VERSION "created by canmatrix"

NS_ :

BS_:

BU_: BDC_Body CHC DME1 EME FLA NiVi ZGW Kombi Kombi_Basis Diagnosetool_FA_CAN CDC_ZGW DME2 ELV Gliwa_T1_Host FA_CAN_Dummy

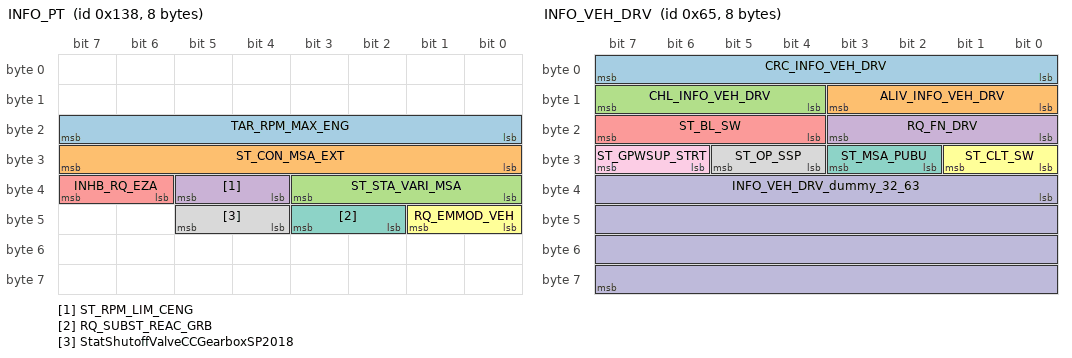
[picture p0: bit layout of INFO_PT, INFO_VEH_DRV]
BO_ 312 INFO_PT: 8 DME1
 SG_ TAR_RPM_MAX_ENG : 16|8@1+ (50,0) [0|630000] "1/min" Vector__XXX
 SG_ ST_CON_MSA_EXT : 24|8@1+ (1,0) [0|255] "" Vector__XXX
 SG_ ST_STA_VARI_MSA : 32|4@1+ (1,0) [0|15] "" Vector__XXX
 SG_ ST_RPM_LIM_CENG : 36|2@1+ (1,0) [0|3] "" Vector__XXX
 SG_ INHB_RQ_EZA : 38|2@1+ (1,0) [0|3] "" Vector__XXX
 SG_ RQ_EMMOD_VEH : 40|2@1+ (1,0) [0|3] "" BDC_Body
 SG_ RQ_SUBST_REAC_GRB : 42|2@1+ (1,0) [0|3] "" Vector__XXX
 SG_ StatShutoffValveCCGearboxSP2018 : 44|2@1+ (1,0) [0|3] "" Vector__XXX

BO_ 101 INFO_VEH_DRV: 8 BDC_Body
 SG_ CRC_INFO_VEH_DRV : 0|8@1+ (1,0) [0|255] "This unit fulfills the required AUTOSAR reference to a unit. No real unit is defined." Vector__XXX
 SG_ ALIV_INFO_VEH_DRV : 8|4@1+ (1,0) [0|14] "This unit fulfills the required AUTOSAR reference to a unit. No real unit is defined." Vector__XXX
 SG_ CHL_INFO_VEH_DRV : 12|4@1+ (1,0) [0|14] "This unit fulfills the required AUTOSAR reference to a unit. No real unit is defined." Vector__XXX
 SG_ RQ_FN_DRV : 16|4@1+ (1,0) [0|15] "" Vector__XXX
 SG_ ST_BL_SW : 20|4@1+ (1,0) [0|15] "" Vector__XXX
 SG_ ST_CLT_SW : 24|2@1+ (1,0) [0|3] "" Vector__XXX
 SG_ ST_MSA_PUBU : 26|2@1+ (1,0) [0|3] "" Vector__XXX
 SG_ ST_OP_SSP : 28|2@1+ (1,0) [0|3] "" Vector__XXX
 SG_ ST_GPWSUP_STRT : 30|2@1+ (1,0) [0|3] "" Vector__XXX
 SG_ INFO_VEH_DRV_dummy_32_63 : 32|32@1+ (1,0) [-2147483648|2147483647] "" Vector__XXX

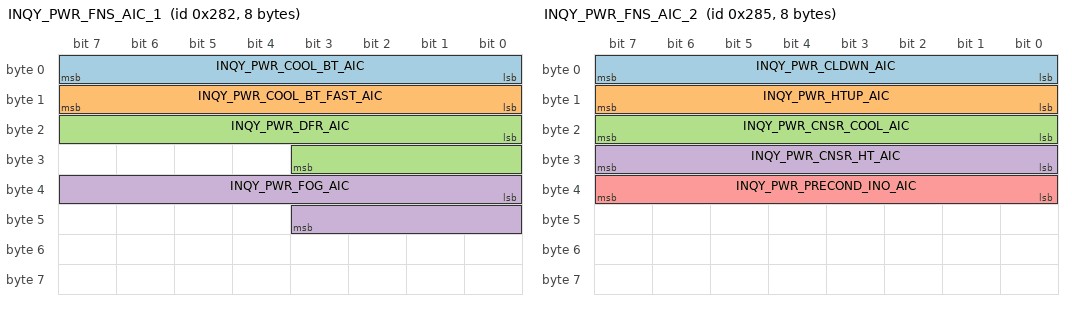
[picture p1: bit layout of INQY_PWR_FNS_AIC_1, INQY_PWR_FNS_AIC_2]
BO_ 642 INQY_PWR_FNS_AIC_1: 8 ZGW
 SG_ INQY_PWR_COOL_BT_AIC : 0|8@1+ (25,0) [0|157500] "W" EME
 SG_ INQY_PWR_COOL_BT_FAST_AIC : 8|8@1+ (25,0) [0|157500] "W" EME
 SG_ INQY_PWR_DFR_AIC : 16|12@1+ (25,0) [0|2557500] "W" EME
 SG_ INQY_PWR_FOG_AIC : 32|12@1+ (25,0) [0|2557500] "W" EME

BO_ 645 INQY_PWR_FNS_AIC_2: 8 ZGW
 SG_ INQY_PWR_CLDWN_AIC : 0|8@1+ (25,0) [0|157500] "W" EME
 SG_ INQY_PWR_HTUP_AIC : 8|8@1+ (25,0) [0|157500] "W" EME
 SG_ INQY_PWR_CNSR_COOL_AIC : 16|8@1+ (25,0) [0|157500] "W" EME
 SG_ INQY_PWR_CNSR_HT_AIC : 24|8@1+ (25,0) [0|157500] "W" EME
 SG_ INQY_PWR_PRECOND_INO_AIC : 32|8@1+ (25,0) [0|157500] "W" EME

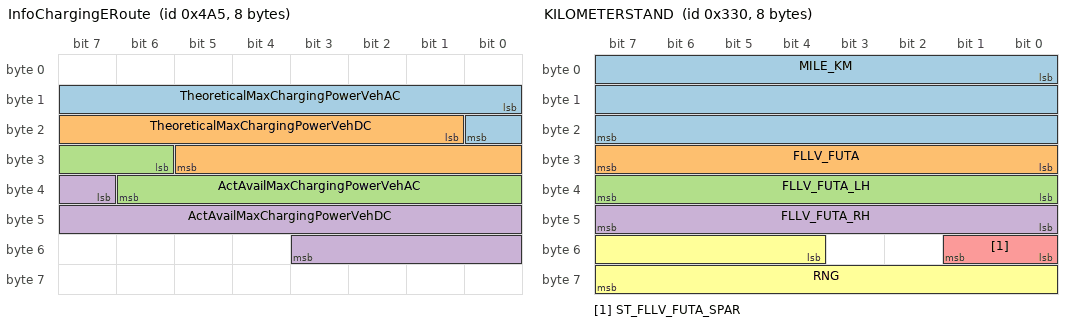
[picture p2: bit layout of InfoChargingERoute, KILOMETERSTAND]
BO_ 1189 InfoChargingERoute: 8 Vector__XXX
 SG_ TheoreticalMaxChargingPowerVehAC : 8|9@1+ (0.1,0) [0|5] "kW" Kombi
 SG_ TheoreticalMaxChargingPowerVehDC : 17|13@1+ (0.1,0) [0|50] "kW" Kombi
 SG_ ActAvailMaxChargingPowerVehAC : 30|9@1+ (0.1,0) [0|5] "kW" Kombi
 SG_ ActAvailMaxChargingPowerVehDC : 39|13@1+ (0.1,0) [0|50] "kW" Kombi

BO_ 816 KILOMETERSTAND: 8 Kombi
 SG_ MILE_KM : 0|24@1+ (1,0) [0|16777214] "km" CDC_ZGW,BDC_Body,FLA,ELV,EME,DME2,DME1,CHC,ZGW,NiVi
 SG_ FLLV_FUTA : 24|8@1+ (1,0) [0|254] "l" BDC_Body,EME,DME2,DME1,ZGW
 SG_ FLLV_FUTA_LH : 32|8@1+ (0.5,0) [0|63.5] "l" ZGW,DME2,DME1
 SG_ FLLV_FUTA_RH : 40|8@1+ (0.5,0) [0|63.5] "l" ZGW,DME2,DME1
 SG_ ST_FLLV_FUTA_SPAR : 48|2@1+ (1,0) [0|3] "" ZGW,DME2,DME1
 SG_ RNG : 52|12@1+ (1,0) [0|4094] "km" CDC_ZGW,BDC_Body,EME,DME2,DME1,ZGW

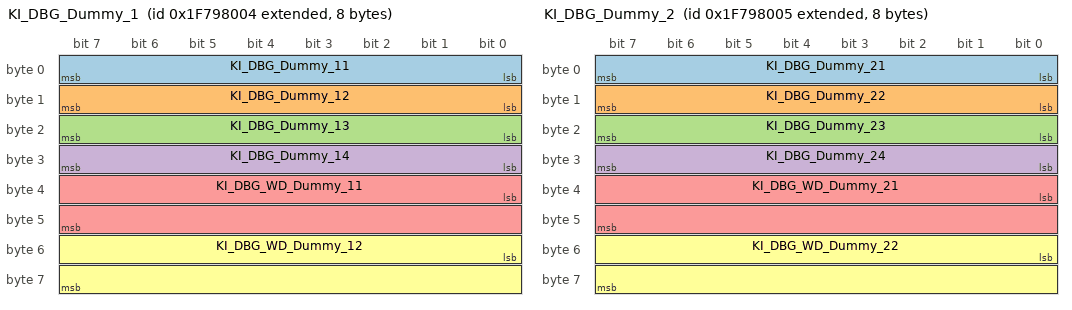
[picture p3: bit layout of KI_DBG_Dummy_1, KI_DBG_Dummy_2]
BO_ 2675539972 KI_DBG_Dummy_1: 8 Kombi
 SG_ KI_DBG_Dummy_11 : 0|8@1+ (1,0) [0|252] "This unit fulfills the required AUTOSAR reference to a unit. No real unit is defined." Vector__XXX
 SG_ KI_DBG_Dummy_12 : 8|8@1+ (1,0) [0|252] "This unit fulfills the required AUTOSAR reference to a unit. No real unit is defined." Vector__XXX
 SG_ KI_DBG_Dummy_13 : 16|8@1+ (1,0) [0|252] "This unit fulfills the required AUTOSAR reference to a unit. No real unit is defined." Vector__XXX
 SG_ KI_DBG_Dummy_14 : 24|8@1+ (1,0) [0|252] "This unit fulfills the required AUTOSAR reference to a unit. No real unit is defined." Vector__XXX
 SG_ KI_DBG_WD_Dummy_11 : 32|16@1+ (1,0) [0|65532] "This unit fulfills the required AUTOSAR reference to a unit. No real unit is defined." Vector__XXX
 SG_ KI_DBG_WD_Dummy_12 : 48|16@1+ (1,0) [0|65532] "This unit fulfills the required AUTOSAR reference to a unit. No real unit is defined." Vector__XXX

BO_ 2675539973 KI_DBG_Dummy_2: 8 Kombi
 SG_ KI_DBG_Dummy_21 : 0|8@1+ (1,0) [0|252] "This unit fulfills the required AUTOSAR reference to a unit. No real unit is defined." Vector__XXX
 SG_ KI_DBG_Dummy_22 : 8|8@1+ (1,0) [0|252] "This unit fulfills the required AUTOSAR reference to a unit. No real unit is defined." Vector__XXX
 SG_ KI_DBG_Dummy_23 : 16|8@1+ (1,0) [0|252] "This unit fulfills the required AUTOSAR reference to a unit. No real unit is defined." Vector__XXX
 SG_ KI_DBG_Dummy_24 : 24|8@1+ (1,0) [0|252] "This unit fulfills the required AUTOSAR reference to a unit. No real unit is defined." Vector__XXX
 SG_ KI_DBG_WD_Dummy_21 : 32|16@1+ (1,0) [0|65532] "This unit fulfills the required AUTOSAR reference to a unit. No real unit is defined." Vector__XXX
 SG_ KI_DBG_WD_Dummy_22 : 48|16@1+ (1,0) [0|65532] "This unit fulfills the required AUTOSAR reference to a unit. No real unit is defined." Vector__XXX

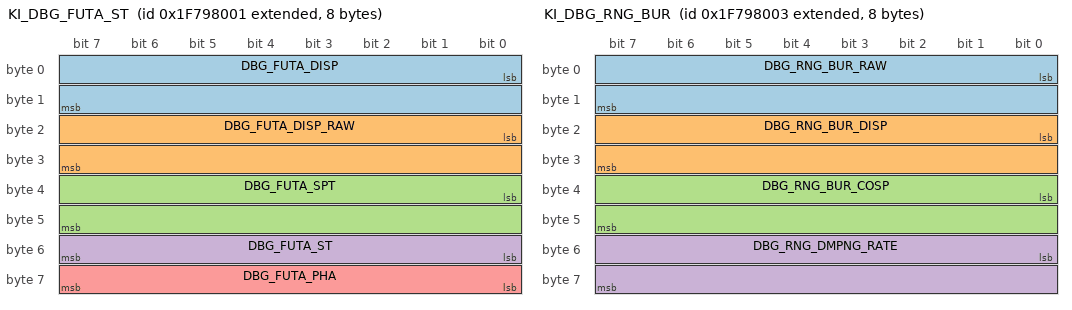
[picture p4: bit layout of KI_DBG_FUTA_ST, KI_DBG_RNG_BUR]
BO_ 2675539969 KI_DBG_FUTA_ST: 8 Kombi
 SG_ DBG_FUTA_DISP : 0|16@1+ (0.0078125,0) [0E-007|0.9921875] "l" Vector__XXX
 SG_ DBG_FUTA_DISP_RAW : 16|16@1+ (0.0078125,0) [0E-007|0.9921875] "l" Vector__XXX
 SG_ DBG_FUTA_SPT : 32|16@1+ (0.0078125,0) [0E-007|0.9921875] "l" Vector__XXX
 SG_ DBG_FUTA_ST : 48|8@1+ (1,0) [0|255] "" Vector__XXX
 SG_ DBG_FUTA_PHA : 56|8@1+ (1,0) [0|255] "" Vector__XXX

BO_ 2675539971 KI_DBG_RNG_BUR: 8 Kombi
 SG_ DBG_RNG_BUR_RAW : 0|16@1+ (1,0) [0|65532] "km" Vector__XXX
 SG_ DBG_RNG_BUR_DISP : 16|16@1+ (1,0) [0|65532] "km" Vector__XXX
 SG_ DBG_RNG_BUR_COSP : 32|16@1+ (0.001,0) [0.000|0.065532] "l/100km" Vector__XXX
 SG_ DBG_RNG_DMPNG_RATE : 48|16@1+ (1,0) [0|65532] "This unit fulfills the required AUTOSAR reference to a unit. No real unit is defined." Vector__XXX

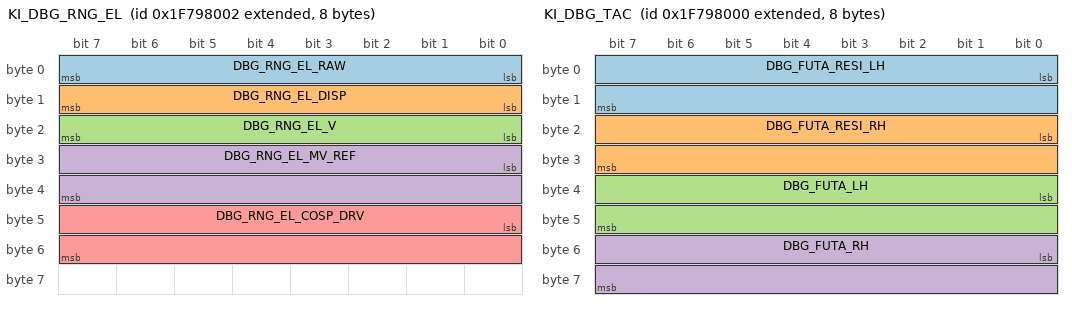
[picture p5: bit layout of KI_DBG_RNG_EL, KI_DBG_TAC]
BO_ 2675539970 KI_DBG_RNG_EL: 8 Kombi
 SG_ DBG_RNG_EL_RAW : 0|8@1+ (1,0) [0|252] "km" Vector__XXX
 SG_ DBG_RNG_EL_DISP : 8|8@1+ (1,0) [0|252] "km" Vector__XXX
 SG_ DBG_RNG_EL_V : 16|8@1+ (1,0) [0|252] "km" Vector__XXX
 SG_ DBG_RNG_EL_MV_REF : 24|16@1+ (1,0) [0|65532] "This unit fulfills the required AUTOSAR reference to a unit. No real unit is defined." Vector__XXX
 SG_ DBG_RNG_EL_COSP_DRV : 40|16@1+ (0.01,0) [0.00|6.5532] "Wh/km" Vector__XXX

BO_ 2675539968 KI_DBG_TAC: 8 Kombi
 SG_ DBG_FUTA_RESI_LH : 0|16@1+ (0.1,0) [0|655.3] "Ohm" Vector__XXX
 SG_ DBG_FUTA_RESI_RH : 16|16@1+ (0.1,0) [0|655.3] "Ohm" Vector__XXX
 SG_ DBG_FUTA_LH : 32|16@1+ (0.0078125,0) [0E-007|0.9921875] "l" Vector__XXX
 SG_ DBG_FUTA_RH : 48|16@1+ (0.0078125,0) [0E-007|0.9921875] "l" Vector__XXX

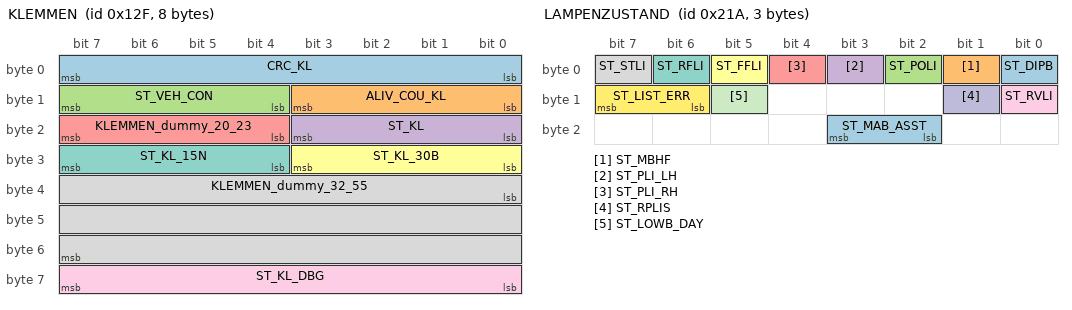
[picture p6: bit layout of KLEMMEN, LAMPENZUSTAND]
BO_ 303 KLEMMEN: 8 BDC_Body
 SG_ CRC_KL : 0|8@1+ (1,0) [0|255] "This unit fulfills the required AUTOSAR reference to a unit. No real unit is defined." Vector__XXX
 SG_ ALIV_COU_KL : 8|4@1+ (1,0) [0|15] "" Vector__XXX
 SG_ ST_VEH_CON : 12|4@1+ (1,0) [0|15] "" Vector__XXX
 SG_ ST_KL : 16|4@1+ (1,0) [0|15] "" Vector__XXX
 SG_ KLEMMEN_dummy_20_23 : 20|4@1+ (1,0) [-8|7] "" Vector__XXX
 SG_ ST_KL_30B : 24|4@1+ (1,0) [0|15] "" Vector__XXX
 SG_ ST_KL_15N : 28|4@1+ (1,0) [0|15] "" Vector__XXX
 SG_ KLEMMEN_dummy_32_55 : 32|24@1+ (1,0) [-8388608|8388607] "" Vector__XXX
 SG_ ST_KL_DBG : 56|8@1+ (1,0) [0|254] "This unit fulfills the required AUTOSAR reference to a unit. No real unit is defined." Vector__XXX

BO_ 413 Kilometerstand_2: 8 Kombi
 SG_ MILE_KM_TOT : 0|32@1+ (0.001,0) [0.000|4294.967292] "km" ZGW,DME2,DME1

BO_ 538 LAMPENZUSTAND: 3 BDC_Body
 SG_ ST_DIPB : 0|1@1+ (1,0) [0|1] "" ZGW,NiVi
 SG_ ST_MBHF : 1|1@1+ (1,0) [0|1] "" ZGW,Kombi,Kombi_Basis,NiVi
 SG_ ST_POLI : 2|1@1+ (1,0) [0|1] "" ZGW,Kombi,Kombi_Basis
 SG_ ST_PLI_LH : 3|1@1+ (1,0) [0|1] "" ZGW
 SG_ ST_PLI_RH : 4|1@1+ (1,0) [0|1] "" ZGW
 SG_ ST_FFLI : 5|1@1+ (1,0) [0|1] "" ZGW,Kombi,Kombi_Basis
 SG_ ST_RFLI : 6|1@1+ (1,0) [0|1] "" ZGW,Kombi,Kombi_Basis
 SG_ ST_STLI : 7|1@1+ (1,0) [0|1] "" ZGW
 SG_ ST_RVLI : 8|1@1+ (1,0) [0|1] "" ZGW
 SG_ ST_RPLIS : 9|1@1+ (1,0) [0|1] "" ZGW
 SG_ ST_LOWB_DAY : 13|1@1+ (1,0) [0|1] "" ZGW
 SG_ ST_LIST_ERR : 14|2@1+ (1,0) [0|3] "" ZGW
 SG_ ST_MAB_ASST : 18|2@1+ (1,0) [0|3] "" Kombi,Kombi_Basis

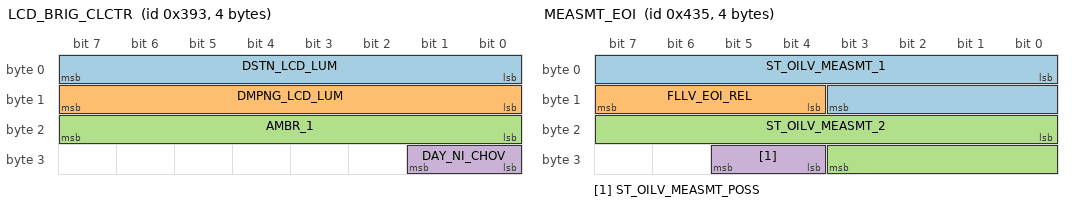
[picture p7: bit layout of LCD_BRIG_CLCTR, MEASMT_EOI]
BO_ 915 LCD_BRIG_CLCTR: 4 Kombi
 SG_ DSTN_LCD_LUM : 0|8@1+ (1,0) [0|254] "This unit fulfills the required AUTOSAR reference to a unit. No real unit is defined." ZGW,BDC_Body,CHC,DME1
 SG_ DMPNG_LCD_LUM : 8|8@1+ (2,100) [300|1260] "ms" ZGW,BDC_Body,CHC,DME1
 SG_ AMBR_1 : 16|8@1+ (1,0) [0|254] "This unit fulfills the required AUTOSAR reference to a unit. No real unit is defined." ZGW
 SG_ DAY_NI_CHOV : 24|2@1+ (1,0) [0|3] "" ZGW,BDC_Body

BO_ 577 LST_CHGSTN_IDT_CHGNG: 8 EME
 SG_ Multiplexor M : 0|8@1+ (1,0) [-128|127] "" Vector__XXX

BO_ 736 MASS_VEH: 6 ZGW
 SG_ MASS_VEH : 16|12@1+ (20,0) [0|163760] "kg" DME2,CHC,DME1
 SG_ QU_MASS_VEH : 28|4@1+ (1,0) [0|15] "" DME2,CHC,DME1

BO_ 1077 MEASMT_EOI: 4 DME1
 SG_ ST_OILV_MEASMT_1 : 0|12@1+ (1,0) [0|4095] "" ZGW
 SG_ FLLV_EOI_REL : 12|4@1+ (1,0) [0|15] "" ZGW,BDC_Body
 SG_ ST_OILV_MEASMT_2 : 16|12@1+ (1,0) [0|4095] "" ZGW
 SG_ ST_OILV_MEASMT_POSS : 28|2@1+ (1,0) [0|3] "" ZGW

BO_ 523 MEMORYVERSTELLUNG: 2 ZGW
 SG_ ST_MEMO_FN : 0|2@1+ (1,0) [0|3] "" Kombi
 SG_ PO_MEMO : 8|8@1+ (1,0) [1|254] "This unit fulfills the required AUTOSAR reference to a unit. No real unit is defined." Kombi

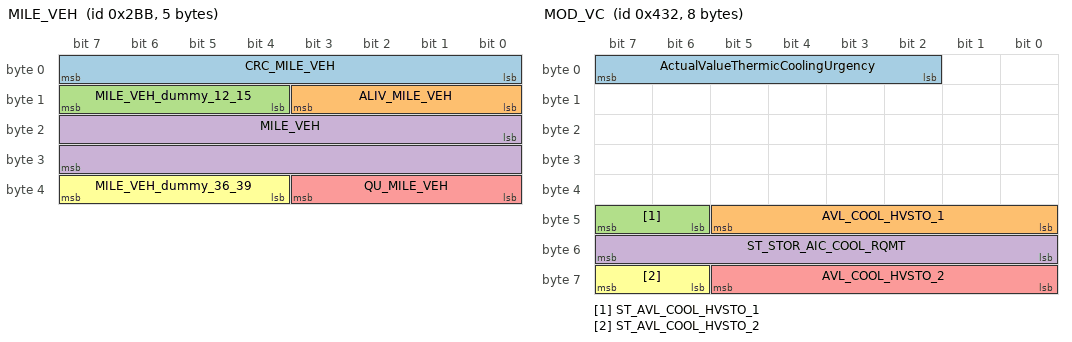
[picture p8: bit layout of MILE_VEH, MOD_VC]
BO_ 699 MILE_VEH: 5 ZGW
 SG_ CRC_MILE_VEH : 0|8@1+ (1,0) [0|255] "This unit fulfills the required AUTOSAR reference to a unit. No real unit is defined." Vector__XXX
 SG_ ALIV_MILE_VEH : 8|4@1+ (1,0) [0|14] "This unit fulfills the required AUTOSAR reference to a unit. No real unit is defined." Vector__XXX
 SG_ MILE_VEH_dummy_12_15 : 12|4@1+ (1,0) [-8|7] "" Vector__XXX
 SG_ MILE_VEH : 16|16@1+ (0.01,0) [0.00|6.5534] "m" Vector__XXX
 SG_ QU_MILE_VEH : 32|4@1+ (1,0) [0|15] "" Vector__XXX
 SG_ MILE_VEH_dummy_36_39 : 36|4@1+ (1,0) [-8|7] "" Vector__XXX

BO_ 1074 MOD_VC: 8 EME
 SG_ ActualValueThermicCoolingUrgency : 2|6@1+ (2,0) [0|200] "%" ZGW
 SG_ AVL_COOL_HVSTO_1 : 40|6@1+ (250,0) [0|3750000] "W" ZGW
 SG_ ST_AVL_COOL_HVSTO_1 : 46|2@1+ (1,0) [0|3] "" ZGW
 SG_ ST_STOR_AIC_COOL_RQMT : 48|8@1+ (20,0) [0|100800] "W" ZGW
 SG_ AVL_COOL_HVSTO_2 : 56|6@1+ (250,0) [0|3750000] "W" ZGW
 SG_ ST_AVL_COOL_HVSTO_2 : 62|2@1+ (1,0) [0|3] "" ZGW

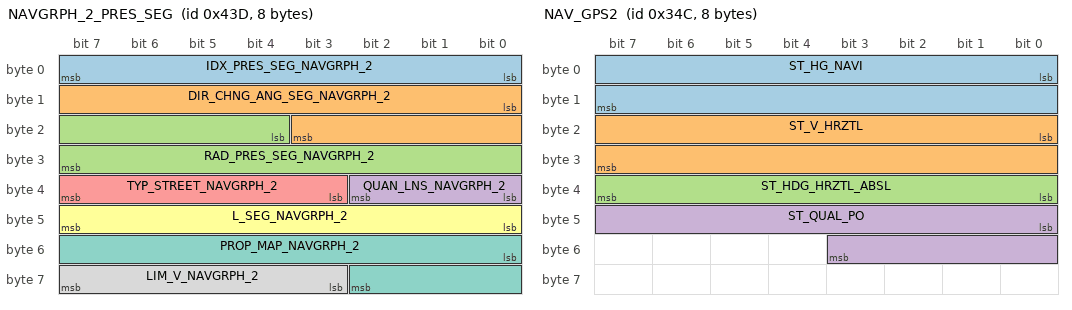
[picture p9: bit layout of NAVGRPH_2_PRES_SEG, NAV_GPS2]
BO_ 1085 NAVGRPH_2_PRES_SEG: 8 ZGW
 SG_ IDX_PRES_SEG_NAVGRPH_2 : 0|8@1+ (1,0) [0|254] "This unit fulfills the required AUTOSAR reference to a unit. No real unit is defined." BDC_Body
 SG_ DIR_CHNG_ANG_SEG_NAVGRPH_2 : 8|12@1+ (0.08793356,-180) [-195.82804080|-164.17195920] "°" BDC_Body
 SG_ RAD_PRES_SEG_NAVGRPH_2 : 20|12@1+ (5,-10230) [-61380|40970] "m" BDC_Body
 SG_ QUAN_LNS_NAVGRPH_2 : 32|3@1+ (1,0) [0|7] "" BDC_Body
 SG_ TYP_STREET_NAVGRPH_2 : 35|5@1+ (1,0) [0|31] "" BDC_Body
 SG_ L_SEG_NAVGRPH_2 : 40|8@1+ (1,0) [0|254] "m" BDC_Body
 SG_ PROP_MAP_NAVGRPH_2 : 48|11@1+ (1,0) [0|2047] "" BDC_Body
 SG_ LIM_V_NAVGRPH_2 : 59|5@1+ (1,0) [0|31] "" BDC_Body

BO_ 842 NAV_GPS1: 8 ZGW
 SG_ ST_LONG_NAVI : 0|32@1+ (8.38190318E-008,0) [-0.0000150874257240|0.00001509580762718] "°" NiVi,BDC_Body,DME2,DME1
 SG_ ST_LAT_NAVI : 32|32@1+ (8.38190318E-008,0) [-0.0000075437128620|0.00001509580762718] "°" NiVi,BDC_Body,DME2,DME1

BO_ 844 NAV_GPS2: 8 ZGW
 SG_ ST_HG_NAVI : 0|16@1+ (1,0) [-32767|32766] "m" BDC_Body
 SG_ ST_V_HRZTL : 16|16@1+ (1,0) [-32767|32766] "cm/s" BDC_Body
 SG_ ST_HDG_HRZTL_ABSL : 32|8@1+ (1.5,0) [0|540] "°" NiVi,BDC_Body
 SG_ ST_QUAL_PO : 40|12@1+ (1,0) [0|4095] "" NiVi,BDC_Body

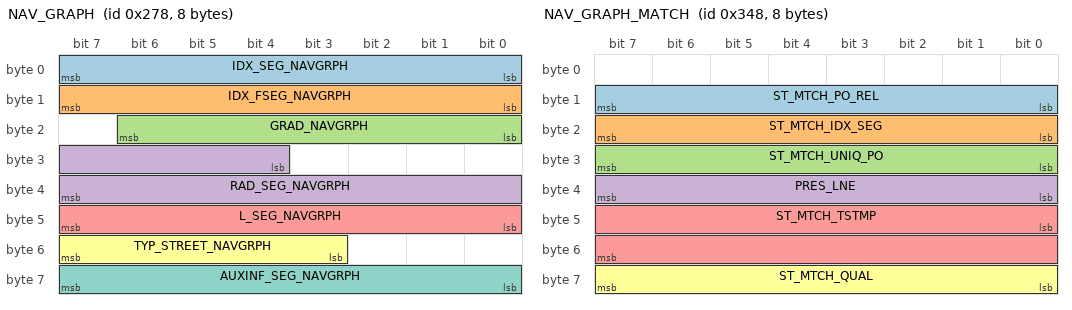
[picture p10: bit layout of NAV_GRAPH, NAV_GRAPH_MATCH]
BO_ 632 NAV_GRAPH: 8 ZGW
 SG_ IDX_SEG_NAVGRPH : 0|8@1+ (1,0) [0|254] "This unit fulfills the required AUTOSAR reference to a unit. No real unit is defined." NiVi
 SG_ IDX_FSEG_NAVGRPH : 8|8@1+ (1,0) [0|254] "This unit fulfills the required AUTOSAR reference to a unit. No real unit is defined." NiVi
 SG_ GRAD_NAVGRPH : 16|7@1+ (1,0) [0|126] "This unit fulfills the required AUTOSAR reference to a unit. No real unit is defined." NiVi
 SG_ RAD_SEG_NAVGRPH : 28|12@1+ (1,0) [-2047|2047] "This unit fulfills the required AUTOSAR reference to a unit. No real unit is defined." NiVi
 SG_ L_SEG_NAVGRPH : 40|8@1+ (1,0) [0|254] "m" NiVi
 SG_ TYP_STREET_NAVGRPH : 51|5@1+ (1,0) [0|31] "" NiVi
 SG_ AUXINF_SEG_NAVGRPH : 56|8@1+ (1,0) [0|255] "" NiVi

BO_ 840 NAV_GRAPH_MATCH: 8 ZGW
 SG_ ST_MTCH_PO_REL : 8|8@1+ (1,0) [0|254] "m" NiVi
 SG_ ST_MTCH_IDX_SEG : 16|8@1+ (1,0) [0|254] "This unit fulfills the required AUTOSAR reference to a unit. No real unit is defined." NiVi
 SG_ ST_MTCH_UNIQ_PO : 24|8@1+ (0.3937,0) [0.0000|39.36992126] "%" NiVi
 SG_ PRES_LNE : 32|8@1+ (1,0) [0|255] "" NiVi
 SG_ ST_MTCH_TSTMP : 40|16@1+ (1,0) [0|65534] "ms" NiVi
 SG_ ST_MTCH_QUAL : 56|8@1+ (0.3937,0) [0.0000|39.36992126] "%" NiVi

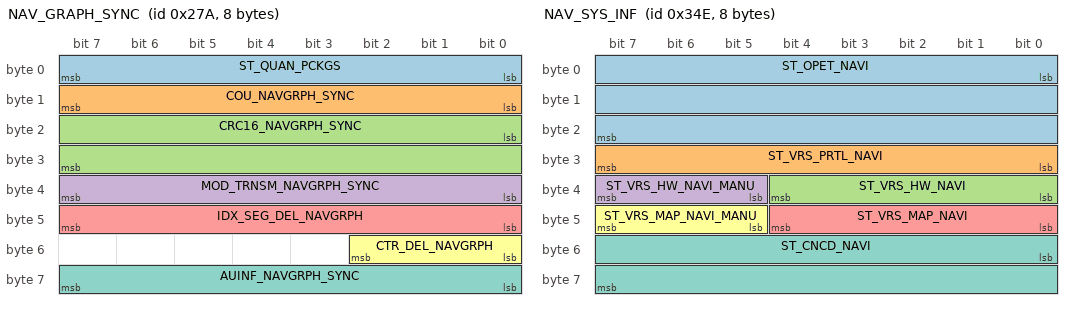
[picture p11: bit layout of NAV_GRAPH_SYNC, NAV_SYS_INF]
BO_ 634 NAV_GRAPH_SYNC: 8 ZGW
 SG_ ST_QUAN_PCKGS : 0|8@1+ (1,0) [0|254] "This unit fulfills the required AUTOSAR reference to a unit. No real unit is defined." NiVi
 SG_ COU_NAVGRPH_SYNC : 8|8@1+ (1,0) [0|254] "This unit fulfills the required AUTOSAR reference to a unit. No real unit is defined." NiVi
 SG_ CRC16_NAVGRPH_SYNC : 16|16@1+ (1,0) [0|65534] "This unit fulfills the required AUTOSAR reference to a unit. No real unit is defined." NiVi
 SG_ MOD_TRNSM_NAVGRPH_SYNC : 32|8@1+ (1,0) [0|254] "This unit fulfills the required AUTOSAR reference to a unit. No real unit is defined." NiVi
 SG_ IDX_SEG_DEL_NAVGRPH : 40|8@1+ (1,0) [0|254] "This unit fulfills the required AUTOSAR reference to a unit. No real unit is defined." NiVi
 SG_ CTR_DEL_NAVGRPH : 48|3@1+ (1,0) [0|7] "" NiVi
 SG_ AUINF_NAVGRPH_SYNC : 56|8@1+ (1,0) [0|255] "" NiVi

BO_ 846 NAV_SYS_INF: 8 ZGW
 SG_ ST_OPET_NAVI : 0|24@1+ (1,0) [0|16777214] "ms" BDC_Body,EME,DME2,DME1,NiVi
 SG_ ST_VRS_PRTL_NAVI : 24|8@1+ (1,0) [0|255] "" BDC_Body,EME,DME2,DME1,NiVi
 SG_ ST_VRS_HW_NAVI : 32|5@1+ (1,0) [0|31] "" BDC_Body,DME2,EME,DME1
 SG_ ST_VRS_HW_NAVI_MANU : 37|3@1+ (1,0) [0|7] "" BDC_Body,DME2,EME,DME1
 SG_ ST_VRS_MAP_NAVI : 40|5@1+ (1,0) [0|31] "" BDC_Body,DME2,EME,DME1
 SG_ ST_VRS_MAP_NAVI_MANU : 45|3@1+ (1,0) [0|7] "" BDC_Body,DME2,EME,DME1
 SG_ ST_CNCD_NAVI : 48|16@1+ (1,0) [0|65534] "This unit fulfills the required AUTOSAR reference to a unit. No real unit is defined." BDC_Body,EME,DME2,DME1,NiVi

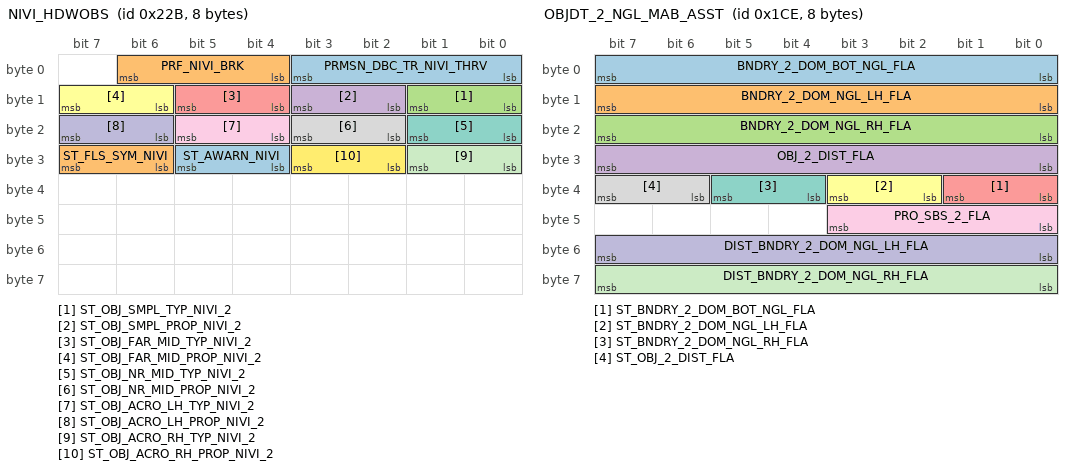
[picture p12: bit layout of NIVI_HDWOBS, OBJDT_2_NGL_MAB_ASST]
BO_ 555 NIVI_HDWOBS: 8 NiVi
 SG_ PRMSN_DBC_TR_NIVI_THRV : 0|4@1+ (1,0) [0|15] "" ZGW
 SG_ PRF_NIVI_BRK : 4|3@1+ (1,0) [0|7] "" ZGW
 SG_ ST_OBJ_SMPL_TYP_NIVI_2 : 8|2@1+ (1,0) [0|3] "" ZGW
 SG_ ST_OBJ_SMPL_PROP_NIVI_2 : 10|2@1+ (1,0) [0|3] "" ZGW
 SG_ ST_OBJ_FAR_MID_TYP_NIVI_2 : 12|2@1+ (1,0) [0|3] "" ZGW
 SG_ ST_OBJ_FAR_MID_PROP_NIVI_2 : 14|2@1+ (1,0) [0|3] "" ZGW
 SG_ ST_OBJ_NR_MID_TYP_NIVI_2 : 16|2@1+ (1,0) [0|3] "" ZGW
 SG_ ST_OBJ_NR_MID_PROP_NIVI_2 : 18|2@1+ (1,0) [0|3] "" ZGW
 SG_ ST_OBJ_ACRO_LH_TYP_NIVI_2 : 20|2@1+ (1,0) [0|3] "" ZGW
 SG_ ST_OBJ_ACRO_LH_PROP_NIVI_2 : 22|2@1+ (1,0) [0|3] "" ZGW
 SG_ ST_OBJ_ACRO_RH_TYP_NIVI_2 : 24|2@1+ (1,0) [0|3] "" ZGW
 SG_ ST_OBJ_ACRO_RH_PROP_NIVI_2 : 26|2@1+ (1,0) [0|3] "" ZGW
 SG_ ST_AWARN_NIVI : 28|2@1+ (1,0) [0|3] "" ZGW
 SG_ ST_FLS_SYM_NIVI : 30|2@1+ (1,0) [0|3] "" ZGW

BO_ 2024 OBD_ANSW_ECU_1: 8 DME1

BO_ 2025 OBD_ANSW_ECU_2: 8 DME1

BO_ 2026 OBD_ANSW_ECU_3: 8 DME1

BO_ 2027 OBD_ANSW_ECU_4: 8 DME1

BO_ 2028 OBD_ANSW_ECU_5: 8 DME1

BO_ 2029 OBD_ANSW_ECU_6: 8 DME1

BO_ 2030 OBD_ANSW_ECU_7: 8 DME1

BO_ 2031 OBD_ANSW_ECU_8: 8 DME1

BO_ 2016 OBD_RQ_ECU_1: 8 ZGW

BO_ 2017 OBD_RQ_ECU_2: 8 ZGW

BO_ 2018 OBD_RQ_ECU_3: 8 ZGW

BO_ 2019 OBD_RQ_ECU_4: 8 ZGW

BO_ 2020 OBD_RQ_ECU_5: 8 ZGW

BO_ 2021 OBD_RQ_ECU_6: 8 ZGW

BO_ 2022 OBD_RQ_ECU_7: 8 ZGW

BO_ 2023 OBD_RQ_ECU_8: 8 ZGW

BO_ 2015 OBD_RQ_FN: 8 ZGW

BO_ 462 OBJDT_2_NGL_MAB_ASST: 8 ZGW
 SG_ BNDRY_2_DOM_BOT_NGL_FLA : 0|8@1+ (0.05,-5) [-5.25|-4.75] "°" NiVi,BDC_Body
 SG_ BNDRY_2_DOM_NGL_LH_FLA : 8|8@1+ (0.1,-10.4) [-11.44|-8.9] "°" NiVi,BDC_Body
 SG_ BNDRY_2_DOM_NGL_RH_FLA : 16|8@1+ (0.1,-15) [-16.5|-13.96] "°" NiVi,BDC_Body
 SG_ OBJ_2_DIST_FLA : 24|8@1+ (1,0) [0|150] "m" NiVi,BDC_Body
 SG_ ST_BNDRY_2_DOM_BOT_NGL_FLA : 32|2@1+ (1,0) [0|3] "" NiVi,BDC_Body
 SG_ ST_BNDRY_2_DOM_NGL_LH_FLA : 34|2@1+ (1,0) [0|3] "" NiVi,BDC_Body
 SG_ ST_BNDRY_2_DOM_NGL_RH_FLA : 36|2@1+ (1,0) [0|3] "" NiVi,BDC_Body
 SG_ ST_OBJ_2_DIST_FLA : 38|2@1+ (1,0) [0|3] "" NiVi,BDC_Body
 SG_ PRO_SBS_2_FLA : 40|4@1+ (0.1,0) [0|0.1] "This unit fulfills the required AUTOSAR reference to a unit. No real unit is defined." NiVi,BDC_Body
 SG_ DIST_BNDRY_2_DOM_NGL_LH_FLA : 48|8@1+ (1,0) [0|252] "m" BDC_Body
 SG_ DIST_BNDRY_2_DOM_NGL_RH_FLA : 56|8@1+ (1,0) [0|252] "m" BDC_Body

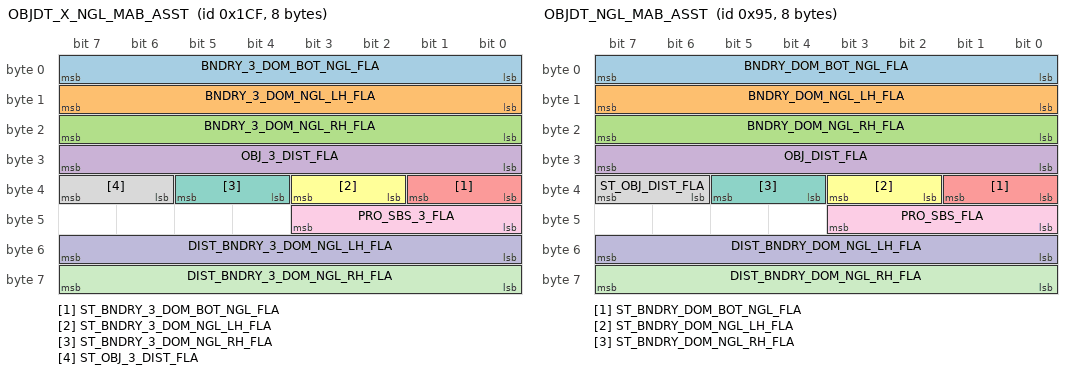
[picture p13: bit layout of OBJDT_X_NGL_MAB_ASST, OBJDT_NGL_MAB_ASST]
BO_ 463 OBJDT_X_NGL_MAB_ASST: 8 ZGW
 SG_ BNDRY_3_DOM_BOT_NGL_FLA : 0|8@1+ (0.05,-5) [-5.25|-4.75] "°" NiVi,BDC_Body
 SG_ BNDRY_3_DOM_NGL_LH_FLA : 8|8@1+ (0.1,-10.4) [-11.44|-8.9] "°" NiVi,BDC_Body
 SG_ BNDRY_3_DOM_NGL_RH_FLA : 16|8@1+ (0.1,-15) [-16.5|-13.96] "°" NiVi,BDC_Body
 SG_ OBJ_3_DIST_FLA : 24|8@1+ (1,0) [0|150] "m" NiVi,BDC_Body
 SG_ ST_BNDRY_3_DOM_BOT_NGL_FLA : 32|2@1+ (1,0) [0|3] "" NiVi,BDC_Body
 SG_ ST_BNDRY_3_DOM_NGL_LH_FLA : 34|2@1+ (1,0) [0|3] "" NiVi,BDC_Body
 SG_ ST_BNDRY_3_DOM_NGL_RH_FLA : 36|2@1+ (1,0) [0|3] "" NiVi,BDC_Body
 SG_ ST_OBJ_3_DIST_FLA : 38|2@1+ (1,0) [0|3] "" NiVi,BDC_Body
 SG_ PRO_SBS_3_FLA : 40|4@1+ (0.1,0) [0|0.1] "This unit fulfills the required AUTOSAR reference to a unit. No real unit is defined." NiVi,BDC_Body
 SG_ DIST_BNDRY_3_DOM_NGL_LH_FLA : 48|8@1+ (1,0) [0|252] "m" BDC_Body
 SG_ DIST_BNDRY_3_DOM_NGL_RH_FLA : 56|8@1+ (1,0) [0|252] "m" BDC_Body

BO_ 149 OBJDT_NGL_MAB_ASST: 8 FLA
 SG_ BNDRY_DOM_BOT_NGL_FLA : 0|8@1+ (0.05,-5) [-5.25|-4.75] "°" NiVi,BDC_Body
 SG_ BNDRY_DOM_NGL_LH_FLA : 8|8@1+ (0.1,-10.4) [-11.44|-8.9] "°" NiVi,BDC_Body
 SG_ BNDRY_DOM_NGL_RH_FLA : 16|8@1+ (0.1,-15) [-16.5|-13.96] "°" NiVi,BDC_Body
 SG_ OBJ_DIST_FLA : 24|8@1+ (1,0) [0|150] "m" NiVi,BDC_Body
 SG_ ST_BNDRY_DOM_BOT_NGL_FLA : 32|2@1+ (1,0) [0|3] "" NiVi,BDC_Body
 SG_ ST_BNDRY_DOM_NGL_LH_FLA : 34|2@1+ (1,0) [0|3] "" NiVi,BDC_Body
 SG_ ST_BNDRY_DOM_NGL_RH_FLA : 36|2@1+ (1,0) [0|3] "" NiVi,BDC_Body
 SG_ ST_OBJ_DIST_FLA : 38|2@1+ (1,0) [0|3] "" NiVi,BDC_Body
 SG_ PRO_SBS_FLA : 40|4@1+ (0.1,0) [0|0.1] "This unit fulfills the required AUTOSAR reference to a unit. No real unit is defined." NiVi,BDC_Body
 SG_ DIST_BNDRY_DOM_NGL_LH_FLA : 48|8@1+ (1,0) [0|252] "m" BDC_Body
 SG_ DIST_BNDRY_DOM_NGL_RH_FLA : 56|8@1+ (1,0) [0|252] "m" BDC_Body

BO_ 393 OP_CCTR: 6 ZGW
 SG_ OP_CCTR_OPEL_3 : 24|4@1+ (1,0) [0|15] "" DME1
 SG_ QU_SER_OP_CCTR : 40|8@1+ (1,0) [0|255] "" DME1

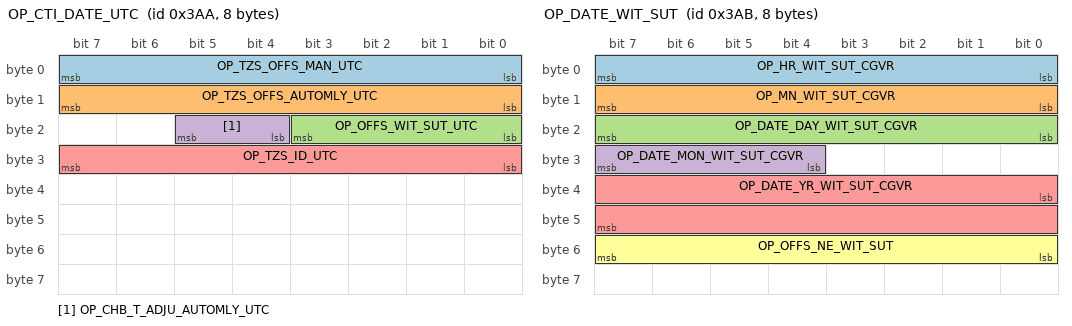
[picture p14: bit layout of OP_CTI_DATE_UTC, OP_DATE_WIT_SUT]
BO_ 938 OP_CTI_DATE_UTC: 8 ZGW
 SG_ OP_TZS_OFFS_MAN_UTC : 0|8@1+ (0.25,-20) [-25.00|-9.3125] "h" Kombi,Kombi_Basis
 SG_ OP_TZS_OFFS_AUTOMLY_UTC : 8|8@1+ (0.25,-20) [-25.00|-9.3125] "h" Kombi,Kombi_Basis
 SG_ OP_OFFS_WIT_SUT_UTC : 16|4@1+ (0.5,-3) [-4.5|-1.75] "h" Kombi,Kombi_Basis
 SG_ OP_CHB_T_ADJU_AUTOMLY_UTC : 20|2@1+ (1,0) [0|3] "" Kombi,Kombi_Basis
 SG_ OP_TZS_ID_UTC : 24|8@1+ (1,0) [0|251] "This unit fulfills the required AUTOSAR reference to a unit. No real unit is defined." Kombi,Kombi_Basis

BO_ 939 OP_DATE_WIT_SUT: 8 ZGW
 SG_ OP_HR_WIT_SUT_CGVR : 0|8@1+ (1,0) [0|251] "h" Kombi,Kombi_Basis
 SG_ OP_MN_WIT_SUT_CGVR : 8|8@1+ (1,0) [0|59] "min" Kombi,Kombi_Basis
 SG_ OP_DATE_DAY_WIT_SUT_CGVR : 16|8@1+ (1,0) [0|31] "This unit fulfills the required AUTOSAR reference to a unit. No real unit is defined." Kombi,Kombi_Basis
 SG_ OP_DATE_MON_WIT_SUT_CGVR : 28|4@1+ (1,0) [1|12] "This unit fulfills the required AUTOSAR reference to a unit. No real unit is defined." Kombi,Kombi_Basis
 SG_ OP_DATE_YR_WIT_SUT_CGVR : 32|16@1+ (1,0) [0|65531] "This unit fulfills the required AUTOSAR reference to a unit. No real unit is defined." Kombi,Kombi_Basis
 SG_ OP_OFFS_NE_WIT_SUT : 48|8@1+ (0.25,-20) [-25.00|-9.25] "h" Kombi,Kombi_Basis

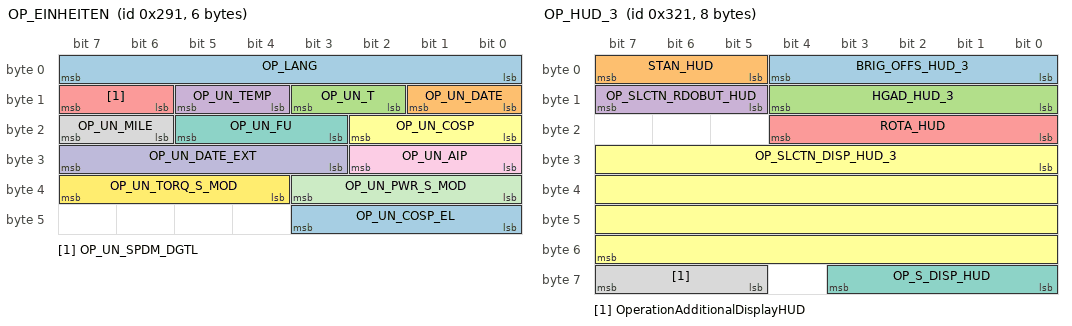
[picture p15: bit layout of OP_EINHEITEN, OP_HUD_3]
BO_ 657 OP_EINHEITEN: 6 ZGW
 SG_ OP_LANG : 0|8@1+ (1,0) [0|255] "" Kombi,Kombi_Basis
 SG_ OP_UN_DATE : 8|2@1+ (1,0) [0|3] "" Kombi,Kombi_Basis
 SG_ OP_UN_T : 10|2@1+ (1,0) [0|3] "" Kombi,Kombi_Basis
 SG_ OP_UN_TEMP : 12|2@1+ (1,0) [0|3] "" Kombi,Kombi_Basis
 SG_ OP_UN_SPDM_DGTL : 14|2@1+ (1,0) [0|3] "" Kombi,Kombi_Basis
 SG_ OP_UN_COSP : 16|3@1+ (1,0) [0|7] "" Kombi,Kombi_Basis
 SG_ OP_UN_FU : 19|3@1+ (1,0) [0|7] "" Kombi,Kombi_Basis
 SG_ OP_UN_MILE : 22|2@1+ (1,0) [0|3] "" Kombi,Kombi_Basis
 SG_ OP_UN_AIP : 24|3@1+ (1,0) [0|7] "" Kombi,Kombi_Basis
 SG_ OP_UN_DATE_EXT : 27|5@1+ (1,0) [0|31] "" Kombi,Kombi_Basis
 SG_ OP_UN_PWR_S_MOD : 32|4@1+ (1,0) [0|15] "" Kombi,Kombi_Basis
 SG_ OP_UN_TORQ_S_MOD : 36|4@1+ (1,0) [0|15] "" Kombi,Kombi_Basis
 SG_ OP_UN_COSP_EL : 40|4@1+ (1,0) [0|15] "" Kombi,Kombi_Basis

BO_ 801 OP_HUD_3: 8 ZGW
 SG_ BRIG_OFFS_HUD_3 : 0|5@1+ (1,0) [0|31] "" Kombi,Kombi_Basis
 SG_ STAN_HUD : 5|3@1+ (1,0) [0|7] "" Kombi,Kombi_Basis
 SG_ HGAD_HUD_3 : 8|5@1+ (1,0) [0|31] "" Kombi,Kombi_Basis
 SG_ OP_SLCTN_RDOBUT_HUD : 13|3@1+ (1,0) [0|7] "" Kombi,Kombi_Basis
 SG_ ROTA_HUD : 16|5@1+ (1,0) [0|31] "" Kombi,Kombi_Basis
 SG_ OP_SLCTN_DISP_HUD_3 : 24|32@1+ (1,0) [0|4294967295] "" Kombi,Kombi_Basis
 SG_ OP_S_DISP_HUD : 56|4@1+ (1,0) [0|15] "" Kombi,Kombi_Basis
 SG_ OperationAdditionalDisplayHUD : 61|3@1+ (1,0) [0|7] "" Kombi,Kombi_Basis

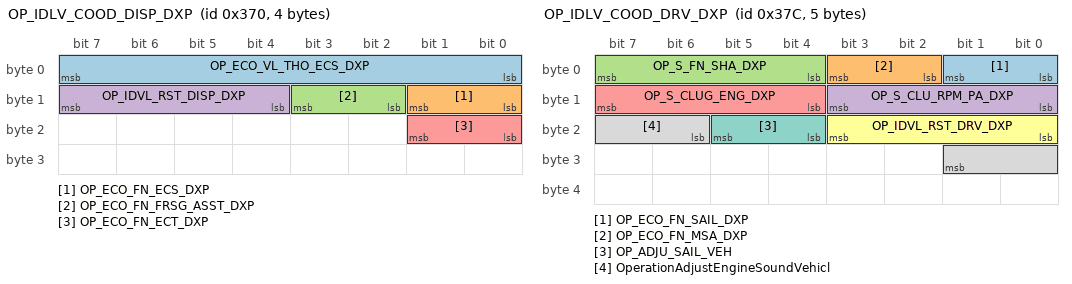
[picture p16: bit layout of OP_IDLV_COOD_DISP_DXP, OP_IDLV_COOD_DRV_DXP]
BO_ 880 OP_IDLV_COOD_DISP_DXP: 4 ZGW
 SG_ OP_ECO_VL_THO_ECS_DXP : 0|8@1+ (1,0) [0|250] "This unit fulfills the required AUTOSAR reference to a unit. No real unit is defined." Kombi,Kombi_Basis
 SG_ OP_ECO_FN_ECS_DXP : 8|2@1+ (1,0) [0|3] "" Kombi,Kombi_Basis
 SG_ OP_ECO_FN_FRSG_ASST_DXP : 10|2@1+ (1,0) [0|3] "" Kombi,Kombi_Basis
 SG_ OP_IDVL_RST_DISP_DXP : 12|4@1+ (1,0) [0|15] "" Kombi,Kombi_Basis
 SG_ OP_ECO_FN_ECT_DXP : 16|2@1+ (1,0) [0|3] "" Kombi,Kombi_Basis

BO_ 892 OP_IDLV_COOD_DRV_DXP: 5 ZGW
 SG_ OP_ECO_FN_SAIL_DXP : 0|2@1+ (1,0) [0|3] "" DME2,DME1
 SG_ OP_ECO_FN_MSA_DXP : 2|2@1+ (1,0) [0|3] "" DME2,DME1
 SG_ OP_S_FN_SHA_DXP : 4|4@1+ (1,0) [0|15] "" DME2,DME1
 SG_ OP_S_CLU_RPM_PA_DXP : 8|4@1+ (1,0) [0|15] "" DME2,DME1
 SG_ OP_S_CLUG_ENG_DXP : 12|4@1+ (1,0) [0|15] "" DME2,DME1
 SG_ OP_IDVL_RST_DRV_DXP : 16|4@1+ (1,0) [0|15] "" DME2,DME1
 SG_ OP_ADJU_SAIL_VEH : 20|2@1+ (1,0) [0|3] "" DME2,DME1
 SG_ OperationAdjustEngineSoundVehicl : 22|4@1+ (1,0) [0|15] "" DME2,DME1

BO_ 745 OP_PUBU_EVEH: 2 ZGW
 SG_ OP_PUBU_EVEH : 0|2@1+ (1,0) [0|3] "" DME2,DME1

BO_ 651 OP_PUBU_HUD: 2 BDC_Body
 SG_ OP_PUBU_HUD : 0|2@1+ (1,0) [0|3] "" Kombi,Kombi_Basis

BO_ 604 OP_PUBU_LVCH: 2 ZGW
 SG_ OP_PUBU_LVCH : 0|4@1+ (1,0) [0|15] "" CHC
 SG_ OP_PUBU_KEY : 4|2@1+ (1,0) [0|3] "" CHC

BO_ 650 OP_PUBU_NIVI: 2 BDC_Body
 SG_ OP_PUBU_NIVI : 0|2@1+ (1,0) [0|3] "" NiVi

BO_ 519 OP_SPD: 2 BDC_Body
 SG_ OP_SPD : 12|4@1+ (1,0) [0|15] "" DME1

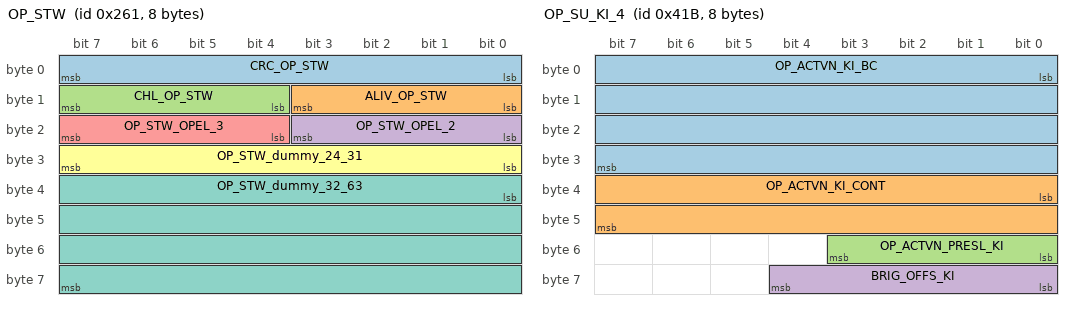
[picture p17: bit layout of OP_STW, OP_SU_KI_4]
BO_ 609 OP_STW: 8 BDC_Body
 SG_ CRC_OP_STW : 0|8@1+ (1,0) [0|255] "This unit fulfills the required AUTOSAR reference to a unit. No real unit is defined." Vector__XXX
 SG_ ALIV_OP_STW : 8|4@1+ (1,0) [0|14] "This unit fulfills the required AUTOSAR reference to a unit. No real unit is defined." Vector__XXX
 SG_ CHL_OP_STW : 12|4@1+ (1,0) [0|14] "This unit fulfills the required AUTOSAR reference to a unit. No real unit is defined." Vector__XXX
 SG_ OP_STW_OPEL_2 : 16|4@1+ (1,0) [0|15] "" Vector__XXX
 SG_ OP_STW_OPEL_3 : 20|4@1+ (1,0) [0|15] "" Vector__XXX
 SG_ OP_STW_dummy_24_31 : 24|8@1+ (1,0) [-128|127] "" Vector__XXX
 SG_ OP_STW_dummy_32_63 : 32|32@1+ (1,0) [-2147483648|2147483647] "" Vector__XXX

BO_ 727 OP_ST_CHGNG_I_LIM_2: 8 ZGW
 SG_ OP_CHGNG_I_LIM_MOD_2 : 0|8@1+ (1,0) [0|250] "A" EME
 SG_ PopUpConfirmation : 8|4@1+ (1,0) [0|15] "" EME
 SG_ OperationChargingCurrentLimitMod : 12|2@1+ (1,0) [0|3] "" EME

BO_ 1051 OP_SU_KI_4: 8 ZGW
 SG_ OP_ACTVN_KI_BC : 0|32@1+ (1,0) [0|4294967295] "" Kombi,Kombi_Basis
 SG_ OP_ACTVN_KI_CONT : 32|16@1+ (1,0) [0|65535] "" Kombi,Kombi_Basis
 SG_ OP_ACTVN_PRESL_KI : 48|4@1+ (1,0) [0|15] "" Kombi,Kombi_Basis
 SG_ BRIG_OFFS_KI : 56|5@1+ (1,0) [0|31] "" Kombi,Kombi_Basis

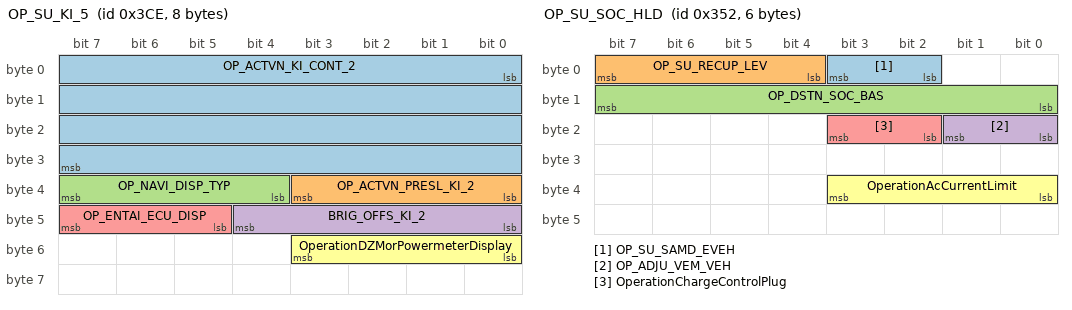
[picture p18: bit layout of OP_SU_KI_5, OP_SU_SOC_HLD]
BO_ 974 OP_SU_KI_5: 8 ZGW
 SG_ OP_ACTVN_KI_CONT_2 : 0|32@1+ (1,0) [0|4294967295] "" Kombi,Kombi_Basis
 SG_ OP_ACTVN_PRESL_KI_2 : 32|4@1+ (1,0) [0|15] "" Kombi,Kombi_Basis
 SG_ OP_NAVI_DISP_TYP : 36|4@1+ (1,0) [0|15] "" Kombi,Kombi_Basis
 SG_ BRIG_OFFS_KI_2 : 40|5@1+ (1,0) [0|31] "" Kombi,Kombi_Basis
 SG_ OP_ENTAI_ECU_DISP : 45|3@1+ (1,0) [0|7] "" Kombi,Kombi_Basis
 SG_ OperationDZMorPowermeterDisplay : 48|4@1+ (1,0) [0|15] "" Kombi,Kombi_Basis

BO_ 850 OP_SU_SOC_HLD: 6 ZGW
 SG_ OP_SU_SAMD_EVEH : 2|2@1+ (1,0) [0|3] "" DME2,DME1
 SG_ OP_SU_RECUP_LEV : 4|4@1+ (1,0) [0|15] "" DME2,DME1
 SG_ OP_DSTN_SOC_BAS : 8|8@1+ (1,0) [0|100] "%" DME2,DME1
 SG_ OP_ADJU_VEM_VEH : 16|2@1+ (1,0) [0|3] "" DME2,DME1
 SG_ OperationChargeControlPlug : 18|2@1+ (1,0) [0|3] "" EME
 SG_ OperationAcCurrentLimit : 32|4@1+ (1,0) [0|15] "" EME

BO_ 611 OP_VHACC_ATZ: 2 BDC_Body
 SG_ OP_SMOR_ATZ : 0|2@1+ (1,0) [0|3] "" ZGW

BO_ 1026 PIA_DT_INQY: 2 ZGW
 SG_ PIA_FN_ID_DT_INQY : 0|12@1+ (1,0) [0|4094] "This unit fulfills the required AUTOSAR reference to a unit. No real unit is defined." Vector__XXX
 SG_ PIA_PROFIL_NO_DT_INQY : 12|4@1+ (1,0) [0|15] "" Vector__XXX

BO_ 1027 PIA_DT_SET: 6 ZGW
 SG_ PIA_FN_ID_DT_SET : 0|12@1+ (1,0) [0|4094] "This unit fulfills the required AUTOSAR reference to a unit. No real unit is defined." Vector__XXX
 SG_ PIA_PROFIL_NO_DT_SET : 12|4@1+ (1,0) [0|15] "" Vector__XXX
 SG_ PIA_VL_DT_SET : 16|32@1+ (1,0) [0|4294967295] "This unit fulfills the required AUTOSAR reference to a unit. No real unit is defined." Vector__XXX

BO_ 1030 PIA_SU: 2 ZGW
 SG_ PIA_FN_ID_SU : 0|12@1+ (1,0) [0|4094] "This unit fulfills the required AUTOSAR reference to a unit. No real unit is defined." Vector__XXX
 SG_ PIA_ST_INQY : 12|2@1+ (1,0) [0|3] "" Vector__XXX

BO_ 1032 PIA_TRANA: 2 ZGW
 SG_ PIA_ST_TRANA : 0|2@1+ (1,0) [0|3] "" Kombi,BDC_Body,Kombi_Basis,NiVi

BO_ 950 POSITION_FH_FAT: 3 ZGW
 SG_ PO_WRG_DRD : 0|8@1+ (0.5,0) [0|30] "cm" DME2,DME1
 SG_ ST_PO_WRG_DRD : 8|2@1+ (1,0) [0|3] "" DME2,DME1
 SG_ ST_DRV_WRG_DRD : 19|2@1+ (1,0) [0|3] "" DME2,DME1

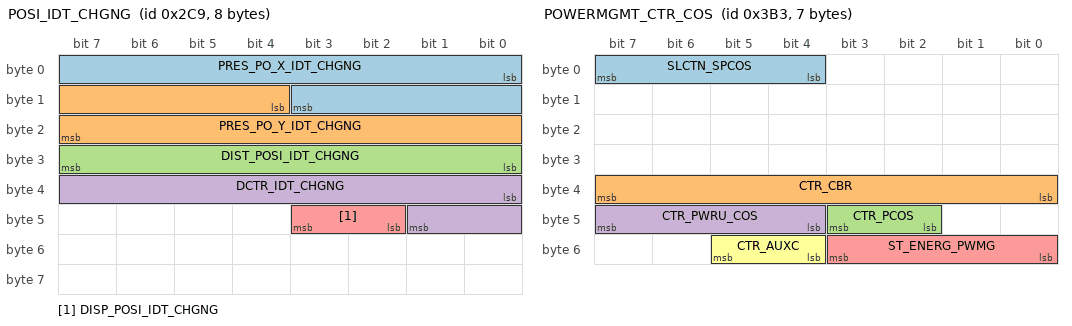
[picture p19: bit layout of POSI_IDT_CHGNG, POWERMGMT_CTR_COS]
BO_ 713 POSI_IDT_CHGNG: 8 EME
 SG_ PRES_PO_X_IDT_CHGNG : 0|12@1+ (1,-2047) [-4094|0] "cm" ZGW
 SG_ PRES_PO_Y_IDT_CHGNG : 12|12@1+ (1,-2047) [-4094|0] "cm" ZGW
 SG_ DIST_POSI_IDT_CHGNG : 24|8@1+ (2,0) [0|510] "cm" ZGW
 SG_ DCTR_IDT_CHGNG : 32|10@1+ (1,0) [0|1023] "" ZGW
 SG_ DISP_POSI_IDT_CHGNG : 42|2@1+ (1,0) [0|3] "" ZGW

BO_ 947 POWERMGMT_CTR_COS: 7 DME1
 SG_ SLCTN_SPCOS : 4|4@1+ (1,0) [0|15] "" Vector__XXX
 SG_ CTR_CBR : 32|8@1+ (1,0) [0|255] "" BDC_Body
 SG_ CTR_PCOS : 42|2@1+ (1,0) [0|3] "" ZGW,BDC_Body
 SG_ CTR_PWRU_COS : 44|4@1+ (1,0) [0|15] "" ZGW,BDC_Body
 SG_ ST_ENERG_PWMG : 48|4@1+ (1,0) [0|15] "" ZGW,Kombi,BDC_Body,CHC
 SG_ CTR_AUXC : 52|2@1+ (1,0) [0|3] "" Vector__XXX

BO_ 511 PVE_ACLN: 8 ZGW
 SG_ ACLN_PVE : 0|8@1+ (0.0625,0) [0.0000|0.984375] "m/s²" DME1
 SG_ ACLN_PVE_ERR_AMP : 8|8@1+ (0.0625,0) [0.0000|0.984375] "m/s²" DME1
 SG_ ACLNX_MAX_PVE : 16|8@1+ (0.0625,0) [0.0000|0.984375] "m/s²" DME1
 SG_ MILE_LRN_ACLN_PVE : 32|8@1+ (10,0) [0|25000] "m" DME1

BO_ 385 Prediction: 2 ZGW
 SG_ ShortTermStandStillProbability : 0|8@1+ (1,0) [0|100] "%" DME1
 SG_ PredictedLocation : 8|6@1+ (1,0) [0|63] "" DME1

BO_TX_BU_ 816 : Kombi,Kombi_Basis;
BO_TX_BU_ 2675539972 : Kombi,Kombi_Basis;
BO_TX_BU_ 2675539973 : Kombi,Kombi_Basis;
BO_TX_BU_ 2675539969 : Kombi,Kombi_Basis;
BO_TX_BU_ 2675539971 : Kombi,Kombi_Basis;
BO_TX_BU_ 2675539970 : Kombi,Kombi_Basis;
BO_TX_BU_ 2675539968 : Kombi,Kombi_Basis;
BO_TX_BU_ 413 : Kombi,Kombi_Basis;
BO_TX_BU_ 915 : Kombi,Kombi_Basis;
BO_TX_BU_ 2026 : DME1,DME2;
BO_TX_BU_ 2027 : DME1,EME;
BO_TX_BU_ 149 : FLA,ZGW;
CM_ BO_ 577  "�bermittlung der Liste der sich in Reichweite befindlichen Ladestationen (bekannt / unbekannt) des Induktiven Laden auf Anforderung und Update bei neu gefundenen oder verlorenen Ladestationen in Reichweite.";
CM_ BO_ 1085  "Diese Nachricht ist Teil des ADAS Protokolls und unterliegt den f�r das ADAS Protokoll spezifischen Charakteristika hinsichtlich Nutzbarkeit und Verf�gbarkeit. Weitere Informationen sowie Voraussetzungen zur Nutzung sind den \"ADAS Client Guidelines\" zu entnehmen.
==========
This message is a part of the ADAS protocol and is subject to the characteristics regarding usability and availability, which are specific for the ADAS protocol. Further information and prerequisites regarding the use shall be taken from the \"ADAS Client Guidelines\".";
CM_ BO_ 842  "Diese Nachricht ist Teil des ADAS Protokolls und unterliegt den f�r das ADAS Protokoll spezifischen Charakteristika hinsichtlich Nutzbarkeit und Verf�gbarkeit. Weitere Informationen sowie Voraussetzungen zur Nutzung sind den \"ADAS Client Guidelines\" zu entnehmen.
==========
This message is a part of the ADAS protocol and is subject to the characteristics regarding usability and availability, which are specific for the ADAS protocol. Further information and prerequisites regarding the use shall be taken from the \"ADAS Client Guidelines\".";
CM_ BO_ 844  "Diese Nachricht ist Teil des ADAS Protokolls und unterliegt den f�r das ADAS Protokoll spezifischen Charakteristika hinsichtlich Nutzbarkeit und Verf�gbarkeit. Weitere Informationen sowie Voraussetzungen zur Nutzung sind den \"ADAS Client Guidelines\" zu entnehmen.
==========
This message is a part of the ADAS protocol and is subject to the characteristics regarding usability and availability, which are specific for the ADAS protocol. Further information and requirements regarding the use can be found in the \"ADAS Client Guidelines\".";
CM_ BO_ 632  "Diese Nachricht ist Teil des ADAS Protokolls und unterliegt den f�r das ADAS Protokoll spezifischen Charakteristika hinsichtlich Nutzbarkeit und Verf�gbarkeit. Weitere Informationen sowie Voraussetzungen zur Nutzung sind den \"ADAS Client Guidelines\" zu entnehmen.
==========
This message is a part of the ADAS protocol and is subject to the characteristics regarding usability and availability, which are specific for the ADAS protocol. Further information and prerequisites regarding the use shall be taken from the \"ADAS Client Guidelines\".";
CM_ BO_ 840  "Diese Nachricht ist Teil des ADAS Protokolls und unterliegt den f�r das ADAS Protokoll spezifischen Charakteristika hinsichtlich Nutzbarkeit und Verf�gbarkeit. Weitere Informationen sowie Voraussetzungen zur Nutzung sind den \"ADAS Client Guidelines\" zu entnehmen.
==========
This message is a part of the ADAS protocol and is subject to the characteristics regarding usability and availability, which are specific for the ADAS protocol. Further information and prerequisites regarding the use shall be taken from the \"ADAS Client Guidelines\".";
CM_ BO_ 634  "Diese Nachricht ist Teil des ADAS Protokolls und unterliegt den f�r das ADAS Protokoll spezifischen Charakteristika hinsichtlich Nutzbarkeit und Verf�gbarkeit. Weitere Informationen sowie Voraussetzungen zur Nutzung sind den \"ADAS Client Guidelines\" zu entnehmen.
==========
This message is a part of the ADAS protocol and is subject to the characteristics regarding usability and availability, which are specific for the ADAS protocol. Further information and prerequisites regarding the use shall be taken from the \"ADAS Client Guidelines\".";
CM_ BO_ 846  "Diese Nachricht ist Teil des ADAS Protokolls und unterliegt den f�r das ADAS Protokoll spezifischen Charakteristika hinsichtlich Nutzbarkeit und Verf�gbarkeit. Weitere Informationen sowie Voraussetzungen zur Nutzung sind den \"ADAS Client Guidelines\" zu entnehmen.
==========
This message is a part of the ADAS protocol and is subject to the characteristics regarding usability and availability, which are specific for the ADAS protocol. Further information and prerequisites regarding the use shall be taken from the \"ADAS Client Guidelines\".";

BA_DEF_ BO_ "FrameTriggeringName" STRING;
BA_DEF_ BO_ "GenMsgCycleTime" INT 0 65535;
BA_DEF_ BO_ "GenMsgDelayTime" INT 0 65535;
BA_DEF_ BO_ "GenMsgSendType" ENUM  "cyclicX","spontanX","cyclicIfActiveX","spontanWithDelay","cyclicAndSpontanX","cyclicAndSpontanWithDelay","spontanWithRepitition","cyclicIfActiveAndSpontanWD","cyclicIfActiveFast","cyclicWithRepeatOnDemand","none";
BA_DEF_ BO_ "GenMsgStartValue" STRING;
BA_DEF_ BO_ "PduName" STRING;
BA_DEF_ BO_ "SystemMessageLongSymbol" STRING;
BA_DEF_ SG_ "CompuMethodName" STRING;
BA_DEF_ SG_ "GenSigStartValue" FLOAT 0 100000000000;
BA_DEF_ SG_ "ISignalName" STRING;
BA_DEF_ SG_ "LongName" STRING;
BA_DEF_ SG_ "SysSignalName" STRING;
BA_DEF_ SG_ "SystemSignalLongSymbol" STRING;
BA_ "FrameTriggeringName" BO_ 312 "frTrig_CAN_963412009_312_963401199_963411732_963424759_FA_CAN";
BA_ "GenMsgCycleTime" BO_ 312 1000;
BA_ "GenMsgDelayTime" BO_ 312 10;
BA_ "GenMsgSendType" BO_ 312 4;
BA_ "GenMsgStartValue" BO_ 312 "0000000000000000";
BA_ "PduName" BO_ 312 "INFO_PT";
BA_ "FrameTriggeringName" BO_ 101 "frTrig_CAN_963411927_101_963400903_963411732_963424759_FA_CAN";
BA_ "GenMsgCycleTime" BO_ 101 100;
BA_ "GenMsgDelayTime" BO_ 101 20;
BA_ "GenMsgSendType" BO_ 101 4;
BA_ "GenMsgStartValue" BO_ 101 "0000000000000080";
BA_ "PduName" BO_ 101 "INFO_VEH_DRV";
BA_ "FrameTriggeringName" BO_ 642 "frTrig_CAN_963411958_642_963391946_963411732_963424759_FA_CAN";
BA_ "GenMsgCycleTime" BO_ 642 1000;
BA_ "GenMsgDelayTime" BO_ 642 100;
BA_ "GenMsgSendType" BO_ 642 4;
BA_ "GenMsgStartValue" BO_ 642 "0000000000000000";
BA_ "PduName" BO_ 642 "INQY_PWR_FNS_AIC_1";
BA_ "FrameTriggeringName" BO_ 645 "frTrig_CAN_963412111_645_963398914_963411732_963424759_FA_CAN";
BA_ "GenMsgCycleTime" BO_ 645 1000;
BA_ "GenMsgDelayTime" BO_ 645 100;
BA_ "GenMsgSendType" BO_ 645 4;
BA_ "GenMsgStartValue" BO_ 645 "0000000000000000";
BA_ "PduName" BO_ 645 "INQY_PWR_FNS_AIC_2";
BA_ "FrameTriggeringName" BO_ 1189 "frTrig_CAN_963411755_1189_963391743_963411732_963424759_FA_CAN";
BA_ "GenMsgSendType" BO_ 1189 1;
BA_ "GenMsgStartValue" BO_ 1189 "0000000000000000";
BA_ "PduName" BO_ 1189 "InfoChargingERoute";
BA_ "FrameTriggeringName" BO_ 816 "frTrig_CAN_963411868_816_963405093_963411732_963424759_FA_CAN";
BA_ "GenMsgCycleTime" BO_ 816 10000;
BA_ "GenMsgDelayTime" BO_ 816 200;
BA_ "GenMsgSendType" BO_ 816 4;
BA_ "GenMsgStartValue" BO_ 816 "0000000000000000";
BA_ "PduName" BO_ 816 "KILOMETERSTAND";
BA_ "FrameTriggeringName" BO_ 2675539972 "frTrig_CAN_963411831_528056324_963405608_963411732_963424759_FA_CAN";
BA_ "GenMsgDelayTime" BO_ 2675539972 10;
BA_ "GenMsgSendType" BO_ 2675539972 1;
BA_ "GenMsgStartValue" BO_ 2675539972 "0000000000000000";
BA_ "PduName" BO_ 2675539972 "KI_DBG_Dummy_1";
BA_ "FrameTriggeringName" BO_ 2675539973 "frTrig_CAN_963411826_528056325_963398891_963411732_963424759_FA_CAN";
BA_ "GenMsgDelayTime" BO_ 2675539973 10;
BA_ "GenMsgSendType" BO_ 2675539973 1;
BA_ "GenMsgStartValue" BO_ 2675539973 "0000000000000000";
BA_ "PduName" BO_ 2675539973 "KI_DBG_Dummy_2";
BA_ "FrameTriggeringName" BO_ 2675539969 "frTrig_CAN_963411830_528056321_963391763_963411732_963424759_FA_CAN";
BA_ "GenMsgDelayTime" BO_ 2675539969 10;
BA_ "GenMsgSendType" BO_ 2675539969 1;
BA_ "GenMsgStartValue" BO_ 2675539969 "0000000000000000";
BA_ "PduName" BO_ 2675539969 "KI_DBG_FUTA_ST";
BA_ "FrameTriggeringName" BO_ 2675539971 "frTrig_CAN_963411829_528056323_963396484_963411732_963424759_FA_CAN";
BA_ "GenMsgDelayTime" BO_ 2675539971 10;
BA_ "GenMsgSendType" BO_ 2675539971 1;
BA_ "GenMsgStartValue" BO_ 2675539971 "0000000000000000";
BA_ "PduName" BO_ 2675539971 "KI_DBG_RNG_BUR";
BA_ "FrameTriggeringName" BO_ 2675539970 "frTrig_CAN_963411828_528056322_963403211_963411732_963424759_FA_CAN";
BA_ "GenMsgDelayTime" BO_ 2675539970 10;
BA_ "GenMsgSendType" BO_ 2675539970 1;
BA_ "GenMsgStartValue" BO_ 2675539970 "0000000000000000";
BA_ "PduName" BO_ 2675539970 "KI_DBG_RNG_EL";
BA_ "FrameTriggeringName" BO_ 2675539968 "frTrig_CAN_963411827_528056320_963403208_963411732_963424759_FA_CAN";
BA_ "GenMsgDelayTime" BO_ 2675539968 10;
BA_ "GenMsgSendType" BO_ 2675539968 1;
BA_ "GenMsgStartValue" BO_ 2675539968 "0000000000000000";
BA_ "PduName" BO_ 2675539968 "KI_DBG_TAC";
BA_ "FrameTriggeringName" BO_ 303 "frTrig_CAN_963412130_303_963400603_963411732_963424759_FA_CAN";
BA_ "GenMsgCycleTime" BO_ 303 100;
BA_ "GenMsgDelayTime" BO_ 303 20;
BA_ "GenMsgSendType" BO_ 303 4;
BA_ "GenMsgStartValue" BO_ 303 "0000800000008000";
BA_ "PduName" BO_ 303 "KLEMMEN";
BA_ "FrameTriggeringName" BO_ 413 "frTrig_CAN_963411916_413_963391220_963411732_963424759_FA_CAN";
BA_ "GenMsgCycleTime" BO_ 413 300;
BA_ "GenMsgDelayTime" BO_ 413 50;
BA_ "GenMsgSendType" BO_ 413 4;
BA_ "GenMsgStartValue" BO_ 413 "0000000000000000";
BA_ "PduName" BO_ 413 "Kilometerstand_2";
BA_ "FrameTriggeringName" BO_ 538 "frTrig_CAN_963411774_538_963391235_963411732_963424759_FA_CAN";
BA_ "GenMsgCycleTime" BO_ 538 5000;
BA_ "GenMsgDelayTime" BO_ 538 50;
BA_ "GenMsgSendType" BO_ 538 4;
BA_ "GenMsgStartValue" BO_ 538 "000000";
BA_ "PduName" BO_ 538 "LAMPENZUSTAND";
BA_ "FrameTriggeringName" BO_ 915 "frTrig_CAN_963411963_915_963393517_963411732_963424759_FA_CAN";
BA_ "GenMsgCycleTime" BO_ 915 5000;
BA_ "GenMsgDelayTime" BO_ 915 100;
BA_ "GenMsgSendType" BO_ 915 4;
BA_ "GenMsgStartValue" BO_ 915 "00640000";
BA_ "PduName" BO_ 915 "LCD_BRIG_CLCTR";
BA_ "FrameTriggeringName" BO_ 577 "frTrig_CAN_963411931_577_963403408_963411732_963424759_FA_CAN";
BA_ "GenMsgSendType" BO_ 577 1;
BA_ "GenMsgStartValue" BO_ 577 "0000000000000000";
BA_ "PduName" BO_ 577 "LST_CHGSTN_IDT_CHGNG";
BA_ "FrameTriggeringName" BO_ 736 "frTrig_CAN_963411888_736_963400828_963411732_963424759_FA_CAN";
BA_ "GenMsgCycleTime" BO_ 736 100;
BA_ "GenMsgSendType" BO_ 736 0;
BA_ "GenMsgStartValue" BO_ 736 "000000000000";
BA_ "PduName" BO_ 736 "MASS_VEH";
BA_ "FrameTriggeringName" BO_ 1077 "frTrig_CAN_963411845_1077_963403227_963411732_963424759_FA_CAN";
BA_ "GenMsgDelayTime" BO_ 1077 100;
BA_ "GenMsgSendType" BO_ 1077 1;
BA_ "GenMsgStartValue" BO_ 1077 "00000000";
BA_ "PduName" BO_ 1077 "MEASMT_EOI";
BA_ "FrameTriggeringName" BO_ 523 "frTrig_CAN_963412040_523_963402665_963411732_963424759_FA_CAN";
BA_ "GenMsgDelayTime" BO_ 523 100;
BA_ "GenMsgSendType" BO_ 523 1;
BA_ "GenMsgStartValue" BO_ 523 "0001";
BA_ "PduName" BO_ 523 "MEMORYVERSTELLUNG";
BA_ "FrameTriggeringName" BO_ 699 "frTrig_CAN_963411995_699_963402920_963411732_963424759_FA_CAN";
BA_ "GenMsgCycleTime" BO_ 699 100;
BA_ "GenMsgSendType" BO_ 699 0;
BA_ "GenMsgStartValue" BO_ 699 "0080000080";
BA_ "PduName" BO_ 699 "MILE_VEH";
BA_ "FrameTriggeringName" BO_ 1074 "frTrig_CAN_963411778_1074_963398883_963411732_963424759_FA_CAN";
BA_ "GenMsgCycleTime" BO_ 1074 200;
BA_ "GenMsgDelayTime" BO_ 1074 40;
BA_ "GenMsgSendType" BO_ 1074 4;
BA_ "GenMsgStartValue" BO_ 1074 "0000000000000000";
BA_ "PduName" BO_ 1074 "MOD_VC";
BA_ "FrameTriggeringName" BO_ 1085 "frTrig_CAN_963411960_1085_963388999_963411732_963424759_FA_CAN";
BA_ "GenMsgCycleTime" BO_ 1085 400;
BA_ "GenMsgSendType" BO_ 1085 0;
BA_ "GenMsgStartValue" BO_ 1085 "004cef7f00000000";
BA_ "PduName" BO_ 1085 "NAVGRPH_2_PRES_SEG";
BA_ "FrameTriggeringName" BO_ 842 "frTrig_CAN_963411981_842_963396533_963411732_963424759_FA_CAN";
BA_ "GenMsgCycleTime" BO_ 842 1000;
BA_ "GenMsgSendType" BO_ 842 0;
BA_ "GenMsgStartValue" BO_ 842 "0000000000000000";
BA_ "PduName" BO_ 842 "NAV_GPS1";
BA_ "FrameTriggeringName" BO_ 844 "frTrig_CAN_963411970_844_963389566_963411732_963424759_FA_CAN";
BA_ "GenMsgCycleTime" BO_ 844 1000;
BA_ "GenMsgSendType" BO_ 844 0;
BA_ "GenMsgStartValue" BO_ 844 "0000000000000000";
BA_ "PduName" BO_ 844 "NAV_GPS2";
BA_ "FrameTriggeringName" BO_ 632 "frTrig_CAN_963412153_632_963396186_963411732_963424759_FA_CAN";
BA_ "GenMsgDelayTime" BO_ 632 20;
BA_ "GenMsgSendType" BO_ 632 1;
BA_ "GenMsgStartValue" BO_ 632 "0000000000000000";
BA_ "PduName" BO_ 632 "NAV_GRAPH";
BA_ "FrameTriggeringName" BO_ 840 "frTrig_CAN_963411924_840_963405185_963411732_963424759_FA_CAN";
BA_ "GenMsgCycleTime" BO_ 840 400;
BA_ "GenMsgSendType" BO_ 840 0;
BA_ "GenMsgStartValue" BO_ 840 "0000000000000000";
BA_ "PduName" BO_ 840 "NAV_GRAPH_MATCH";
BA_ "FrameTriggeringName" BO_ 634 "frTrig_CAN_963411792_634_963398398_963411732_963424759_FA_CAN";
BA_ "GenMsgDelayTime" BO_ 634 20;
BA_ "GenMsgSendType" BO_ 634 1;
BA_ "GenMsgStartValue" BO_ 634 "0000000000000000";
BA_ "PduName" BO_ 634 "NAV_GRAPH_SYNC";
BA_ "FrameTriggeringName" BO_ 846 "frTrig_CAN_963411856_846_963405301_963411732_963424759_FA_CAN";
BA_ "GenMsgCycleTime" BO_ 846 5000;
BA_ "GenMsgSendType" BO_ 846 0;
BA_ "GenMsgStartValue" BO_ 846 "0000000000000000";
BA_ "PduName" BO_ 846 "NAV_SYS_INF";
BA_ "FrameTriggeringName" BO_ 555 "frTrig_CAN_963412161_555_963396723_963411732_963424759_FA_CAN";
BA_ "GenMsgCycleTime" BO_ 555 1000;
BA_ "GenMsgDelayTime" BO_ 555 100;
BA_ "GenMsgSendType" BO_ 555 4;
BA_ "GenMsgStartValue" BO_ 555 "0000000000000000";
BA_ "PduName" BO_ 555 "NIVI_HDWOBS";
BA_ "FrameTriggeringName" BO_ 2024 "frTrig_CAN_963411769_2024_963403135_963411732_963424759_FA_CAN";
BA_ "GenMsgSendType" BO_ 2024 1;
BA_ "GenMsgStartValue" BO_ 2024 "0000000000000000";
BA_ "PduName" BO_ 2024 "OBD_ANSW_ECU_1";
BA_ "FrameTriggeringName" BO_ 2025 "frTrig_CAN_963412155_2025_963396390_963411732_963424759_FA_CAN";
BA_ "GenMsgSendType" BO_ 2025 1;
BA_ "GenMsgStartValue" BO_ 2025 "0000000000000000";
BA_ "PduName" BO_ 2025 "OBD_ANSW_ECU_2";
BA_ "FrameTriggeringName" BO_ 2026 "frTrig_CAN_963411907_2026_963401021_963411732_963424759_FA_CAN";
BA_ "GenMsgSendType" BO_ 2026 1;
BA_ "GenMsgStartValue" BO_ 2026 "0000000000000000";
BA_ "PduName" BO_ 2026 "OBD_ANSW_ECU_3";
BA_ "FrameTriggeringName" BO_ 2027 "frTrig_CAN_963412069_2027_963389334_963411732_963424759_FA_CAN";
BA_ "GenMsgSendType" BO_ 2027 1;
BA_ "GenMsgStartValue" BO_ 2027 "0000000000000000";
BA_ "PduName" BO_ 2027 "OBD_ANSW_ECU_4";
BA_ "FrameTriggeringName" BO_ 2028 "frTrig_CAN_963411761_2028_963389342_963411732_963424759_FA_CAN";
BA_ "GenMsgSendType" BO_ 2028 1;
BA_ "GenMsgStartValue" BO_ 2028 "0000000000000000";
BA_ "PduName" BO_ 2028 "OBD_ANSW_ECU_5";
BA_ "FrameTriggeringName" BO_ 2029 "frTrig_CAN_963412081_2029_963394104_963411732_963424759_FA_CAN";
BA_ "GenMsgSendType" BO_ 2029 1;
BA_ "GenMsgStartValue" BO_ 2029 "0000000000000000";
BA_ "PduName" BO_ 2029 "OBD_ANSW_ECU_6";
BA_ "FrameTriggeringName" BO_ 2030 "frTrig_CAN_963412142_2030_963389350_963411732_963424759_FA_CAN";
BA_ "GenMsgSendType" BO_ 2030 1;
BA_ "GenMsgStartValue" BO_ 2030 "0000000000000000";
BA_ "PduName" BO_ 2030 "OBD_ANSW_ECU_7";
BA_ "FrameTriggeringName" BO_ 2031 "frTrig_CAN_963412066_2031_963401029_963411732_963424759_FA_CAN";
BA_ "GenMsgSendType" BO_ 2031 1;
BA_ "GenMsgStartValue" BO_ 2031 "0000000000000000";
BA_ "PduName" BO_ 2031 "OBD_ANSW_ECU_8";
BA_ "FrameTriggeringName" BO_ 2016 "frTrig_CAN_963411920_2016_963396402_963411732_963424759_FA_CAN";
BA_ "GenMsgSendType" BO_ 2016 1;
BA_ "GenMsgStartValue" BO_ 2016 "0000000000000000";
BA_ "PduName" BO_ 2016 "OBD_RQ_ECU_1";
BA_ "FrameTriggeringName" BO_ 2017 "frTrig_CAN_963412018_2017_963403119_963411732_963424759_FA_CAN";
BA_ "GenMsgSendType" BO_ 2017 1;
BA_ "GenMsgStartValue" BO_ 2017 "0000000000000000";
BA_ "PduName" BO_ 2017 "OBD_RQ_ECU_2";
BA_ "FrameTriggeringName" BO_ 2018 "frTrig_CAN_963411944_2018_963401033_963411732_963424759_FA_CAN";
BA_ "GenMsgSendType" BO_ 2018 1;
BA_ "GenMsgStartValue" BO_ 2018 "0000000000000000";
BA_ "PduName" BO_ 2018 "OBD_RQ_ECU_3";
BA_ "FrameTriggeringName" BO_ 2019 "frTrig_CAN_963411928_2019_963394108_963411732_963424759_FA_CAN";
BA_ "GenMsgSendType" BO_ 2019 1;
BA_ "GenMsgStartValue" BO_ 2019 "0000000000000000";
BA_ "PduName" BO_ 2019 "OBD_RQ_ECU_4";
BA_ "FrameTriggeringName" BO_ 2020 "frTrig_CAN_963411940_2020_963396394_963411732_963424759_FA_CAN";
BA_ "GenMsgSendType" BO_ 2020 1;
BA_ "GenMsgStartValue" BO_ 2020 "0000000000000000";
BA_ "PduName" BO_ 2020 "OBD_RQ_ECU_5";
BA_ "FrameTriggeringName" BO_ 2021 "frTrig_CAN_963411773_2021_963405520_963411732_963424759_FA_CAN";
BA_ "GenMsgSendType" BO_ 2021 1;
BA_ "GenMsgStartValue" BO_ 2021 "0000000000000000";
BA_ "PduName" BO_ 2021 "OBD_RQ_ECU_6";
BA_ "FrameTriggeringName" BO_ 2022 "frTrig_CAN_963411949_2022_963401037_963411732_963424759_FA_CAN";
BA_ "GenMsgSendType" BO_ 2022 1;
BA_ "GenMsgStartValue" BO_ 2022 "0000000000000000";
BA_ "PduName" BO_ 2022 "OBD_RQ_ECU_7";
BA_ "FrameTriggeringName" BO_ 2023 "frTrig_CAN_963412133_2023_963389338_963411732_963424759_FA_CAN";
BA_ "GenMsgSendType" BO_ 2023 1;
BA_ "GenMsgStartValue" BO_ 2023 "0000000000000000";
BA_ "PduName" BO_ 2023 "OBD_RQ_ECU_8";
BA_ "FrameTriggeringName" BO_ 2015 "frTrig_CAN_963411853_2015_963403131_963411732_963424759_FA_CAN";
BA_ "GenMsgSendType" BO_ 2015 1;
BA_ "GenMsgStartValue" BO_ 2015 "0000000000000000";
BA_ "PduName" BO_ 2015 "OBD_RQ_FN";
BA_ "FrameTriggeringName" BO_ 462 "frTrig_CAN_963412134_462_963394353_963411732_963424759_FA_CAN";
BA_ "GenMsgCycleTime" BO_ 462 60;
BA_ "GenMsgSendType" BO_ 462 0;
BA_ "GenMsgStartValue" BO_ 462 "fbf6f10000000000";
BA_ "PduName" BO_ 462 "OBJDT_2_NGL_MAB_ASST";
BA_ "FrameTriggeringName" BO_ 463 "frTrig_CAN_963411802_463_963405599_963411732_963424759_FA_CAN";
BA_ "GenMsgCycleTime" BO_ 463 60;
BA_ "GenMsgSendType" BO_ 463 0;
BA_ "GenMsgStartValue" BO_ 463 "fbf6f10000000000";
BA_ "PduName" BO_ 463 "OBJDT_3_NGL_MAB_ASST";
BA_ "FrameTriggeringName" BO_ 149 "frTrig_CAN_963412124_149_963399097_963411732_963424759_FA_CAN";
BA_ "GenMsgCycleTime" BO_ 149 60;
BA_ "GenMsgSendType" BO_ 149 0;
BA_ "GenMsgStartValue" BO_ 149 "fbf6f10000000000";
BA_ "PduName" BO_ 149 "OBJDT_NGL_MAB_ASST";
BA_ "FrameTriggeringName" BO_ 393 "frTrig_CAN_963411937_393_963400703_963411732_963424759_FA_CAN";
BA_ "GenMsgCycleTime" BO_ 393 200;
BA_ "GenMsgDelayTime" BO_ 393 50;
BA_ "GenMsgSendType" BO_ 393 4;
BA_ "GenMsgStartValue" BO_ 393 "000000000000";
BA_ "PduName" BO_ 393 "OP_CCTR";
BA_ "FrameTriggeringName" BO_ 938 "frTrig_CAN_963412057_938_963401088_963411732_963424759_FA_CAN";
BA_ "GenMsgDelayTime" BO_ 938 200;
BA_ "GenMsgSendType" BO_ 938 1;
BA_ "GenMsgStartValue" BO_ 938 "ecec0d0000000000";
BA_ "PduName" BO_ 938 "OP_CTI_DATE_UTC";
BA_ "FrameTriggeringName" BO_ 939 "frTrig_CAN_963411890_939_963403275_963411732_963424759_FA_CAN";
BA_ "GenMsgDelayTime" BO_ 939 200;
BA_ "GenMsgSendType" BO_ 939 1;
BA_ "GenMsgStartValue" BO_ 939 "000000100000ec00";
BA_ "PduName" BO_ 939 "OP_DATE_WIT_SUT";
BA_ "FrameTriggeringName" BO_ 657 "frTrig_CAN_963411922_657_963389297_963411732_963424759_FA_CAN";
BA_ "GenMsgDelayTime" BO_ 657 100;
BA_ "GenMsgSendType" BO_ 657 1;
BA_ "GenMsgStartValue" BO_ 657 "000000000000";
BA_ "PduName" BO_ 657 "OP_EINHEITEN";
BA_ "FrameTriggeringName" BO_ 801 "frTrig_CAN_963412061_801_963394251_963411732_963424759_FA_CAN";
BA_ "GenMsgDelayTime" BO_ 801 200;
BA_ "GenMsgSendType" BO_ 801 1;
BA_ "GenMsgStartValue" BO_ 801 "0000000000000000";
BA_ "PduName" BO_ 801 "OP_HUD_3";
BA_ "FrameTriggeringName" BO_ 880 "frTrig_CAN_963412141_880_963394225_963411732_963424759_FA_CAN";
BA_ "GenMsgDelayTime" BO_ 880 200;
BA_ "GenMsgSendType" BO_ 880 1;
BA_ "GenMsgStartValue" BO_ 880 "00000000";
BA_ "PduName" BO_ 880 "OP_IDLV_COOD_DISP_DXP";
BA_ "FrameTriggeringName" BO_ 892 "frTrig_CAN_963412127_892_963398764_963411732_963424759_FA_CAN";
BA_ "GenMsgDelayTime" BO_ 892 200;
BA_ "GenMsgSendType" BO_ 892 1;
BA_ "GenMsgStartValue" BO_ 892 "0000000000";
BA_ "PduName" BO_ 892 "OP_IDLV_COOD_DRV_DXP";
BA_ "FrameTriggeringName" BO_ 745 "frTrig_CAN_963412150_745_963399037_963411732_963424759_FA_CAN";
BA_ "GenMsgCycleTime" BO_ 745 100;
BA_ "GenMsgDelayTime" BO_ 745 100;
BA_ "GenMsgSendType" BO_ 745 4;
BA_ "GenMsgStartValue" BO_ 745 "0000";
BA_ "PduName" BO_ 745 "OP_PUBU_EVEH";
BA_ "FrameTriggeringName" BO_ 651 "frTrig_CAN_963412143_651_963391977_963411732_963424759_FA_CAN";
BA_ "GenMsgCycleTime" BO_ 651 5000;
BA_ "GenMsgDelayTime" BO_ 651 100;
BA_ "GenMsgSendType" BO_ 651 4;
BA_ "GenMsgStartValue" BO_ 651 "0000";
BA_ "PduName" BO_ 651 "OP_PUBU_HUD";
BA_ "FrameTriggeringName" BO_ 604 "frTrig_CAN_963411736_604_963398271_963411732_963424759_FA_CAN";
BA_ "GenMsgCycleTime" BO_ 604 100;
BA_ "GenMsgDelayTime" BO_ 604 100;
BA_ "GenMsgSendType" BO_ 604 4;
BA_ "GenMsgStartValue" BO_ 604 "0000";
BA_ "PduName" BO_ 604 "OP_PUBU_LVCH";
BA_ "FrameTriggeringName" BO_ 650 "frTrig_CAN_963411879_650_963405803_963411732_963424759_FA_CAN";
BA_ "GenMsgCycleTime" BO_ 650 5000;
BA_ "GenMsgDelayTime" BO_ 650 100;
BA_ "GenMsgSendType" BO_ 650 4;
BA_ "GenMsgStartValue" BO_ 650 "0000";
BA_ "PduName" BO_ 650 "OP_PUBU_NIVI";
BA_ "FrameTriggeringName" BO_ 519 "frTrig_CAN_963411891_519_963399053_963411732_963424759_FA_CAN";
BA_ "GenMsgCycleTime" BO_ 519 1000;
BA_ "GenMsgDelayTime" BO_ 519 10;
BA_ "GenMsgSendType" BO_ 519 4;
BA_ "GenMsgStartValue" BO_ 519 "0000";
BA_ "PduName" BO_ 519 "OP_SPD";
BA_ "FrameTriggeringName" BO_ 609 "frTrig_CAN_963411979_609_963403417_963411732_963424759_FA_CAN";
BA_ "GenMsgCycleTime" BO_ 609 5000;
BA_ "GenMsgDelayTime" BO_ 609 50;
BA_ "GenMsgSendType" BO_ 609 4;
BA_ "GenMsgStartValue" BO_ 609 "0000008000000080";
BA_ "PduName" BO_ 609 "OP_STW";
BA_ "FrameTriggeringName" BO_ 727 "frTrig_CAN_963411818_727_963405602_963411732_963424759_FA_CAN";
BA_ "GenMsgDelayTime" BO_ 727 100;
BA_ "GenMsgSendType" BO_ 727 1;
BA_ "GenMsgStartValue" BO_ 727 "0000000000000000";
BA_ "PduName" BO_ 727 "OP_ST_CHGNG_I_LIM_2";
BA_ "FrameTriggeringName" BO_ 1051 "frTrig_CAN_963412059_1051_963405681_963411732_963424759_FA_CAN";
BA_ "GenMsgDelayTime" BO_ 1051 200;
BA_ "GenMsgSendType" BO_ 1051 1;
BA_ "GenMsgStartValue" BO_ 1051 "0000000000000000";
BA_ "PduName" BO_ 1051 "OP_SU_KI_4";
BA_ "FrameTriggeringName" BO_ 974 "frTrig_CAN_963412128_974_963389582_963411732_963424759_FA_CAN";
BA_ "GenMsgDelayTime" BO_ 974 200;
BA_ "GenMsgSendType" BO_ 974 1;
BA_ "GenMsgStartValue" BO_ 974 "0000000000000000";
BA_ "PduName" BO_ 974 "OP_SU_KI_5";
BA_ "FrameTriggeringName" BO_ 850 "frTrig_CAN_963412056_850_963394067_963411732_963424759_FA_CAN";
BA_ "GenMsgDelayTime" BO_ 850 100;
BA_ "GenMsgSendType" BO_ 850 1;
BA_ "GenMsgStartValue" BO_ 850 "000000000000";
BA_ "PduName" BO_ 850 "OP_SU_SOC_HLD";
BA_ "FrameTriggeringName" BO_ 611 "frTrig_CAN_963412095_611_963388795_963411732_963424759_FA_CAN";
BA_ "GenMsgDelayTime" BO_ 611 50;
BA_ "GenMsgSendType" BO_ 611 1;
BA_ "GenMsgStartValue" BO_ 611 "0000";
BA_ "PduName" BO_ 611 "OP_VHACC_ATZ";
BA_ "FrameTriggeringName" BO_ 1026 "frTrig_CAN_963411767_1026_963398232_963411732_963424759_FA_CAN";
BA_ "GenMsgDelayTime" BO_ 1026 100;
BA_ "GenMsgSendType" BO_ 1026 1;
BA_ "GenMsgStartValue" BO_ 1026 "0000";
BA_ "PduName" BO_ 1026 "PIA_DT_INQY";
BA_ "FrameTriggeringName" BO_ 1027 "frTrig_CAN_963412035_1027_963400583_963411732_963424759_FA_CAN";
BA_ "GenMsgDelayTime" BO_ 1027 100;
BA_ "GenMsgSendType" BO_ 1027 1;
BA_ "GenMsgStartValue" BO_ 1027 "000000000000";
BA_ "PduName" BO_ 1027 "PIA_DT_SET";
BA_ "FrameTriggeringName" BO_ 1030 "frTrig_CAN_963412131_1030_963400664_963411732_963424759_FA_CAN";
BA_ "GenMsgDelayTime" BO_ 1030 100;
BA_ "GenMsgSendType" BO_ 1030 1;
BA_ "GenMsgStartValue" BO_ 1030 "0000";
BA_ "PduName" BO_ 1030 "PIA_SU";
BA_ "FrameTriggeringName" BO_ 1032 "frTrig_CAN_963412149_1032_963393566_963411732_963424759_FA_CAN";
BA_ "GenMsgDelayTime" BO_ 1032 100;
BA_ "GenMsgSendType" BO_ 1032 1;
BA_ "GenMsgStartValue" BO_ 1032 "0000";
BA_ "PduName" BO_ 1032 "PIA_TRANA";
BA_ "FrameTriggeringName" BO_ 950 "frTrig_CAN_963411753_950_963388875_963411732_963424759_FA_CAN";
BA_ "GenMsgCycleTime" BO_ 950 100;
BA_ "GenMsgDelayTime" BO_ 950 50;
BA_ "GenMsgSendType" BO_ 950 4;
BA_ "GenMsgStartValue" BO_ 950 "000000";
BA_ "PduName" BO_ 950 "POSITION_FH_FAT";
BA_ "FrameTriggeringName" BO_ 713 "frTrig_CAN_963412126_713_963391973_963411732_963424759_FA_CAN";
BA_ "GenMsgCycleTime" BO_ 713 100;
BA_ "GenMsgSendType" BO_ 713 0;
BA_ "GenMsgStartValue" BO_ 713 "fff77f0000000000";
BA_ "PduName" BO_ 713 "POSI_IDT_CHGNG";
BA_ "FrameTriggeringName" BO_ 947 "frTrig_CAN_963411815_947_963388937_963411732_963424759_FA_CAN";
BA_ "GenMsgCycleTime" BO_ 947 5000;
BA_ "GenMsgDelayTime" BO_ 947 100;
BA_ "GenMsgSendType" BO_ 947 4;
BA_ "GenMsgStartValue" BO_ 947 "00000000000000";
BA_ "PduName" BO_ 947 "POWERMGMT_CTR_COS";
BA_ "FrameTriggeringName" BO_ 511 "frTrig_CAN_963412068_511_963401209_963411732_963424759_FA_CAN";
BA_ "GenMsgCycleTime" BO_ 511 60;
BA_ "GenMsgSendType" BO_ 511 0;
BA_ "GenMsgStartValue" BO_ 511 "0000000000000000";
BA_ "PduName" BO_ 511 "PVE_ACLN";
BA_ "FrameTriggeringName" BO_ 385 "frTrig_CAN_963412164_385_963391981_963411732_963424759_FA_CAN";
BA_ "GenMsgDelayTime" BO_ 385 20;
BA_ "GenMsgSendType" BO_ 385 1;
BA_ "GenMsgStartValue" BO_ 385 "0000";
BA_ "PduName" BO_ 385 "Prediction";
BA_ "CompuMethodName" SG_ 312 TAR_RPM_MAX_ENG "TAR_RPM_MAX_ENG";
BA_ "ISignalName" SG_ 312 TAR_RPM_MAX_ENG "TAR_RPM_MAX_ENG";
BA_ "LongName" SG_ 312 TAR_RPM_MAX_ENG "Soll_Drehzahl_Maximal_Motor";
BA_ "SysSignalName" SG_ 312 TAR_RPM_MAX_ENG "TAR_RPM_MAX_ENG";
BA_ "CompuMethodName" SG_ 312 ST_CON_MSA_EXT "ST_CON_MSA_EXT";
BA_ "ISignalName" SG_ 312 ST_CON_MSA_EXT "ST_CON_MSA_EXT";
BA_ "LongName" SG_ 312 ST_CON_MSA_EXT "Status_Zustand_MSA_Erweitert";
BA_ "SysSignalName" SG_ 312 ST_CON_MSA_EXT "ST_CON_MSA_EXT";
BA_ "CompuMethodName" SG_ 312 ST_STA_VARI_MSA "ST_STA_VARI_MSA";
BA_ "ISignalName" SG_ 312 ST_STA_VARI_MSA "ST_STA_VARI_MSA";
BA_ "LongName" SG_ 312 ST_STA_VARI_MSA "Status_Start_Varianten_MSA";
BA_ "SysSignalName" SG_ 312 ST_STA_VARI_MSA "ST_STA_VARI_MSA";
BA_ "CompuMethodName" SG_ 312 ST_RPM_LIM_CENG "ST_RPM_LIM_CENG";
BA_ "ISignalName" SG_ 312 ST_RPM_LIM_CENG "ST_RPM_LIM_CENG";
BA_ "LongName" SG_ 312 ST_RPM_LIM_CENG "Status_Drehzahl_Begrenzung_Verbrennungsmotor";
BA_ "SysSignalName" SG_ 312 ST_RPM_LIM_CENG "ST_RPM_LIM_CENG";
BA_ "CompuMethodName" SG_ 312 INHB_RQ_EZA "INHB_RQ_EZA";
BA_ "ISignalName" SG_ 312 INHB_RQ_EZA "INHB_RQ_EZA";
BA_ "LongName" SG_ 312 INHB_RQ_EZA "Verbot_Anforderung_EZA";
BA_ "SysSignalName" SG_ 312 INHB_RQ_EZA "INHB_RQ_EZA";
BA_ "CompuMethodName" SG_ 312 RQ_EMMOD_VEH "RQ_EMMOD_VEH";
BA_ "ISignalName" SG_ 312 RQ_EMMOD_VEH "RQ_EMMOD_VEH";
BA_ "LongName" SG_ 312 RQ_EMMOD_VEH "Anforderung_Notlauf_Fahrzeug";
BA_ "SysSignalName" SG_ 312 RQ_EMMOD_VEH "RQ_EMMOD_VEH";
BA_ "CompuMethodName" SG_ 312 RQ_SUBST_REAC_GRB "RQ_SUBST_REAC_GRB";
BA_ "ISignalName" SG_ 312 RQ_SUBST_REAC_GRB "RQ_SUBST_REAC_GRB";
BA_ "LongName" SG_ 312 RQ_SUBST_REAC_GRB "Anforderung_Ersatz_Reaktion_Getriebe";
BA_ "SysSignalName" SG_ 312 RQ_SUBST_REAC_GRB "RQ_SUBST_REAC_GRB";
BA_ "CompuMethodName" SG_ 312 StatShutoffValveCCGearboxSP2018 "StatShutoffValveCCGearboxSP2018";
BA_ "ISignalName" SG_ 312 StatShutoffValveCCGearboxSP2018 "StatShutoffValveCCGearboxSP2018";
BA_ "LongName" SG_ 312 StatShutoffValveCCGearboxSP2018 "StatShutoffValveCCGearboxSP2018";
BA_ "SysSignalName" SG_ 312 StatShutoffValveCCGearboxSP2018 "StatShutoffValveCCGearboxSP2018";
BA_ "CompuMethodName" SG_ 101 CRC_INFO_VEH_DRV "CRC8";
BA_ "ISignalName" SG_ 101 CRC_INFO_VEH_DRV "CRC_INFO_VEH_DRV";
BA_ "LongName" SG_ 101 CRC_INFO_VEH_DRV "CRC_Information_Fahrzeug_Antrieb";
BA_ "SysSignalName" SG_ 101 CRC_INFO_VEH_DRV "CRC_INFO_VEH_DRV";
BA_ "CompuMethodName" SG_ 101 ALIV_INFO_VEH_DRV "ALIV_4_BIT_UInt";
BA_ "ISignalName" SG_ 101 ALIV_INFO_VEH_DRV "ALIV_INFO_VEH_DRV";
BA_ "LongName" SG_ 101 ALIV_INFO_VEH_DRV "Alive_Information_Fahrzeug_Antrieb";
BA_ "SysSignalName" SG_ 101 ALIV_INFO_VEH_DRV "ALIV_INFO_VEH_DRV";
BA_ "CompuMethodName" SG_ 101 CHL_INFO_VEH_DRV "CHL_4Uint";
BA_ "ISignalName" SG_ 101 CHL_INFO_VEH_DRV "CHL_INFO_VEH_DRV";
BA_ "LongName" SG_ 101 CHL_INFO_VEH_DRV "CHL_Information_Fahrzeug_Antrieb";
BA_ "SysSignalName" SG_ 101 CHL_INFO_VEH_DRV "CHL_INFO_VEH_DRV";
BA_ "CompuMethodName" SG_ 101 RQ_FN_DRV "RQ_FN_DRV";
BA_ "ISignalName" SG_ 101 RQ_FN_DRV "RQ_FN_DRV";
BA_ "LongName" SG_ 101 RQ_FN_DRV "Anforderung_Funktion_Antrieb";
BA_ "SysSignalName" SG_ 101 RQ_FN_DRV "RQ_FN_DRV";
BA_ "CompuMethodName" SG_ 101 ST_BL_SW "ST_BL_SW";
BA_ "ISignalName" SG_ 101 ST_BL_SW "ST_BL_SW";
BA_ "LongName" SG_ 101 ST_BL_SW "Status_Bremslicht_Schalter";
BA_ "SysSignalName" SG_ 101 ST_BL_SW "ST_BL_SW";
BA_ "CompuMethodName" SG_ 101 ST_CLT_SW "ST_CLT_SW";
BA_ "ISignalName" SG_ 101 ST_CLT_SW "ST_CLT_SW";
BA_ "LongName" SG_ 101 ST_CLT_SW "Status_Kupplung_Schalter";
BA_ "SysSignalName" SG_ 101 ST_CLT_SW "ST_CLT_SW";
BA_ "CompuMethodName" SG_ 101 ST_MSA_PUBU "ST_MSA_PUBU";
BA_ "ISignalName" SG_ 101 ST_MSA_PUBU "ST_MSA_PUBU";
BA_ "LongName" SG_ 101 ST_MSA_PUBU "Status_MSA_Taster";
BA_ "SysSignalName" SG_ 101 ST_MSA_PUBU "ST_MSA_PUBU";
BA_ "CompuMethodName" SG_ 101 ST_OP_SSP "ST_OP_SSP";
BA_ "ISignalName" SG_ 101 ST_OP_SSP "ST_OP_SSP";
BA_ "LongName" SG_ 101 ST_OP_SSP "Status_Bedienung_Start-Stop-Taster";
BA_ "SysSignalName" SG_ 101 ST_OP_SSP "ST_OP_SSP";
BA_ "CompuMethodName" SG_ 101 ST_GPWSUP_STRT "ST_GPWSUP_STRT";
BA_ "ISignalName" SG_ 101 ST_GPWSUP_STRT "ST_GPWSUP_STRT";
BA_ "LongName" SG_ 101 ST_GPWSUP_STRT "Status_Stromversorgung_Anlasser";
BA_ "SysSignalName" SG_ 101 ST_GPWSUP_STRT "ST_GPWSUP_STRT";
BA_ "ISignalName" SG_ 101 INFO_VEH_DRV_dummy_32_63 "INFO_VEH_DRV_dummy_32_63";
BA_ "LongName" SG_ 101 INFO_VEH_DRV_dummy_32_63 "INFO_VEH_DRV_dummy_32_63";
BA_ "SysSignalName" SG_ 101 INFO_VEH_DRV_dummy_32_63 "INFO_VEH_DRV_dummy_32_63";
BA_ "CompuMethodName" SG_ 642 INQY_PWR_COOL_BT_AIC "INQY_PWR_6300";
BA_ "ISignalName" SG_ 642 INQY_PWR_COOL_BT_AIC "INQY_PWR_COOL_BT_AIC";
BA_ "LongName" SG_ 642 INQY_PWR_COOL_BT_AIC "Anfrage_Leistung_Kühlung_Batterie_Klima";
BA_ "SysSignalName" SG_ 642 INQY_PWR_COOL_BT_AIC "INQY_PWR_COOL_BT_AIC";
BA_ "CompuMethodName" SG_ 642 INQY_PWR_COOL_BT_FAST_AIC "INQY_PWR_6300";
BA_ "ISignalName" SG_ 642 INQY_PWR_COOL_BT_FAST_AIC "INQY_PWR_COOL_BT_FAST_AIC";
BA_ "LongName" SG_ 642 INQY_PWR_COOL_BT_FAST_AIC "Anfrage_Leistung_Kühlung_Batterie_Schnell_Klima";
BA_ "SysSignalName" SG_ 642 INQY_PWR_COOL_BT_FAST_AIC "INQY_PWR_COOL_BT_FAST_AIC";
BA_ "CompuMethodName" SG_ 642 INQY_PWR_DFR_AIC "INQY_PWR_102300";
BA_ "ISignalName" SG_ 642 INQY_PWR_DFR_AIC "INQY_PWR_DFR_AIC";
BA_ "LongName" SG_ 642 INQY_PWR_DFR_AIC "Anfrage_Leistung_Defrost_Klima";
BA_ "SysSignalName" SG_ 642 INQY_PWR_DFR_AIC "INQY_PWR_DFR_AIC";
BA_ "CompuMethodName" SG_ 642 INQY_PWR_FOG_AIC "INQY_PWR_102300";
BA_ "ISignalName" SG_ 642 INQY_PWR_FOG_AIC "INQY_PWR_FOG_AIC";
BA_ "LongName" SG_ 642 INQY_PWR_FOG_AIC "Anfrage_Leistung_Beschlag_Klima";
BA_ "SysSignalName" SG_ 642 INQY_PWR_FOG_AIC "INQY_PWR_FOG_AIC";
BA_ "CompuMethodName" SG_ 645 INQY_PWR_CLDWN_AIC "INQY_PWR_6300";
BA_ "ISignalName" SG_ 645 INQY_PWR_CLDWN_AIC "INQY_PWR_CLDWN_AIC";
BA_ "LongName" SG_ 645 INQY_PWR_CLDWN_AIC "Anfrage_Leistung_Abkühlung_Klima";
BA_ "SysSignalName" SG_ 645 INQY_PWR_CLDWN_AIC "INQY_PWR_CLDWN_AIC";
BA_ "CompuMethodName" SG_ 645 INQY_PWR_HTUP_AIC "INQY_PWR_6300";
BA_ "ISignalName" SG_ 645 INQY_PWR_HTUP_AIC "INQY_PWR_HTUP_AIC";
BA_ "LongName" SG_ 645 INQY_PWR_HTUP_AIC "Anfrage_Leistung_Aufheizung_Klima";
BA_ "SysSignalName" SG_ 645 INQY_PWR_HTUP_AIC "INQY_PWR_HTUP_AIC";
BA_ "CompuMethodName" SG_ 645 INQY_PWR_CNSR_COOL_AIC "INQY_PWR_6300";
BA_ "ISignalName" SG_ 645 INQY_PWR_CNSR_COOL_AIC "INQY_PWR_CNSR_COOL_AIC";
BA_ "LongName" SG_ 645 INQY_PWR_CNSR_COOL_AIC "Anfrage_Leistung_Erhaltung_Kühlung_Klima";
BA_ "SysSignalName" SG_ 645 INQY_PWR_CNSR_COOL_AIC "INQY_PWR_CNSR_COOL_AIC";
BA_ "CompuMethodName" SG_ 645 INQY_PWR_CNSR_HT_AIC "INQY_PWR_6300";
BA_ "ISignalName" SG_ 645 INQY_PWR_CNSR_HT_AIC "INQY_PWR_CNSR_HT_AIC";
BA_ "LongName" SG_ 645 INQY_PWR_CNSR_HT_AIC "Anfrage_Leistung_Erhaltung_Heizung_Klima";
BA_ "SysSignalName" SG_ 645 INQY_PWR_CNSR_HT_AIC "INQY_PWR_CNSR_HT_AIC";
BA_ "CompuMethodName" SG_ 645 INQY_PWR_PRECOND_INO_AIC "INQY_PWR_6300";
BA_ "ISignalName" SG_ 645 INQY_PWR_PRECOND_INO_AIC "INQY_PWR_PRECOND_INO_AIC";
BA_ "LongName" SG_ 645 INQY_PWR_PRECOND_INO_AIC "Anfrage_Leistung_Vorkonditionierung_Innenraum_Klima";
BA_ "SysSignalName" SG_ 645 INQY_PWR_PRECOND_INO_AIC "INQY_PWR_PRECOND_INO_AIC";
BA_ "CompuMethodName" SG_ 1189 TheoreticalMaxChargingPowerVehAC "TheoreticalMaxChargingPowerVehAC";
BA_ "ISignalName" SG_ 1189 TheoreticalMaxChargingPowerVehAC "TheoreticalMaxChargingPowerVehAC";
BA_ "LongName" SG_ 1189 TheoreticalMaxChargingPowerVehAC "TheoreticalMaxChargingPowerVehAC";
BA_ "SysSignalName" SG_ 1189 TheoreticalMaxChargingPowerVehAC "TheoreticalMaxChargingPowerVehAC";
BA_ "CompuMethodName" SG_ 1189 TheoreticalMaxChargingPowerVehDC "TheoreticalMaxChargingPowerVehDC";
BA_ "ISignalName" SG_ 1189 TheoreticalMaxChargingPowerVehDC "TheoreticalMaxChargingPowerVehDC";
BA_ "LongName" SG_ 1189 TheoreticalMaxChargingPowerVehDC "TheoreticalMaxChargingPowerVehDC";
BA_ "SysSignalName" SG_ 1189 TheoreticalMaxChargingPowerVehDC "TheoreticalMaxChargingPowerVehDC";
BA_ "CompuMethodName" SG_ 1189 ActAvailMaxChargingPowerVehAC "ActAvailMaxChargingPowerVehAC";
BA_ "ISignalName" SG_ 1189 ActAvailMaxChargingPowerVehAC "ActAvailMaxChargingPowerVehAC";
BA_ "LongName" SG_ 1189 ActAvailMaxChargingPowerVehAC "ActAvailMaxChargingPowerVehAC";
BA_ "SysSignalName" SG_ 1189 ActAvailMaxChargingPowerVehAC "ActAvailMaxChargingPowerVehAC";
BA_ "CompuMethodName" SG_ 1189 ActAvailMaxChargingPowerVehDC "ActAvailMaxChargingPowerVehDC";
BA_ "ISignalName" SG_ 1189 ActAvailMaxChargingPowerVehDC "ActAvailMaxChargingPowerVehDC";
BA_ "LongName" SG_ 1189 ActAvailMaxChargingPowerVehDC "ActAvailMaxChargingPowerVehDC";
BA_ "SysSignalName" SG_ 1189 ActAvailMaxChargingPowerVehDC "ActAvailMaxChargingPowerVehDC";
BA_ "CompuMethodName" SG_ 816 MILE_KM "MILE_KM";
BA_ "ISignalName" SG_ 816 MILE_KM "MILE_KM";
BA_ "LongName" SG_ 816 MILE_KM "Wegstrecke_Kilometer";
BA_ "SysSignalName" SG_ 816 MILE_KM "MILE_KM";
BA_ "CompuMethodName" SG_ 816 FLLV_FUTA "FLLV_FUTA";
BA_ "ISignalName" SG_ 816 FLLV_FUTA "FLLV_FUTA";
BA_ "LongName" SG_ 816 FLLV_FUTA "Füllstand_Tank";
BA_ "SysSignalName" SG_ 816 FLLV_FUTA "FLLV_FUTA";
BA_ "CompuMethodName" SG_ 816 FLLV_FUTA_LH "FLLV_FUTA_LH";
BA_ "ISignalName" SG_ 816 FLLV_FUTA_LH "FLLV_FUTA_LH";
BA_ "LongName" SG_ 816 FLLV_FUTA_LH "Füllstand_Tank_Links";
BA_ "SysSignalName" SG_ 816 FLLV_FUTA_LH "FLLV_FUTA_LH";
BA_ "CompuMethodName" SG_ 816 FLLV_FUTA_RH "FLLV_FUTA_RH";
BA_ "ISignalName" SG_ 816 FLLV_FUTA_RH "FLLV_FUTA_RH";
BA_ "LongName" SG_ 816 FLLV_FUTA_RH "fluid-level_fuel-tank_right-hand";
BA_ "SysSignalName" SG_ 816 FLLV_FUTA_RH "FLLV_FUTA_RH";
BA_ "CompuMethodName" SG_ 816 ST_FLLV_FUTA_SPAR "ST_FLLV_FUTA_SPAR";
BA_ "ISignalName" SG_ 816 ST_FLLV_FUTA_SPAR "ST_FLLV_FUTA_SPAR";
BA_ "LongName" SG_ 816 ST_FLLV_FUTA_SPAR "Status_Füllstand_Tank_Reserve";
BA_ "SysSignalName" SG_ 816 ST_FLLV_FUTA_SPAR "ST_FLLV_FUTA_SPAR";
BA_ "CompuMethodName" SG_ 816 RNG "RNG";
BA_ "ISignalName" SG_ 816 RNG "RNG";
BA_ "LongName" SG_ 816 RNG "Reichweite";
BA_ "SysSignalName" SG_ 816 RNG "RNG";
BA_ "CompuMethodName" SG_ 2675539972 KI_DBG_Dummy_11 "KI_DBG_Dummy_11";
BA_ "ISignalName" SG_ 2675539972 KI_DBG_Dummy_11 "KI_DBG_Dummy_11";
BA_ "LongName" SG_ 2675539972 KI_DBG_Dummy_11 "Kombi_Debug_Dummy_11";
BA_ "SysSignalName" SG_ 2675539972 KI_DBG_Dummy_11 "KI_DBG_Dummy_11";
BA_ "CompuMethodName" SG_ 2675539972 KI_DBG_Dummy_12 "KI_DBG_Dummy_11";
BA_ "ISignalName" SG_ 2675539972 KI_DBG_Dummy_12 "KI_DBG_Dummy_12";
BA_ "LongName" SG_ 2675539972 KI_DBG_Dummy_12 "Kombi_Debug_Dummy_12";
BA_ "SysSignalName" SG_ 2675539972 KI_DBG_Dummy_12 "KI_DBG_Dummy_12";
BA_ "CompuMethodName" SG_ 2675539972 KI_DBG_Dummy_13 "KI_DBG_Dummy_11";
BA_ "ISignalName" SG_ 2675539972 KI_DBG_Dummy_13 "KI_DBG_Dummy_13";
BA_ "LongName" SG_ 2675539972 KI_DBG_Dummy_13 "Kombi_Debug_Dummy_13";
BA_ "SysSignalName" SG_ 2675539972 KI_DBG_Dummy_13 "KI_DBG_Dummy_13";
BA_ "CompuMethodName" SG_ 2675539972 KI_DBG_Dummy_14 "KI_DBG_Dummy_11";
BA_ "ISignalName" SG_ 2675539972 KI_DBG_Dummy_14 "KI_DBG_Dummy_14";
BA_ "LongName" SG_ 2675539972 KI_DBG_Dummy_14 "Kombi_Debug_Dummy_14";
BA_ "SysSignalName" SG_ 2675539972 KI_DBG_Dummy_14 "KI_DBG_Dummy_14";
BA_ "CompuMethodName" SG_ 2675539972 KI_DBG_WD_Dummy_11 "KI_DBG_WD_Dummy_11";
BA_ "ISignalName" SG_ 2675539972 KI_DBG_WD_Dummy_11 "KI_DBG_WD_Dummy_11";
BA_ "LongName" SG_ 2675539972 KI_DBG_WD_Dummy_11 "Kombi_Debug_Wort_Dummy_11";
BA_ "SysSignalName" SG_ 2675539972 KI_DBG_WD_Dummy_11 "KI_DBG_WD_Dummy_11";
BA_ "CompuMethodName" SG_ 2675539972 KI_DBG_WD_Dummy_12 "KI_DBG_WD_Dummy_11";
BA_ "ISignalName" SG_ 2675539972 KI_DBG_WD_Dummy_12 "KI_DBG_WD_Dummy_12";
BA_ "LongName" SG_ 2675539972 KI_DBG_WD_Dummy_12 "Kombi_Debug_Wort_Dummy_12";
BA_ "SysSignalName" SG_ 2675539972 KI_DBG_WD_Dummy_12 "KI_DBG_WD_Dummy_12";
BA_ "CompuMethodName" SG_ 2675539973 KI_DBG_Dummy_21 "KI_DBG_Dummy_11";
BA_ "ISignalName" SG_ 2675539973 KI_DBG_Dummy_21 "KI_DBG_Dummy_21";
BA_ "LongName" SG_ 2675539973 KI_DBG_Dummy_21 "Kombi_Debug_Dummy_21";
BA_ "SysSignalName" SG_ 2675539973 KI_DBG_Dummy_21 "KI_DBG_Dummy_21";
BA_ "CompuMethodName" SG_ 2675539973 KI_DBG_Dummy_22 "KI_DBG_Dummy_11";
BA_ "ISignalName" SG_ 2675539973 KI_DBG_Dummy_22 "KI_DBG_Dummy_22";
BA_ "LongName" SG_ 2675539973 KI_DBG_Dummy_22 "Kombi_Debug_Dummy_22";
BA_ "SysSignalName" SG_ 2675539973 KI_DBG_Dummy_22 "KI_DBG_Dummy_22";
BA_ "CompuMethodName" SG_ 2675539973 KI_DBG_Dummy_23 "KI_DBG_Dummy_11";
BA_ "ISignalName" SG_ 2675539973 KI_DBG_Dummy_23 "KI_DBG_Dummy_23";
BA_ "LongName" SG_ 2675539973 KI_DBG_Dummy_23 "Kombi_Debug_Dummy_23";
BA_ "SysSignalName" SG_ 2675539973 KI_DBG_Dummy_23 "KI_DBG_Dummy_23";
BA_ "CompuMethodName" SG_ 2675539973 KI_DBG_Dummy_24 "KI_DBG_Dummy_11";
BA_ "ISignalName" SG_ 2675539973 KI_DBG_Dummy_24 "KI_DBG_Dummy_24";
BA_ "LongName" SG_ 2675539973 KI_DBG_Dummy_24 "Kombi_Debug_Dummy_24";
BA_ "SysSignalName" SG_ 2675539973 KI_DBG_Dummy_24 "KI_DBG_Dummy_24";
BA_ "CompuMethodName" SG_ 2675539973 KI_DBG_WD_Dummy_21 "KI_DBG_WD_Dummy_11";
BA_ "ISignalName" SG_ 2675539973 KI_DBG_WD_Dummy_21 "KI_DBG_WD_Dummy_21";
BA_ "LongName" SG_ 2675539973 KI_DBG_WD_Dummy_21 "Kombi_Debug_Wort_Dummy_21";
BA_ "SysSignalName" SG_ 2675539973 KI_DBG_WD_Dummy_21 "KI_DBG_WD_Dummy_21";
BA_ "CompuMethodName" SG_ 2675539973 KI_DBG_WD_Dummy_22 "KI_DBG_WD_Dummy_11";
BA_ "ISignalName" SG_ 2675539973 KI_DBG_WD_Dummy_22 "KI_DBG_WD_Dummy_22";
BA_ "LongName" SG_ 2675539973 KI_DBG_WD_Dummy_22 "Kombi_Debug_Wort_Dummy_22";
BA_ "SysSignalName" SG_ 2675539973 KI_DBG_WD_Dummy_22 "KI_DBG_WD_Dummy_22";
BA_ "CompuMethodName" SG_ 2675539969 DBG_FUTA_DISP "DBG_FUTA";
BA_ "ISignalName" SG_ 2675539969 DBG_FUTA_DISP "DBG_FUTA_DISP";
BA_ "LongName" SG_ 2675539969 DBG_FUTA_DISP "Debug_Tank_Anzeige";
BA_ "SysSignalName" SG_ 2675539969 DBG_FUTA_DISP "DBG_FUTA_DISP";
BA_ "CompuMethodName" SG_ 2675539969 DBG_FUTA_DISP_RAW "DBG_FUTA";
BA_ "ISignalName" SG_ 2675539969 DBG_FUTA_DISP_RAW "DBG_FUTA_DISP_RAW";
BA_ "LongName" SG_ 2675539969 DBG_FUTA_DISP_RAW "Debug_Tank_Anzeige_Roh";
BA_ "SysSignalName" SG_ 2675539969 DBG_FUTA_DISP_RAW "DBG_FUTA_DISP_RAW";
BA_ "CompuMethodName" SG_ 2675539969 DBG_FUTA_SPT "DBG_FUTA";
BA_ "ISignalName" SG_ 2675539969 DBG_FUTA_SPT "DBG_FUTA_SPT";
BA_ "LongName" SG_ 2675539969 DBG_FUTA_SPT "Debug_Tank_Schwalltopf";
BA_ "SysSignalName" SG_ 2675539969 DBG_FUTA_SPT "DBG_FUTA_SPT";
BA_ "CompuMethodName" SG_ 2675539969 DBG_FUTA_ST "DBG_FUTA_ST";
BA_ "ISignalName" SG_ 2675539969 DBG_FUTA_ST "DBG_FUTA_ST";
BA_ "LongName" SG_ 2675539969 DBG_FUTA_ST "Debug_Tank_Status";
BA_ "SysSignalName" SG_ 2675539969 DBG_FUTA_ST "DBG_FUTA_ST";
BA_ "CompuMethodName" SG_ 2675539969 DBG_FUTA_PHA "DBG_FUTA_PHA";
BA_ "ISignalName" SG_ 2675539969 DBG_FUTA_PHA "DBG_FUTA_PHA";
BA_ "LongName" SG_ 2675539969 DBG_FUTA_PHA "Debug_Tank_Phase";
BA_ "SysSignalName" SG_ 2675539969 DBG_FUTA_PHA "DBG_FUTA_PHA";
BA_ "CompuMethodName" SG_ 2675539971 DBG_RNG_BUR_RAW "DBG_RNG_BUR_RAW";
BA_ "ISignalName" SG_ 2675539971 DBG_RNG_BUR_RAW "DBG_RNG_BUR_RAW";
BA_ "LongName" SG_ 2675539971 DBG_RNG_BUR_RAW "Debug_Reichweite_Verbrenner_Roh";
BA_ "SysSignalName" SG_ 2675539971 DBG_RNG_BUR_RAW "DBG_RNG_BUR_RAW";
BA_ "CompuMethodName" SG_ 2675539971 DBG_RNG_BUR_DISP "DBG_RNG_BUR_RAW";
BA_ "ISignalName" SG_ 2675539971 DBG_RNG_BUR_DISP "DBG_RNG_BUR_DISP";
BA_ "LongName" SG_ 2675539971 DBG_RNG_BUR_DISP "Debug_Reichweite_Verbrenner_Anzeige";
BA_ "SysSignalName" SG_ 2675539971 DBG_RNG_BUR_DISP "DBG_RNG_BUR_DISP";
BA_ "CompuMethodName" SG_ 2675539971 DBG_RNG_BUR_COSP "DBG_RNG_BUR_COSP";
BA_ "ISignalName" SG_ 2675539971 DBG_RNG_BUR_COSP "DBG_RNG_BUR_COSP";
BA_ "LongName" SG_ 2675539971 DBG_RNG_BUR_COSP "Debug_Reichweite_Verbrenner_Verbrauch";
BA_ "SysSignalName" SG_ 2675539971 DBG_RNG_BUR_COSP "DBG_RNG_BUR_COSP";
BA_ "CompuMethodName" SG_ 2675539971 DBG_RNG_DMPNG_RATE "DBG_RNG_DMPNG_RATE";
BA_ "ISignalName" SG_ 2675539971 DBG_RNG_DMPNG_RATE "DBG_RNG_DMPNG_RATE";
BA_ "LongName" SG_ 2675539971 DBG_RNG_DMPNG_RATE "Debug_Reichweite_Dämpfung_Rate";
BA_ "SysSignalName" SG_ 2675539971 DBG_RNG_DMPNG_RATE "DBG_RNG_DMPNG_RATE";
BA_ "CompuMethodName" SG_ 2675539970 DBG_RNG_EL_RAW "DBG_RNG_EL_RAW";
BA_ "ISignalName" SG_ 2675539970 DBG_RNG_EL_RAW "DBG_RNG_EL_RAW";
BA_ "LongName" SG_ 2675539970 DBG_RNG_EL_RAW "Debug_Reichweite_Elektrisch_Roh";
BA_ "SysSignalName" SG_ 2675539970 DBG_RNG_EL_RAW "DBG_RNG_EL_RAW";
BA_ "CompuMethodName" SG_ 2675539970 DBG_RNG_EL_DISP "DBG_RNG_EL_RAW";
BA_ "ISignalName" SG_ 2675539970 DBG_RNG_EL_DISP "DBG_RNG_EL_DISP";
BA_ "LongName" SG_ 2675539970 DBG_RNG_EL_DISP "Debug_Reichweite_Elektrisch_Anzeige";
BA_ "SysSignalName" SG_ 2675539970 DBG_RNG_EL_DISP "DBG_RNG_EL_DISP";
BA_ "CompuMethodName" SG_ 2675539970 DBG_RNG_EL_V "DBG_RNG_EL_RAW";
BA_ "ISignalName" SG_ 2675539970 DBG_RNG_EL_V "DBG_RNG_EL_V";
BA_ "LongName" SG_ 2675539970 DBG_RNG_EL_V "Debug_Reichweite_Elektrisch_Geschwindigkeit";
BA_ "SysSignalName" SG_ 2675539970 DBG_RNG_EL_V "DBG_RNG_EL_V";
BA_ "CompuMethodName" SG_ 2675539970 DBG_RNG_EL_MV_REF "DBG_RNG_EL_MV_REF";
BA_ "ISignalName" SG_ 2675539970 DBG_RNG_EL_MV_REF "DBG_RNG_EL_MV_REF";
BA_ "LongName" SG_ 2675539970 DBG_RNG_EL_MV_REF "Debug_Reichweite_Elektrisch_Mehrverbrauch_Referenz";
BA_ "SysSignalName" SG_ 2675539970 DBG_RNG_EL_MV_REF "DBG_RNG_EL_MV_REF";
BA_ "CompuMethodName" SG_ 2675539970 DBG_RNG_EL_COSP_DRV "DBG_RNG_EL_COSP_DRV";
BA_ "ISignalName" SG_ 2675539970 DBG_RNG_EL_COSP_DRV "DBG_RNG_EL_COSP_DRV";
BA_ "LongName" SG_ 2675539970 DBG_RNG_EL_COSP_DRV "Debug_Reichweite_Elektrisch_Verbrauch_Antrieb";
BA_ "SysSignalName" SG_ 2675539970 DBG_RNG_EL_COSP_DRV "DBG_RNG_EL_COSP_DRV";
BA_ "CompuMethodName" SG_ 2675539968 DBG_FUTA_RESI_LH "DBG_FUTA_RESI";
BA_ "ISignalName" SG_ 2675539968 DBG_FUTA_RESI_LH "DBG_FUTA_RESI_LH";
BA_ "LongName" SG_ 2675539968 DBG_FUTA_RESI_LH "Debug_Tank_Widerstand_Links";
BA_ "SysSignalName" SG_ 2675539968 DBG_FUTA_RESI_LH "DBG_FUTA_RESI_LH";
BA_ "CompuMethodName" SG_ 2675539968 DBG_FUTA_RESI_RH "DBG_FUTA_RESI";
BA_ "ISignalName" SG_ 2675539968 DBG_FUTA_RESI_RH "DBG_FUTA_RESI_RH";
BA_ "LongName" SG_ 2675539968 DBG_FUTA_RESI_RH "Debug_Tank_Widerstand_Rechts";
BA_ "SysSignalName" SG_ 2675539968 DBG_FUTA_RESI_RH "DBG_FUTA_RESI_RH";
BA_ "CompuMethodName" SG_ 2675539968 DBG_FUTA_LH "DBG_FUTA";
BA_ "ISignalName" SG_ 2675539968 DBG_FUTA_LH "DBG_FUTA_LH";
BA_ "LongName" SG_ 2675539968 DBG_FUTA_LH "Debug_Tank_Links";
BA_ "SysSignalName" SG_ 2675539968 DBG_FUTA_LH "DBG_FUTA_LH";
BA_ "CompuMethodName" SG_ 2675539968 DBG_FUTA_RH "DBG_FUTA";
BA_ "ISignalName" SG_ 2675539968 DBG_FUTA_RH "DBG_FUTA_RH";
BA_ "LongName" SG_ 2675539968 DBG_FUTA_RH "Debug_Tank_Rechts";
BA_ "SysSignalName" SG_ 2675539968 DBG_FUTA_RH "DBG_FUTA_RH";
BA_ "CompuMethodName" SG_ 303 CRC_KL "CRC8";
BA_ "ISignalName" SG_ 303 CRC_KL "CRC_KL";
BA_ "LongName" SG_ 303 CRC_KL "CRC_Klemme";
BA_ "SysSignalName" SG_ 303 CRC_KL "CRC_KL";
BA_ "CompuMethodName" SG_ 303 ALIV_COU_KL "ALIV_COU_4";
BA_ "ISignalName" SG_ 303 ALIV_COU_KL "ALIV_COU_KL";
BA_ "LongName" SG_ 303 ALIV_COU_KL "Alive_Zähler_Klemme";
BA_ "SysSignalName" SG_ 303 ALIV_COU_KL "ALIV_COU_KL";
BA_ "CompuMethodName" SG_ 303 ST_VEH_CON "ST_VEH_CON";
BA_ "ISignalName" SG_ 303 ST_VEH_CON "ST_VEH_CON";
BA_ "LongName" SG_ 303 ST_VEH_CON "Status_Fahrzeug_Zustand";
BA_ "SysSignalName" SG_ 303 ST_VEH_CON "ST_VEH_CON";
BA_ "CompuMethodName" SG_ 303 ST_KL "ST_KL";
BA_ "ISignalName" SG_ 303 ST_KL "ST_KL";
BA_ "LongName" SG_ 303 ST_KL "Status_Klemme";
BA_ "SysSignalName" SG_ 303 ST_KL "ST_KL";
BA_ "ISignalName" SG_ 303 KLEMMEN_dummy_20_23 "KLEMMEN_dummy_20_23";
BA_ "LongName" SG_ 303 KLEMMEN_dummy_20_23 "KLEMMEN_dummy_20_23";
BA_ "SysSignalName" SG_ 303 KLEMMEN_dummy_20_23 "KLEMMEN_dummy_20_23";
BA_ "CompuMethodName" SG_ 303 ST_KL_30B "ST_KL_30B";
BA_ "ISignalName" SG_ 303 ST_KL_30B "ST_KL_30B";
BA_ "LongName" SG_ 303 ST_KL_30B "Status_Klemme_30b";
BA_ "SysSignalName" SG_ 303 ST_KL_30B "ST_KL_30B";
BA_ "CompuMethodName" SG_ 303 ST_KL_15N "ST_KL_15N";
BA_ "ISignalName" SG_ 303 ST_KL_15N "ST_KL_15N";
BA_ "LongName" SG_ 303 ST_KL_15N "Status_Klemme_15n";
BA_ "SysSignalName" SG_ 303 ST_KL_15N "ST_KL_15N";
BA_ "ISignalName" SG_ 303 KLEMMEN_dummy_32_55 "KLEMMEN_dummy_32_55";
BA_ "LongName" SG_ 303 KLEMMEN_dummy_32_55 "KLEMMEN_dummy_32_55";
BA_ "SysSignalName" SG_ 303 KLEMMEN_dummy_32_55 "KLEMMEN_dummy_32_55";
BA_ "CompuMethodName" SG_ 303 ST_KL_DBG "ST_KL_DBG";
BA_ "ISignalName" SG_ 303 ST_KL_DBG "ST_KL_DBG";
BA_ "LongName" SG_ 303 ST_KL_DBG "Status_Klemme_Debug";
BA_ "SysSignalName" SG_ 303 ST_KL_DBG "ST_KL_DBG";
BA_ "CompuMethodName" SG_ 413 MILE_KM_TOT "MILE_KM_TOT";
BA_ "ISignalName" SG_ 413 MILE_KM_TOT "MILE_KM_TOT";
BA_ "LongName" SG_ 413 MILE_KM_TOT "Wegstrecke_Kilometer_Gesamt";
BA_ "SysSignalName" SG_ 413 MILE_KM_TOT "MILE_KM_TOT";
BA_ "CompuMethodName" SG_ 538 ST_DIPB "ST_DIPB";
BA_ "ISignalName" SG_ 538 ST_DIPB "ST_DIPB";
BA_ "LongName" SG_ 538 ST_DIPB "Status_Abblendlicht";
BA_ "SysSignalName" SG_ 538 ST_DIPB "ST_DIPB";
BA_ "CompuMethodName" SG_ 538 ST_MBHF "ST_MBHF";
BA_ "ISignalName" SG_ 538 ST_MBHF "ST_MBHF";
BA_ "LongName" SG_ 538 ST_MBHF "Status_Fernlicht/Lichthupe";
BA_ "SysSignalName" SG_ 538 ST_MBHF "ST_MBHF";
BA_ "CompuMethodName" SG_ 538 ST_POLI "ST_POLI";
BA_ "ISignalName" SG_ 538 ST_POLI "ST_POLI";
BA_ "LongName" SG_ 538 ST_POLI "Status_Standlicht";
BA_ "SysSignalName" SG_ 538 ST_POLI "ST_POLI";
BA_ "CompuMethodName" SG_ 538 ST_PLI_LH "ST_PLI_LH";
BA_ "ISignalName" SG_ 538 ST_PLI_LH "ST_PLI_LH";
BA_ "LongName" SG_ 538 ST_PLI_LH "Status_Parklicht_Links";
BA_ "SysSignalName" SG_ 538 ST_PLI_LH "ST_PLI_LH";
BA_ "CompuMethodName" SG_ 538 ST_PLI_RH "ST_PLI_RH";
BA_ "ISignalName" SG_ 538 ST_PLI_RH "ST_PLI_RH";
BA_ "LongName" SG_ 538 ST_PLI_RH "Status_Parklicht_Rechts";
BA_ "SysSignalName" SG_ 538 ST_PLI_RH "ST_PLI_RH";
BA_ "CompuMethodName" SG_ 538 ST_FFLI "ST_FFLI";
BA_ "ISignalName" SG_ 538 ST_FFLI "ST_FFLI";
BA_ "LongName" SG_ 538 ST_FFLI "Status_Nebelscheinwerfer";
BA_ "SysSignalName" SG_ 538 ST_FFLI "ST_FFLI";
BA_ "CompuMethodName" SG_ 538 ST_RFLI "ST_RFLI";
BA_ "ISignalName" SG_ 538 ST_RFLI "ST_RFLI";
BA_ "LongName" SG_ 538 ST_RFLI "Status_Nebelschlußleuchte";
BA_ "SysSignalName" SG_ 538 ST_RFLI "ST_RFLI";
BA_ "CompuMethodName" SG_ 538 ST_STLI "ST_STLI";
BA_ "ISignalName" SG_ 538 ST_STLI "ST_STLI";
BA_ "LongName" SG_ 538 ST_STLI "Status_Bremsleuchte";
BA_ "SysSignalName" SG_ 538 ST_STLI "ST_STLI";
BA_ "CompuMethodName" SG_ 538 ST_RVLI "ST_RVLI";
BA_ "ISignalName" SG_ 538 ST_RVLI "ST_RVLI";
BA_ "LongName" SG_ 538 ST_RVLI "Status_Rückfahrscheinwerfer";
BA_ "SysSignalName" SG_ 538 ST_RVLI "ST_RVLI";
BA_ "CompuMethodName" SG_ 538 ST_RPLIS "ST_RPLIS";
BA_ "ISignalName" SG_ 538 ST_RPLIS "ST_RPLIS";
BA_ "LongName" SG_ 538 ST_RPLIS "Status_Kennzeichenleuchten";
BA_ "SysSignalName" SG_ 538 ST_RPLIS "ST_RPLIS";
BA_ "CompuMethodName" SG_ 538 ST_LOWB_DAY "ST_LOWB_DAY";
BA_ "ISignalName" SG_ 538 ST_LOWB_DAY "ST_LOWB_DAY";
BA_ "LongName" SG_ 538 ST_LOWB_DAY "Status_Fahrlicht_Tag";
BA_ "SysSignalName" SG_ 538 ST_LOWB_DAY "ST_LOWB_DAY";
BA_ "CompuMethodName" SG_ 538 ST_LIST_ERR "ST_LIST_ERR";
BA_ "ISignalName" SG_ 538 ST_LIST_ERR "ST_LIST_ERR";
BA_ "LongName" SG_ 538 ST_LIST_ERR "Status_Lampenzustand_Fehler";
BA_ "SysSignalName" SG_ 538 ST_LIST_ERR "ST_LIST_ERR";
BA_ "CompuMethodName" SG_ 538 ST_MAB_ASST "ST_MAB_ASST";
BA_ "ISignalName" SG_ 538 ST_MAB_ASST "ST_MAB_ASST";
BA_ "LongName" SG_ 538 ST_MAB_ASST "Status_Fernlicht_Assistent";
BA_ "SysSignalName" SG_ 538 ST_MAB_ASST "ST_MAB_ASST";
BA_ "CompuMethodName" SG_ 915 DSTN_LCD_LUM "AMBR_1";
BA_ "ISignalName" SG_ 915 DSTN_LCD_LUM "DSTN_LCD_LUM";
BA_ "LongName" SG_ 915 DSTN_LCD_LUM "Ziel_LCD_Leuchtdichte";
BA_ "SysSignalName" SG_ 915 DSTN_LCD_LUM "DSTN_LCD_LUM";
BA_ "CompuMethodName" SG_ 915 DMPNG_LCD_LUM "DMPNG_LCD_LUM";
BA_ "GenSigStartValue" SG_ 915 DMPNG_LCD_LUM 100;
BA_ "ISignalName" SG_ 915 DMPNG_LCD_LUM "DMPNG_LCD_LUM";
BA_ "LongName" SG_ 915 DMPNG_LCD_LUM "Dämpfung_LCD_Leuchtdichte";
BA_ "SysSignalName" SG_ 915 DMPNG_LCD_LUM "DMPNG_LCD_LUM";
BA_ "CompuMethodName" SG_ 915 AMBR_1 "AMBR_1";
BA_ "ISignalName" SG_ 915 AMBR_1 "AMBR_1";
BA_ "LongName" SG_ 915 AMBR_1 "Umgebungshelligkeit_1";
BA_ "SysSignalName" SG_ 915 AMBR_1 "AMBR_1";
BA_ "CompuMethodName" SG_ 915 DAY_NI_CHOV "DAY_NI_CHOV";
BA_ "ISignalName" SG_ 915 DAY_NI_CHOV "DAY_NI_CHOV";
BA_ "LongName" SG_ 915 DAY_NI_CHOV "Tag_Nacht_Umschalten";
BA_ "SysSignalName" SG_ 915 DAY_NI_CHOV "DAY_NI_CHOV";
BA_ "CompuMethodName" SG_ 736 MASS_VEH "MASS_VEH";
BA_ "ISignalName" SG_ 736 MASS_VEH "MASS_VEH";
BA_ "LongName" SG_ 736 MASS_VEH "Masse/Gewicht_Fahrzeug";
BA_ "SysSignalName" SG_ 736 MASS_VEH "MASS_VEH";
BA_ "CompuMethodName" SG_ 736 QU_MASS_VEH "QU_MASS_VEH";
BA_ "ISignalName" SG_ 736 QU_MASS_VEH "QU_MASS_VEH";
BA_ "LongName" SG_ 736 QU_MASS_VEH "Qualifier_Masse/Gewicht_Fahrzeug";
BA_ "SysSignalName" SG_ 736 QU_MASS_VEH "QU_MASS_VEH";
BA_ "CompuMethodName" SG_ 1077 ST_OILV_MEASMT_1 "ST_OILV_MEASMT_1";
BA_ "ISignalName" SG_ 1077 ST_OILV_MEASMT_1 "ST_OILV_MEASMT_1";
BA_ "LongName" SG_ 1077 ST_OILV_MEASMT_1 "Status_Ölstand_Messung_1";
BA_ "SysSignalName" SG_ 1077 ST_OILV_MEASMT_1 "ST_OILV_MEASMT_1";
BA_ "CompuMethodName" SG_ 1077 FLLV_EOI_REL "FLLV_EOI_REL";
BA_ "ISignalName" SG_ 1077 FLLV_EOI_REL "FLLV_EOI_REL";
BA_ "LongName" SG_ 1077 FLLV_EOI_REL "Füllstand_Motoröl_Relativ";
BA_ "SysSignalName" SG_ 1077 FLLV_EOI_REL "FLLV_EOI_REL";
BA_ "CompuMethodName" SG_ 1077 ST_OILV_MEASMT_2 "ST_OILV_MEASMT_2";
BA_ "ISignalName" SG_ 1077 ST_OILV_MEASMT_2 "ST_OILV_MEASMT_2";
BA_ "LongName" SG_ 1077 ST_OILV_MEASMT_2 "Status_Ölstand_Messung_2";
BA_ "SysSignalName" SG_ 1077 ST_OILV_MEASMT_2 "ST_OILV_MEASMT_2";
BA_ "CompuMethodName" SG_ 1077 ST_OILV_MEASMT_POSS "ST_OILV_MEASMT_POSS";
BA_ "ISignalName" SG_ 1077 ST_OILV_MEASMT_POSS "ST_OILV_MEASMT_POSS";
BA_ "LongName" SG_ 1077 ST_OILV_MEASMT_POSS "Status_Ölstand_Messung_Möglich";
BA_ "SysSignalName" SG_ 1077 ST_OILV_MEASMT_POSS "ST_OILV_MEASMT_POSS";
BA_ "CompuMethodName" SG_ 523 ST_MEMO_FN "ST_MEMO_FN";
BA_ "ISignalName" SG_ 523 ST_MEMO_FN "ST_MEMO_FN";
BA_ "LongName" SG_ 523 ST_MEMO_FN "Status_Memory_Funktion";
BA_ "SysSignalName" SG_ 523 ST_MEMO_FN "ST_MEMO_FN";
BA_ "CompuMethodName" SG_ 523 PO_MEMO "PO_MEMO";
BA_ "GenSigStartValue" SG_ 523 PO_MEMO 1;
BA_ "ISignalName" SG_ 523 PO_MEMO "PO_MEMO";
BA_ "LongName" SG_ 523 PO_MEMO "Position_Memory";
BA_ "SysSignalName" SG_ 523 PO_MEMO "PO_MEMO";
BA_ "CompuMethodName" SG_ 699 CRC_MILE_VEH "CRC8";
BA_ "ISignalName" SG_ 699 CRC_MILE_VEH "CRC_MILE_VEH";
BA_ "LongName" SG_ 699 CRC_MILE_VEH "CRC_Wegstrecke_Fahrzeug";
BA_ "SysSignalName" SG_ 699 CRC_MILE_VEH "CRC_MILE_VEH";
BA_ "CompuMethodName" SG_ 699 ALIV_MILE_VEH "Aliv_4";
BA_ "ISignalName" SG_ 699 ALIV_MILE_VEH "ALIV_MILE_VEH";
BA_ "LongName" SG_ 699 ALIV_MILE_VEH "Alive_Wegstrecke_Fahrzeug";
BA_ "SysSignalName" SG_ 699 ALIV_MILE_VEH "ALIV_MILE_VEH";
BA_ "ISignalName" SG_ 699 MILE_VEH_dummy_12_15 "MILE_VEH_dummy_12_15";
BA_ "LongName" SG_ 699 MILE_VEH_dummy_12_15 "MILE_VEH_dummy_12_15";
BA_ "SysSignalName" SG_ 699 MILE_VEH_dummy_12_15 "MILE_VEH_dummy_12_15";
BA_ "CompuMethodName" SG_ 699 MILE_VEH "MILE_VEH";
BA_ "ISignalName" SG_ 699 MILE_VEH "MILE_VEH";
BA_ "LongName" SG_ 699 MILE_VEH "Wegstrecke_Fahrzeug";
BA_ "SysSignalName" SG_ 699 MILE_VEH "MILE_VEH";
BA_ "CompuMethodName" SG_ 699 QU_MILE_VEH "QU_MILE_VEH";
BA_ "ISignalName" SG_ 699 QU_MILE_VEH "QU_MILE_VEH";
BA_ "LongName" SG_ 699 QU_MILE_VEH "Qualifier_Wegstrecke_Fahrzeug";
BA_ "SysSignalName" SG_ 699 QU_MILE_VEH "QU_MILE_VEH";
BA_ "ISignalName" SG_ 699 MILE_VEH_dummy_36_39 "MILE_VEH_dummy_36_39";
BA_ "LongName" SG_ 699 MILE_VEH_dummy_36_39 "MILE_VEH_dummy_36_39";
BA_ "SysSignalName" SG_ 699 MILE_VEH_dummy_36_39 "MILE_VEH_dummy_36_39";
BA_ "CompuMethodName" SG_ 1074 ActualValueThermicCoolingUrgency "ActualValueThermicCoolingUrgencyHighVoltageStorage2";
BA_ "ISignalName" SG_ 1074 ActualValueThermicCoolingUrgency "ActualValueThermicCoolingUrgencyHighVoltageStorage2";
BA_ "LongName" SG_ 1074 ActualValueThermicCoolingUrgency "ActualValueThermicCoolingUrgencyHighVoltageStorage2";
BA_ "SysSignalName" SG_ 1074 ActualValueThermicCoolingUrgency "ActualValueThermicCoolingUrgencyHighVoltageStorage2";
BA_ "SystemSignalLongSymbol" SG_ 1074 ActualValueThermicCoolingUrgency "ActualValueThermicCoolingUrgencyHighVoltageStorage2";
BA_ "CompuMethodName" SG_ 1074 AVL_COOL_HVSTO_1 "AVL_COOL_HVSTO";
BA_ "ISignalName" SG_ 1074 AVL_COOL_HVSTO_1 "AVL_COOL_HVSTO_1";
BA_ "LongName" SG_ 1074 AVL_COOL_HVSTO_1 "Ist_Kühlung_Hochvoltspeicher_1";
BA_ "SysSignalName" SG_ 1074 AVL_COOL_HVSTO_1 "AVL_COOL_HVSTO_1";
BA_ "CompuMethodName" SG_ 1074 ST_AVL_COOL_HVSTO_1 "ST_AVL_COOL_HVSTO";
BA_ "ISignalName" SG_ 1074 ST_AVL_COOL_HVSTO_1 "ST_AVL_COOL_HVSTO_1";
BA_ "LongName" SG_ 1074 ST_AVL_COOL_HVSTO_1 "Status_Ist_Kühlung_Hochvoltspeicher_1";
BA_ "SysSignalName" SG_ 1074 ST_AVL_COOL_HVSTO_1 "ST_AVL_COOL_HVSTO_1";
BA_ "CompuMethodName" SG_ 1074 ST_STOR_AIC_COOL_RQMT "ST_STOR_AIC_COOL_RQMT";
BA_ "ISignalName" SG_ 1074 ST_STOR_AIC_COOL_RQMT "ST_STOR_AIC_COOL_RQMT";
BA_ "LongName" SG_ 1074 ST_STOR_AIC_COOL_RQMT "Status_Speicher_Klima_Kühlung_Bedarf";
BA_ "SysSignalName" SG_ 1074 ST_STOR_AIC_COOL_RQMT "ST_STOR_AIC_COOL_RQMT";
BA_ "CompuMethodName" SG_ 1074 AVL_COOL_HVSTO_2 "AVL_COOL_HVSTO";
BA_ "ISignalName" SG_ 1074 AVL_COOL_HVSTO_2 "AVL_COOL_HVSTO_2";
BA_ "LongName" SG_ 1074 AVL_COOL_HVSTO_2 "Ist_Kühlung_Hochvoltspeicher_2";
BA_ "SysSignalName" SG_ 1074 AVL_COOL_HVSTO_2 "AVL_COOL_HVSTO_2";
BA_ "CompuMethodName" SG_ 1074 ST_AVL_COOL_HVSTO_2 "ST_AVL_COOL_HVSTO";
BA_ "ISignalName" SG_ 1074 ST_AVL_COOL_HVSTO_2 "ST_AVL_COOL_HVSTO_2";
BA_ "LongName" SG_ 1074 ST_AVL_COOL_HVSTO_2 "Status_Ist_Kühlung_Hochvoltspeicher_2";
BA_ "SysSignalName" SG_ 1074 ST_AVL_COOL_HVSTO_2 "ST_AVL_COOL_HVSTO_2";
BA_ "CompuMethodName" SG_ 1085 IDX_PRES_SEG_NAVGRPH_2 "IDX_PRES_SEG_NAVGRPH_2";
BA_ "ISignalName" SG_ 1085 IDX_PRES_SEG_NAVGRPH_2 "IDX_PRES_SEG_NAVGRPH_2";
BA_ "LongName" SG_ 1085 IDX_PRES_SEG_NAVGRPH_2 "Index_Aktuelle_Segment_Nav-Graph_2";
BA_ "SysSignalName" SG_ 1085 IDX_PRES_SEG_NAVGRPH_2 "IDX_PRES_SEG_NAVGRPH_2";
BA_ "CompuMethodName" SG_ 1085 DIR_CHNG_ANG_SEG_NAVGRPH_2 "DIR_CHNG_ANG_SEG_NAVGRPH_2";
BA_ "GenSigStartValue" SG_ 1085 DIR_CHNG_ANG_SEG_NAVGRPH_2 -180;
BA_ "ISignalName" SG_ 1085 DIR_CHNG_ANG_SEG_NAVGRPH_2 "DIR_CHNG_ANG_SEG_NAVGRPH_2";
BA_ "LongName" SG_ 1085 DIR_CHNG_ANG_SEG_NAVGRPH_2 "Richtung_Änderung_Winkel_Segment_Nav-Graph_2";
BA_ "SysSignalName" SG_ 1085 DIR_CHNG_ANG_SEG_NAVGRPH_2 "DIR_CHNG_ANG_SEG_NAVGRPH_2";
BA_ "CompuMethodName" SG_ 1085 RAD_PRES_SEG_NAVGRPH_2 "RAD_PRES_SEG_NAVGRPH_2";
BA_ "GenSigStartValue" SG_ 1085 RAD_PRES_SEG_NAVGRPH_2 2046;
BA_ "ISignalName" SG_ 1085 RAD_PRES_SEG_NAVGRPH_2 "RAD_PRES_SEG_NAVGRPH_2";
BA_ "LongName" SG_ 1085 RAD_PRES_SEG_NAVGRPH_2 "Radius_Aktuelle_Segment_Nav-Graph_2";
BA_ "SysSignalName" SG_ 1085 RAD_PRES_SEG_NAVGRPH_2 "RAD_PRES_SEG_NAVGRPH_2";
BA_ "CompuMethodName" SG_ 1085 QUAN_LNS_NAVGRPH_2 "QUAN_LNS_NAVGRPH_2";
BA_ "ISignalName" SG_ 1085 QUAN_LNS_NAVGRPH_2 "QUAN_LNS_NAVGRPH_2";
BA_ "LongName" SG_ 1085 QUAN_LNS_NAVGRPH_2 "Anzahl_Fahrspuren_Nav-Graph_2";
BA_ "SysSignalName" SG_ 1085 QUAN_LNS_NAVGRPH_2 "QUAN_LNS_NAVGRPH_2";
BA_ "CompuMethodName" SG_ 1085 TYP_STREET_NAVGRPH_2 "TYP_STREET_NAVGRPH_2";
BA_ "ISignalName" SG_ 1085 TYP_STREET_NAVGRPH_2 "TYP_STREET_NAVGRPH_2";
BA_ "LongName" SG_ 1085 TYP_STREET_NAVGRPH_2 "Typ_Straße_Nav-Graph_2";
BA_ "SysSignalName" SG_ 1085 TYP_STREET_NAVGRPH_2 "TYP_STREET_NAVGRPH_2";
BA_ "CompuMethodName" SG_ 1085 L_SEG_NAVGRPH_2 "L_SEG_NAVGRPH_2";
BA_ "ISignalName" SG_ 1085 L_SEG_NAVGRPH_2 "L_SEG_NAVGRPH_2";
BA_ "LongName" SG_ 1085 L_SEG_NAVGRPH_2 "Länge_Segment_Nav-Graph_2";
BA_ "SysSignalName" SG_ 1085 L_SEG_NAVGRPH_2 "L_SEG_NAVGRPH_2";
BA_ "CompuMethodName" SG_ 1085 PROP_MAP_NAVGRPH_2 "PROP_MAP_NAVGRPH_2";
BA_ "ISignalName" SG_ 1085 PROP_MAP_NAVGRPH_2 "PROP_MAP_NAVGRPH_2";
BA_ "LongName" SG_ 1085 PROP_MAP_NAVGRPH_2 "Eigenschaft_Karte_Nav-Graph_2";
BA_ "SysSignalName" SG_ 1085 PROP_MAP_NAVGRPH_2 "PROP_MAP_NAVGRPH_2";
BA_ "CompuMethodName" SG_ 1085 LIM_V_NAVGRPH_2 "LIM_V_NAVGRPH_2";
BA_ "ISignalName" SG_ 1085 LIM_V_NAVGRPH_2 "LIM_V_NAVGRPH_2";
BA_ "LongName" SG_ 1085 LIM_V_NAVGRPH_2 "Begrenzung_Geschwindigkeit_Nav-Graph_2";
BA_ "SysSignalName" SG_ 1085 LIM_V_NAVGRPH_2 "LIM_V_NAVGRPH_2";
BA_ "CompuMethodName" SG_ 842 ST_LONG_NAVI "ST_LONG_NAVI";
BA_ "ISignalName" SG_ 842 ST_LONG_NAVI "ST_LONG_NAVI";
BA_ "LongName" SG_ 842 ST_LONG_NAVI "Status_Longitude_Navigation";
BA_ "SysSignalName" SG_ 842 ST_LONG_NAVI "ST_LONG_NAVI";
BA_ "CompuMethodName" SG_ 842 ST_LAT_NAVI "ST_LAT_NAVI";
BA_ "ISignalName" SG_ 842 ST_LAT_NAVI "ST_LAT_NAVI";
BA_ "LongName" SG_ 842 ST_LAT_NAVI "Status_Latitude_Navigation";
BA_ "SysSignalName" SG_ 842 ST_LAT_NAVI "ST_LAT_NAVI";
BA_ "CompuMethodName" SG_ 844 ST_HG_NAVI "ST_HG_NAVI";
BA_ "ISignalName" SG_ 844 ST_HG_NAVI "ST_HG_NAVI";
BA_ "LongName" SG_ 844 ST_HG_NAVI "Status_Höhe_Navigation";
BA_ "SysSignalName" SG_ 844 ST_HG_NAVI "ST_HG_NAVI";
BA_ "CompuMethodName" SG_ 844 ST_V_HRZTL "ST_V_HRZTL";
BA_ "ISignalName" SG_ 844 ST_V_HRZTL "ST_V_HRZTL";
BA_ "LongName" SG_ 844 ST_V_HRZTL "Status_Geschwindigkeit_Horizontal";
BA_ "SysSignalName" SG_ 844 ST_V_HRZTL "ST_V_HRZTL";
BA_ "CompuMethodName" SG_ 844 ST_HDG_HRZTL_ABSL "ST_HDG_HRZTL_ABSL";
BA_ "ISignalName" SG_ 844 ST_HDG_HRZTL_ABSL "ST_HDG_HRZTL_ABSL";
BA_ "LongName" SG_ 844 ST_HDG_HRZTL_ABSL "Status_Kurs_Horizontal_Absolut";
BA_ "SysSignalName" SG_ 844 ST_HDG_HRZTL_ABSL "ST_HDG_HRZTL_ABSL";
BA_ "CompuMethodName" SG_ 844 ST_QUAL_PO "ST_QUAL_PO";
BA_ "ISignalName" SG_ 844 ST_QUAL_PO "ST_QUAL_PO";
BA_ "LongName" SG_ 844 ST_QUAL_PO "Status_Qualität_Position";
BA_ "SysSignalName" SG_ 844 ST_QUAL_PO "ST_QUAL_PO";
BA_ "CompuMethodName" SG_ 632 IDX_SEG_NAVGRPH "IDX_SEG_NAVGRPH";
BA_ "ISignalName" SG_ 632 IDX_SEG_NAVGRPH "IDX_SEG_NAVGRPH";
BA_ "LongName" SG_ 632 IDX_SEG_NAVGRPH "Index_Segment_Nav-Graph";
BA_ "SysSignalName" SG_ 632 IDX_SEG_NAVGRPH "IDX_SEG_NAVGRPH";
BA_ "CompuMethodName" SG_ 632 IDX_FSEG_NAVGRPH "IDX_SEG_NAVGRPH";
BA_ "ISignalName" SG_ 632 IDX_FSEG_NAVGRPH "IDX_FSEG_NAVGRPH";
BA_ "LongName" SG_ 632 IDX_FSEG_NAVGRPH "Index_Vater-Segment_Nav-Graph";
BA_ "SysSignalName" SG_ 632 IDX_FSEG_NAVGRPH "IDX_FSEG_NAVGRPH";
BA_ "CompuMethodName" SG_ 632 GRAD_NAVGRPH "GRAD_NAVGRPH";
BA_ "ISignalName" SG_ 632 GRAD_NAVGRPH "GRAD_NAVGRPH";
BA_ "LongName" SG_ 632 GRAD_NAVGRPH "Gradient_Nav-Graph";
BA_ "SysSignalName" SG_ 632 GRAD_NAVGRPH "GRAD_NAVGRPH";
BA_ "CompuMethodName" SG_ 632 RAD_SEG_NAVGRPH "RAD_SEG_NAVGRPH";
BA_ "ISignalName" SG_ 632 RAD_SEG_NAVGRPH "RAD_SEG_NAVGRPH";
BA_ "LongName" SG_ 632 RAD_SEG_NAVGRPH "Radius_Segment_Nav-Graph";
BA_ "SysSignalName" SG_ 632 RAD_SEG_NAVGRPH "RAD_SEG_NAVGRPH";
BA_ "CompuMethodName" SG_ 632 L_SEG_NAVGRPH "L_SEG_NAVGRPH";
BA_ "ISignalName" SG_ 632 L_SEG_NAVGRPH "L_SEG_NAVGRPH";
BA_ "LongName" SG_ 632 L_SEG_NAVGRPH "Länge_Segment_Nav-Graph";
BA_ "SysSignalName" SG_ 632 L_SEG_NAVGRPH "L_SEG_NAVGRPH";
BA_ "CompuMethodName" SG_ 632 TYP_STREET_NAVGRPH "TYP_STREET_NAVGRPH";
BA_ "ISignalName" SG_ 632 TYP_STREET_NAVGRPH "TYP_STREET_NAVGRPH";
BA_ "LongName" SG_ 632 TYP_STREET_NAVGRPH "Typ_Straße_Nav-Graph";
BA_ "SysSignalName" SG_ 632 TYP_STREET_NAVGRPH "TYP_STREET_NAVGRPH";
BA_ "CompuMethodName" SG_ 632 AUXINF_SEG_NAVGRPH "AUINF_SEG_NAVGRPH";
BA_ "ISignalName" SG_ 632 AUXINF_SEG_NAVGRPH "AUXINF_SEG_NAVGRPH";
BA_ "LongName" SG_ 632 AUXINF_SEG_NAVGRPH "Zusatzinformation_Segment_Nav-Graph";
BA_ "SysSignalName" SG_ 632 AUXINF_SEG_NAVGRPH "AUXINF_SEG_NAVGRPH";
BA_ "CompuMethodName" SG_ 840 ST_MTCH_PO_REL "ST_MTCH_PO_REL";
BA_ "ISignalName" SG_ 840 ST_MTCH_PO_REL "ST_MTCH_PO_REL";
BA_ "LongName" SG_ 840 ST_MTCH_PO_REL "Status_Übereinstimmung_Position_Relativ";
BA_ "SysSignalName" SG_ 840 ST_MTCH_PO_REL "ST_MTCH_PO_REL";
BA_ "CompuMethodName" SG_ 840 ST_MTCH_IDX_SEG "IDX_SEG_NAVGRPH";
BA_ "ISignalName" SG_ 840 ST_MTCH_IDX_SEG "ST_MTCH_IDX_SEG";
BA_ "LongName" SG_ 840 ST_MTCH_IDX_SEG "Status_Übereinstimmung_Index_Segment";
BA_ "SysSignalName" SG_ 840 ST_MTCH_IDX_SEG "ST_MTCH_IDX_SEG";
BA_ "CompuMethodName" SG_ 840 ST_MTCH_UNIQ_PO "ST_MTCH_UNIQ_PO";
BA_ "ISignalName" SG_ 840 ST_MTCH_UNIQ_PO "ST_MTCH_UNIQ_PO";
BA_ "LongName" SG_ 840 ST_MTCH_UNIQ_PO "Status_Übereinstimmung_Eindeutigkeit_Position";
BA_ "SysSignalName" SG_ 840 ST_MTCH_UNIQ_PO "ST_MTCH_UNIQ_PO";
BA_ "CompuMethodName" SG_ 840 PRES_LNE "PRES_LNE";
BA_ "ISignalName" SG_ 840 PRES_LNE "PRES_LNE";
BA_ "LongName" SG_ 840 PRES_LNE "Aktuelle_Fahrspur";
BA_ "SysSignalName" SG_ 840 PRES_LNE "PRES_LNE";
BA_ "CompuMethodName" SG_ 840 ST_MTCH_TSTMP "ST_MTCH_TSTMP";
BA_ "ISignalName" SG_ 840 ST_MTCH_TSTMP "ST_MTCH_TSTMP";
BA_ "LongName" SG_ 840 ST_MTCH_TSTMP "Status_Übereinstimmung_Zeitstempel";
BA_ "SysSignalName" SG_ 840 ST_MTCH_TSTMP "ST_MTCH_TSTMP";
BA_ "CompuMethodName" SG_ 840 ST_MTCH_QUAL "ST_MTCH_QUAL";
BA_ "ISignalName" SG_ 840 ST_MTCH_QUAL "ST_MTCH_QUAL";
BA_ "LongName" SG_ 840 ST_MTCH_QUAL "Status_Übereinstimmung_Qualität";
BA_ "SysSignalName" SG_ 840 ST_MTCH_QUAL "ST_MTCH_QUAL";
BA_ "CompuMethodName" SG_ 634 ST_QUAN_PCKGS "ST_QUAN_PCKGS";
BA_ "ISignalName" SG_ 634 ST_QUAN_PCKGS "ST_QUAN_PCKGS";
BA_ "LongName" SG_ 634 ST_QUAN_PCKGS "Status_Anzahl_Pakete";
BA_ "SysSignalName" SG_ 634 ST_QUAN_PCKGS "ST_QUAN_PCKGS";
BA_ "CompuMethodName" SG_ 634 COU_NAVGRPH_SYNC "COU_NAVGRPH_SYNC";
BA_ "ISignalName" SG_ 634 COU_NAVGRPH_SYNC "COU_NAVGRPH_SYNC";
BA_ "LongName" SG_ 634 COU_NAVGRPH_SYNC "Zähler_Nav-Graph_Sync";
BA_ "SysSignalName" SG_ 634 COU_NAVGRPH_SYNC "COU_NAVGRPH_SYNC";
BA_ "CompuMethodName" SG_ 634 CRC16_NAVGRPH_SYNC "UI_16_noIniVal_noDflVal_noErrVal_1_0_noEnc_hasRng_1";
BA_ "ISignalName" SG_ 634 CRC16_NAVGRPH_SYNC "CRC16_NAVGRPH_SYNC";
BA_ "LongName" SG_ 634 CRC16_NAVGRPH_SYNC "CRC16_Nav-Graph_Sync";
BA_ "SysSignalName" SG_ 634 CRC16_NAVGRPH_SYNC "CRC16_NAVGRPH_SYNC";
BA_ "CompuMethodName" SG_ 634 MOD_TRNSM_NAVGRPH_SYNC "MOD_TRNSM_NAVGRPH_SYNC";
BA_ "ISignalName" SG_ 634 MOD_TRNSM_NAVGRPH_SYNC "MOD_TRNSM_NAVGRPH_SYNC";
BA_ "LongName" SG_ 634 MOD_TRNSM_NAVGRPH_SYNC "Modus_Übertragung_Nav-Graph_Sync";
BA_ "SysSignalName" SG_ 634 MOD_TRNSM_NAVGRPH_SYNC "MOD_TRNSM_NAVGRPH_SYNC";
BA_ "CompuMethodName" SG_ 634 IDX_SEG_DEL_NAVGRPH "IDX_SEG_DEL_NAVGRPH";
BA_ "ISignalName" SG_ 634 IDX_SEG_DEL_NAVGRPH "IDX_SEG_DEL_NAVGRPH";
BA_ "LongName" SG_ 634 IDX_SEG_DEL_NAVGRPH "Index_Segment_Löschen_Nav-Graph";
BA_ "SysSignalName" SG_ 634 IDX_SEG_DEL_NAVGRPH "IDX_SEG_DEL_NAVGRPH";
BA_ "CompuMethodName" SG_ 634 CTR_DEL_NAVGRPH "CTR_DEL_NAVGRPH";
BA_ "ISignalName" SG_ 634 CTR_DEL_NAVGRPH "CTR_DEL_NAVGRPH";
BA_ "LongName" SG_ 634 CTR_DEL_NAVGRPH "Steuerung_Löschen_Nav-Graph";
BA_ "SysSignalName" SG_ 634 CTR_DEL_NAVGRPH "CTR_DEL_NAVGRPH";
BA_ "CompuMethodName" SG_ 634 AUINF_NAVGRPH_SYNC "AUINF_NAVGRPH_SYNC";
BA_ "ISignalName" SG_ 634 AUINF_NAVGRPH_SYNC "AUINF_NAVGRPH_SYNC";
BA_ "LongName" SG_ 634 AUINF_NAVGRPH_SYNC "Zusatzinformation_Nav-Graph_Sync";
BA_ "SysSignalName" SG_ 634 AUINF_NAVGRPH_SYNC "AUINF_NAVGRPH_SYNC";
BA_ "CompuMethodName" SG_ 846 ST_OPET_NAVI "ST_OPET_NAVI";
BA_ "ISignalName" SG_ 846 ST_OPET_NAVI "ST_OPET_NAVI";
BA_ "LongName" SG_ 846 ST_OPET_NAVI "Status_Betriebszeit_Navigation";
BA_ "SysSignalName" SG_ 846 ST_OPET_NAVI "ST_OPET_NAVI";
BA_ "CompuMethodName" SG_ 846 ST_VRS_PRTL_NAVI "ST_VRS_PRTL_NAVI";
BA_ "ISignalName" SG_ 846 ST_VRS_PRTL_NAVI "ST_VRS_PRTL_NAVI";
BA_ "LongName" SG_ 846 ST_VRS_PRTL_NAVI "Status_Version_Protokoll_Navigation";
BA_ "SysSignalName" SG_ 846 ST_VRS_PRTL_NAVI "ST_VRS_PRTL_NAVI";
BA_ "CompuMethodName" SG_ 846 ST_VRS_HW_NAVI "ST_VRS_HW_NAVI";
BA_ "ISignalName" SG_ 846 ST_VRS_HW_NAVI "ST_VRS_HW_NAVI";
BA_ "LongName" SG_ 846 ST_VRS_HW_NAVI "Status_Version_Hardware_Navigation";
BA_ "SysSignalName" SG_ 846 ST_VRS_HW_NAVI "ST_VRS_HW_NAVI";
BA_ "CompuMethodName" SG_ 846 ST_VRS_HW_NAVI_MANU "ST_VRS_HW_NAVI_MANU";
BA_ "ISignalName" SG_ 846 ST_VRS_HW_NAVI_MANU "ST_VRS_HW_NAVI_MANU";
BA_ "LongName" SG_ 846 ST_VRS_HW_NAVI_MANU "Status_Version_Hardware_Navigation_Hersteller";
BA_ "SysSignalName" SG_ 846 ST_VRS_HW_NAVI_MANU "ST_VRS_HW_NAVI_MANU";
BA_ "CompuMethodName" SG_ 846 ST_VRS_MAP_NAVI "ST_VRS_MAP_NAVI";
BA_ "ISignalName" SG_ 846 ST_VRS_MAP_NAVI "ST_VRS_MAP_NAVI";
BA_ "LongName" SG_ 846 ST_VRS_MAP_NAVI "Status_Version_Karte_Navigation";
BA_ "SysSignalName" SG_ 846 ST_VRS_MAP_NAVI "ST_VRS_MAP_NAVI";
BA_ "CompuMethodName" SG_ 846 ST_VRS_MAP_NAVI_MANU "ST_VRS_MAP_NAVI_MANU";
BA_ "ISignalName" SG_ 846 ST_VRS_MAP_NAVI_MANU "ST_VRS_MAP_NAVI_MANU";
BA_ "LongName" SG_ 846 ST_VRS_MAP_NAVI_MANU "Status_Version_Karte_Navigation_Hersteller";
BA_ "SysSignalName" SG_ 846 ST_VRS_MAP_NAVI_MANU "ST_VRS_MAP_NAVI_MANU";
BA_ "CompuMethodName" SG_ 846 ST_CNCD_NAVI "ST_CNCD_NAVI";
BA_ "ISignalName" SG_ 846 ST_CNCD_NAVI "ST_CNCD_NAVI";
BA_ "LongName" SG_ 846 ST_CNCD_NAVI "Status_Ländercodierung_Navigation";
BA_ "SysSignalName" SG_ 846 ST_CNCD_NAVI "ST_CNCD_NAVI";
BA_ "CompuMethodName" SG_ 555 PRMSN_DBC_TR_NIVI_THRV "PRMSN_DBC_TR_NIVI_THRV";
BA_ "ISignalName" SG_ 555 PRMSN_DBC_TR_NIVI_THRV "PRMSN_DBC_TR_NIVI_THRV";
BA_ "LongName" SG_ 555 PRMSN_DBC_TR_NIVI_THRV "Parametrisierung_DBC_Trigger_Night-Vision_Schwellwert";
BA_ "SysSignalName" SG_ 555 PRMSN_DBC_TR_NIVI_THRV "PRMSN_DBC_TR_NIVI_THRV";
BA_ "CompuMethodName" SG_ 555 PRF_NIVI_BRK "PRF_NIVI_BRK";
BA_ "ISignalName" SG_ 555 PRF_NIVI_BRK "PRF_NIVI_BRK";
BA_ "LongName" SG_ 555 PRF_NIVI_BRK "Vorbefüllung_Night-Vision_Bremse";
BA_ "SysSignalName" SG_ 555 PRF_NIVI_BRK "PRF_NIVI_BRK";
BA_ "CompuMethodName" SG_ 555 ST_OBJ_SMPL_TYP_NIVI_2 "ST_OBJ_TYP_NIVI";
BA_ "ISignalName" SG_ 555 ST_OBJ_SMPL_TYP_NIVI_2 "ST_OBJ_SMPL_TYP_NIVI_2";
BA_ "LongName" SG_ 555 ST_OBJ_SMPL_TYP_NIVI_2 "Status_Objekt_Einfach_Typ_Night-Vision_2";
BA_ "SysSignalName" SG_ 555 ST_OBJ_SMPL_TYP_NIVI_2 "ST_OBJ_SMPL_TYP_NIVI_2";
BA_ "CompuMethodName" SG_ 555 ST_OBJ_SMPL_PROP_NIVI_2 "ST_OBJ_PROP_NIVI";
BA_ "ISignalName" SG_ 555 ST_OBJ_SMPL_PROP_NIVI_2 "ST_OBJ_SMPL_PROP_NIVI_2";
BA_ "LongName" SG_ 555 ST_OBJ_SMPL_PROP_NIVI_2 "Status_Objekt_Einfach_Eigenschaft_Night-Vision_2";
BA_ "SysSignalName" SG_ 555 ST_OBJ_SMPL_PROP_NIVI_2 "ST_OBJ_SMPL_PROP_NIVI_2";
BA_ "CompuMethodName" SG_ 555 ST_OBJ_FAR_MID_TYP_NIVI_2 "ST_OBJ_TYP_NIVI";
BA_ "ISignalName" SG_ 555 ST_OBJ_FAR_MID_TYP_NIVI_2 "ST_OBJ_FAR_MID_TYP_NIVI_2";
BA_ "LongName" SG_ 555 ST_OBJ_FAR_MID_TYP_NIVI_2 "Status_Objekt_Fernbereich_Mitte_Typ_Night-Vision_2";
BA_ "SysSignalName" SG_ 555 ST_OBJ_FAR_MID_TYP_NIVI_2 "ST_OBJ_FAR_MID_TYP_NIVI_2";
BA_ "CompuMethodName" SG_ 555 ST_OBJ_FAR_MID_PROP_NIVI_2 "ST_OBJ_PROP_NIVI";
BA_ "ISignalName" SG_ 555 ST_OBJ_FAR_MID_PROP_NIVI_2 "ST_OBJ_FAR_MID_PROP_NIVI_2";
BA_ "LongName" SG_ 555 ST_OBJ_FAR_MID_PROP_NIVI_2 "Status_Objekt_Fernbereich_Mitte_Eigenschaft_Night-Vision_2";
BA_ "SysSignalName" SG_ 555 ST_OBJ_FAR_MID_PROP_NIVI_2 "ST_OBJ_FAR_MID_PROP_NIVI_2";
BA_ "CompuMethodName" SG_ 555 ST_OBJ_NR_MID_TYP_NIVI_2 "ST_OBJ_TYP_NIVI";
BA_ "ISignalName" SG_ 555 ST_OBJ_NR_MID_TYP_NIVI_2 "ST_OBJ_NR_MID_TYP_NIVI_2";
BA_ "LongName" SG_ 555 ST_OBJ_NR_MID_TYP_NIVI_2 "Status_Objekt_Nahbereich_Mitte_Typ_Night-Vision_2";
BA_ "SysSignalName" SG_ 555 ST_OBJ_NR_MID_TYP_NIVI_2 "ST_OBJ_NR_MID_TYP_NIVI_2";
BA_ "CompuMethodName" SG_ 555 ST_OBJ_NR_MID_PROP_NIVI_2 "ST_OBJ_PROP_NIVI";
BA_ "ISignalName" SG_ 555 ST_OBJ_NR_MID_PROP_NIVI_2 "ST_OBJ_NR_MID_PROP_NIVI_2";
BA_ "LongName" SG_ 555 ST_OBJ_NR_MID_PROP_NIVI_2 "Status_Objekt_Nahbereich_Mitte_Eigenschaft_Night-Vision_2";
BA_ "SysSignalName" SG_ 555 ST_OBJ_NR_MID_PROP_NIVI_2 "ST_OBJ_NR_MID_PROP_NIVI_2";
BA_ "CompuMethodName" SG_ 555 ST_OBJ_ACRO_LH_TYP_NIVI_2 "ST_OBJ_TYP_NIVI";
BA_ "ISignalName" SG_ 555 ST_OBJ_ACRO_LH_TYP_NIVI_2 "ST_OBJ_ACRO_LH_TYP_NIVI_2";
BA_ "LongName" SG_ 555 ST_OBJ_ACRO_LH_TYP_NIVI_2 "Status_Objekt_Quer_Links_Typ_Night-Vision_2";
BA_ "SysSignalName" SG_ 555 ST_OBJ_ACRO_LH_TYP_NIVI_2 "ST_OBJ_ACRO_LH_TYP_NIVI_2";
BA_ "CompuMethodName" SG_ 555 ST_OBJ_ACRO_LH_PROP_NIVI_2 "ST_OBJ_PROP_NIVI";
BA_ "ISignalName" SG_ 555 ST_OBJ_ACRO_LH_PROP_NIVI_2 "ST_OBJ_ACRO_LH_PROP_NIVI_2";
BA_ "LongName" SG_ 555 ST_OBJ_ACRO_LH_PROP_NIVI_2 "Status_Objekt_Quer_Links_Eigenschaft_Night-Vision_2";
BA_ "SysSignalName" SG_ 555 ST_OBJ_ACRO_LH_PROP_NIVI_2 "ST_OBJ_ACRO_LH_PROP_NIVI_2";
BA_ "CompuMethodName" SG_ 555 ST_OBJ_ACRO_RH_TYP_NIVI_2 "ST_OBJ_TYP_NIVI";
BA_ "ISignalName" SG_ 555 ST_OBJ_ACRO_RH_TYP_NIVI_2 "ST_OBJ_ACRO_RH_TYP_NIVI_2";
BA_ "LongName" SG_ 555 ST_OBJ_ACRO_RH_TYP_NIVI_2 "Status_Objekt_Quer_Rechts_Typ_Night-Vision_2";
BA_ "SysSignalName" SG_ 555 ST_OBJ_ACRO_RH_TYP_NIVI_2 "ST_OBJ_ACRO_RH_TYP_NIVI_2";
BA_ "CompuMethodName" SG_ 555 ST_OBJ_ACRO_RH_PROP_NIVI_2 "ST_OBJ_PROP_NIVI";
BA_ "ISignalName" SG_ 555 ST_OBJ_ACRO_RH_PROP_NIVI_2 "ST_OBJ_ACRO_RH_PROP_NIVI_2";
BA_ "LongName" SG_ 555 ST_OBJ_ACRO_RH_PROP_NIVI_2 "Status_Objekt_Quer_Rechts_Eigenschaft_Night-Vision_2";
BA_ "SysSignalName" SG_ 555 ST_OBJ_ACRO_RH_PROP_NIVI_2 "ST_OBJ_ACRO_RH_PROP_NIVI_2";
BA_ "CompuMethodName" SG_ 555 ST_AWARN_NIVI "ST_AWARN_NIVI";
BA_ "ISignalName" SG_ 555 ST_AWARN_NIVI "ST_AWARN_NIVI";
BA_ "LongName" SG_ 555 ST_AWARN_NIVI "Status_Akutwarnung_Night-Vision";
BA_ "SysSignalName" SG_ 555 ST_AWARN_NIVI "ST_AWARN_NIVI";
BA_ "CompuMethodName" SG_ 555 ST_FLS_SYM_NIVI "ST_FLS_SYM_NIVI";
BA_ "ISignalName" SG_ 555 ST_FLS_SYM_NIVI "ST_FLS_SYM_NIVI";
BA_ "LongName" SG_ 555 ST_FLS_SYM_NIVI "Status_blinkend_Symbol_Night-Vision";
BA_ "SysSignalName" SG_ 555 ST_FLS_SYM_NIVI "ST_FLS_SYM_NIVI";
BA_ "CompuMethodName" SG_ 462 BNDRY_2_DOM_BOT_NGL_FLA "BNDRY_2_DOM_BOT_NGL_FLA";
BA_ "GenSigStartValue" SG_ 462 BNDRY_2_DOM_BOT_NGL_FLA -5;
BA_ "ISignalName" SG_ 462 BNDRY_2_DOM_BOT_NGL_FLA "BNDRY_2_DOM_BOT_NGL_FLA";
BA_ "LongName" SG_ 462 BNDRY_2_DOM_BOT_NGL_FLA "Grenze_2_Bereich_Unten_Blendfrei_FLA";
BA_ "SysSignalName" SG_ 462 BNDRY_2_DOM_BOT_NGL_FLA "BNDRY_2_DOM_BOT_NGL_FLA";
BA_ "CompuMethodName" SG_ 462 BNDRY_2_DOM_NGL_LH_FLA "BNDRY_DOM_NGL_LH_FLA";
BA_ "GenSigStartValue" SG_ 462 BNDRY_2_DOM_NGL_LH_FLA -10;
BA_ "ISignalName" SG_ 462 BNDRY_2_DOM_NGL_LH_FLA "BNDRY_2_DOM_NGL_LH_FLA";
BA_ "LongName" SG_ 462 BNDRY_2_DOM_NGL_LH_FLA "Grenze_2_Bereich_Blendfrei_Links_FLA";
BA_ "SysSignalName" SG_ 462 BNDRY_2_DOM_NGL_LH_FLA "BNDRY_2_DOM_NGL_LH_FLA";
BA_ "CompuMethodName" SG_ 462 BNDRY_2_DOM_NGL_RH_FLA "BNDRY_DOM_NGL_RH_FLA";
BA_ "GenSigStartValue" SG_ 462 BNDRY_2_DOM_NGL_RH_FLA -15;
BA_ "ISignalName" SG_ 462 BNDRY_2_DOM_NGL_RH_FLA "BNDRY_2_DOM_NGL_RH_FLA";
BA_ "LongName" SG_ 462 BNDRY_2_DOM_NGL_RH_FLA "Grenze_2_Bereich_Blendfrei_Rechts_FLA";
BA_ "SysSignalName" SG_ 462 BNDRY_2_DOM_NGL_RH_FLA "BNDRY_2_DOM_NGL_RH_FLA";
BA_ "CompuMethodName" SG_ 462 OBJ_2_DIST_FLA "OBJ_2_DIST_FLA";
BA_ "ISignalName" SG_ 462 OBJ_2_DIST_FLA "OBJ_2_DIST_FLA";
BA_ "LongName" SG_ 462 OBJ_2_DIST_FLA "Objekt_2_Distanz_FLA";
BA_ "SysSignalName" SG_ 462 OBJ_2_DIST_FLA "OBJ_2_DIST_FLA";
BA_ "CompuMethodName" SG_ 462 ST_BNDRY_2_DOM_BOT_NGL_FLA "ST_BNDRY_DOM_BOT_NGL_FLA";
BA_ "ISignalName" SG_ 462 ST_BNDRY_2_DOM_BOT_NGL_FLA "ST_BNDRY_2_DOM_BOT_NGL_FLA";
BA_ "LongName" SG_ 462 ST_BNDRY_2_DOM_BOT_NGL_FLA "Status_Grenze_2_Bereich_Unten_Blendfrei_FLA";
BA_ "SysSignalName" SG_ 462 ST_BNDRY_2_DOM_BOT_NGL_FLA "ST_BNDRY_2_DOM_BOT_NGL_FLA";
BA_ "CompuMethodName" SG_ 462 ST_BNDRY_2_DOM_NGL_LH_FLA "ST_BNDRY_DOM_NGL_LH_FLA";
BA_ "ISignalName" SG_ 462 ST_BNDRY_2_DOM_NGL_LH_FLA "ST_BNDRY_2_DOM_NGL_LH_FLA";
BA_ "LongName" SG_ 462 ST_BNDRY_2_DOM_NGL_LH_FLA "Status_Grenze_2_Bereich_Blendfrei_Links_FLA";
BA_ "SysSignalName" SG_ 462 ST_BNDRY_2_DOM_NGL_LH_FLA "ST_BNDRY_2_DOM_NGL_LH_FLA";
BA_ "CompuMethodName" SG_ 462 ST_BNDRY_2_DOM_NGL_RH_FLA "ST_BNDRY_DOM_NGL_RH_FLA";
BA_ "ISignalName" SG_ 462 ST_BNDRY_2_DOM_NGL_RH_FLA "ST_BNDRY_2_DOM_NGL_RH_FLA";
BA_ "LongName" SG_ 462 ST_BNDRY_2_DOM_NGL_RH_FLA "Status_Grenze_2_Bereich_Blendfrei_Rechts_FLA";
BA_ "SysSignalName" SG_ 462 ST_BNDRY_2_DOM_NGL_RH_FLA "ST_BNDRY_2_DOM_NGL_RH_FLA";
BA_ "CompuMethodName" SG_ 462 ST_OBJ_2_DIST_FLA "ST_OBJ_DIST_FLA";
BA_ "ISignalName" SG_ 462 ST_OBJ_2_DIST_FLA "ST_OBJ_2_DIST_FLA";
BA_ "LongName" SG_ 462 ST_OBJ_2_DIST_FLA "Status_Objekt_2_Distanz_FLA";
BA_ "SysSignalName" SG_ 462 ST_OBJ_2_DIST_FLA "ST_OBJ_2_DIST_FLA";
BA_ "CompuMethodName" SG_ 462 PRO_SBS_2_FLA "PRO_SBS_FLA";
BA_ "ISignalName" SG_ 462 PRO_SBS_2_FLA "PRO_SBS_2_FLA";
BA_ "LongName" SG_ 462 PRO_SBS_2_FLA "Wahrscheinlichkeit_Existenz_2_FLA";
BA_ "SysSignalName" SG_ 462 PRO_SBS_2_FLA "PRO_SBS_2_FLA";
BA_ "CompuMethodName" SG_ 462 DIST_BNDRY_2_DOM_NGL_LH_FLA "DIST_BNDRY_DOM_NGL_FLA";
BA_ "ISignalName" SG_ 462 DIST_BNDRY_2_DOM_NGL_LH_FLA "DIST_BNDRY_2_DOM_NGL_LH_FLA";
BA_ "LongName" SG_ 462 DIST_BNDRY_2_DOM_NGL_LH_FLA "Distanz_Grenze_2_Bereich_Blendfrei_Links_FLA";
BA_ "SysSignalName" SG_ 462 DIST_BNDRY_2_DOM_NGL_LH_FLA "DIST_BNDRY_2_DOM_NGL_LH_FLA";
BA_ "CompuMethodName" SG_ 462 DIST_BNDRY_2_DOM_NGL_RH_FLA "DIST_BNDRY_DOM_NGL_FLA";
BA_ "ISignalName" SG_ 462 DIST_BNDRY_2_DOM_NGL_RH_FLA "DIST_BNDRY_2_DOM_NGL_RH_FLA";
BA_ "LongName" SG_ 462 DIST_BNDRY_2_DOM_NGL_RH_FLA "Distanz_Grenze_2_Bereich_Blendfrei_Rechts_FLA";
BA_ "SysSignalName" SG_ 462 DIST_BNDRY_2_DOM_NGL_RH_FLA "DIST_BNDRY_2_DOM_NGL_RH_FLA";
BA_ "CompuMethodName" SG_ 463 BNDRY_3_DOM_BOT_NGL_FLA "BNDRY_2_DOM_BOT_NGL_FLA";
BA_ "GenSigStartValue" SG_ 463 BNDRY_3_DOM_BOT_NGL_FLA -5;
BA_ "ISignalName" SG_ 463 BNDRY_3_DOM_BOT_NGL_FLA "BNDRY_3_DOM_BOT_NGL_FLA";
BA_ "LongName" SG_ 463 BNDRY_3_DOM_BOT_NGL_FLA "Grenze_3_Bereich_Unten_Blendfrei_FLA";
BA_ "SysSignalName" SG_ 463 BNDRY_3_DOM_BOT_NGL_FLA "BNDRY_3_DOM_BOT_NGL_FLA";
BA_ "CompuMethodName" SG_ 463 BNDRY_3_DOM_NGL_LH_FLA "BNDRY_DOM_NGL_LH_FLA";
BA_ "GenSigStartValue" SG_ 463 BNDRY_3_DOM_NGL_LH_FLA -10;
BA_ "ISignalName" SG_ 463 BNDRY_3_DOM_NGL_LH_FLA "BNDRY_3_DOM_NGL_LH_FLA";
BA_ "LongName" SG_ 463 BNDRY_3_DOM_NGL_LH_FLA "Grenze_3_Bereich_Blendfrei_Links_FLA";
BA_ "SysSignalName" SG_ 463 BNDRY_3_DOM_NGL_LH_FLA "BNDRY_3_DOM_NGL_LH_FLA";
BA_ "CompuMethodName" SG_ 463 BNDRY_3_DOM_NGL_RH_FLA "BNDRY_DOM_NGL_RH_FLA";
BA_ "GenSigStartValue" SG_ 463 BNDRY_3_DOM_NGL_RH_FLA -15;
BA_ "ISignalName" SG_ 463 BNDRY_3_DOM_NGL_RH_FLA "BNDRY_3_DOM_NGL_RH_FLA";
BA_ "LongName" SG_ 463 BNDRY_3_DOM_NGL_RH_FLA "Grenze_3_Bereich_Blendfrei_Rechts_FLA";
BA_ "SysSignalName" SG_ 463 BNDRY_3_DOM_NGL_RH_FLA "BNDRY_3_DOM_NGL_RH_FLA";
BA_ "CompuMethodName" SG_ 463 OBJ_3_DIST_FLA "OBJ_2_DIST_FLA";
BA_ "ISignalName" SG_ 463 OBJ_3_DIST_FLA "OBJ_3_DIST_FLA";
BA_ "LongName" SG_ 463 OBJ_3_DIST_FLA "Objekt_3_Distanz_FLA";
BA_ "SysSignalName" SG_ 463 OBJ_3_DIST_FLA "OBJ_3_DIST_FLA";
BA_ "CompuMethodName" SG_ 463 ST_BNDRY_3_DOM_BOT_NGL_FLA "ST_BNDRY_DOM_BOT_NGL_FLA";
BA_ "ISignalName" SG_ 463 ST_BNDRY_3_DOM_BOT_NGL_FLA "ST_BNDRY_3_DOM_BOT_NGL_FLA";
BA_ "LongName" SG_ 463 ST_BNDRY_3_DOM_BOT_NGL_FLA "Status_Grenze_3_Bereich_Unten_Blendfrei_FLA";
BA_ "SysSignalName" SG_ 463 ST_BNDRY_3_DOM_BOT_NGL_FLA "ST_BNDRY_3_DOM_BOT_NGL_FLA";
BA_ "CompuMethodName" SG_ 463 ST_BNDRY_3_DOM_NGL_LH_FLA "ST_BNDRY_DOM_NGL_LH_FLA";
BA_ "ISignalName" SG_ 463 ST_BNDRY_3_DOM_NGL_LH_FLA "ST_BNDRY_3_DOM_NGL_LH_FLA";
BA_ "LongName" SG_ 463 ST_BNDRY_3_DOM_NGL_LH_FLA "Status_Grenze_3_Bereich_Blendfrei_Links_FLA";
BA_ "SysSignalName" SG_ 463 ST_BNDRY_3_DOM_NGL_LH_FLA "ST_BNDRY_3_DOM_NGL_LH_FLA";
BA_ "CompuMethodName" SG_ 463 ST_BNDRY_3_DOM_NGL_RH_FLA "ST_BNDRY_DOM_NGL_RH_FLA";
BA_ "ISignalName" SG_ 463 ST_BNDRY_3_DOM_NGL_RH_FLA "ST_BNDRY_3_DOM_NGL_RH_FLA";
BA_ "LongName" SG_ 463 ST_BNDRY_3_DOM_NGL_RH_FLA "Status_Grenze_3_Bereich_Blendfrei_Rechts_FLA";
BA_ "SysSignalName" SG_ 463 ST_BNDRY_3_DOM_NGL_RH_FLA "ST_BNDRY_3_DOM_NGL_RH_FLA";
BA_ "CompuMethodName" SG_ 463 ST_OBJ_3_DIST_FLA "ST_OBJ_DIST_FLA";
BA_ "ISignalName" SG_ 463 ST_OBJ_3_DIST_FLA "ST_OBJ_3_DIST_FLA";
BA_ "LongName" SG_ 463 ST_OBJ_3_DIST_FLA "Status_Objekt_3_Distanz_FLA";
BA_ "SysSignalName" SG_ 463 ST_OBJ_3_DIST_FLA "ST_OBJ_3_DIST_FLA";
BA_ "CompuMethodName" SG_ 463 PRO_SBS_3_FLA "PRO_SBS_FLA";
BA_ "ISignalName" SG_ 463 PRO_SBS_3_FLA "PRO_SBS_3_FLA";
BA_ "LongName" SG_ 463 PRO_SBS_3_FLA "Wahrscheinlichkeit_Existenz_3_FLA";
BA_ "SysSignalName" SG_ 463 PRO_SBS_3_FLA "PRO_SBS_3_FLA";
BA_ "CompuMethodName" SG_ 463 DIST_BNDRY_3_DOM_NGL_LH_FLA "DIST_BNDRY_DOM_NGL_FLA";
BA_ "ISignalName" SG_ 463 DIST_BNDRY_3_DOM_NGL_LH_FLA "DIST_BNDRY_3_DOM_NGL_LH_FLA";
BA_ "LongName" SG_ 463 DIST_BNDRY_3_DOM_NGL_LH_FLA "Distanz_Grenze_3_Bereich_Blendfrei_Links_FLA";
BA_ "SysSignalName" SG_ 463 DIST_BNDRY_3_DOM_NGL_LH_FLA "DIST_BNDRY_3_DOM_NGL_LH_FLA";
BA_ "CompuMethodName" SG_ 463 DIST_BNDRY_3_DOM_NGL_RH_FLA "DIST_BNDRY_DOM_NGL_FLA";
BA_ "ISignalName" SG_ 463 DIST_BNDRY_3_DOM_NGL_RH_FLA "DIST_BNDRY_3_DOM_NGL_RH_FLA";
BA_ "LongName" SG_ 463 DIST_BNDRY_3_DOM_NGL_RH_FLA "distance_boundary_3_domain_non-glare_right-hand_FLA";
BA_ "SysSignalName" SG_ 463 DIST_BNDRY_3_DOM_NGL_RH_FLA "DIST_BNDRY_3_DOM_NGL_RH_FLA";
BA_ "CompuMethodName" SG_ 149 BNDRY_DOM_BOT_NGL_FLA "BNDRY_DOM_BOT_NGL_FLA";
BA_ "GenSigStartValue" SG_ 149 BNDRY_DOM_BOT_NGL_FLA -5;
BA_ "ISignalName" SG_ 149 BNDRY_DOM_BOT_NGL_FLA "BNDRY_DOM_BOT_NGL_FLA";
BA_ "LongName" SG_ 149 BNDRY_DOM_BOT_NGL_FLA "Grenze_Bereich_Unten_Blendfrei_FLA";
BA_ "SysSignalName" SG_ 149 BNDRY_DOM_BOT_NGL_FLA "BNDRY_DOM_BOT_NGL_FLA";
BA_ "CompuMethodName" SG_ 149 BNDRY_DOM_NGL_LH_FLA "BNDRY_DOM_NGL_LH_FLA";
BA_ "GenSigStartValue" SG_ 149 BNDRY_DOM_NGL_LH_FLA -10;
BA_ "ISignalName" SG_ 149 BNDRY_DOM_NGL_LH_FLA "BNDRY_DOM_NGL_LH_FLA";
BA_ "LongName" SG_ 149 BNDRY_DOM_NGL_LH_FLA "Grenze_Bereich_Blendfrei_Links_FLA";
BA_ "SysSignalName" SG_ 149 BNDRY_DOM_NGL_LH_FLA "BNDRY_DOM_NGL_LH_FLA";
BA_ "CompuMethodName" SG_ 149 BNDRY_DOM_NGL_RH_FLA "BNDRY_DOM_NGL_RH_FLA";
BA_ "GenSigStartValue" SG_ 149 BNDRY_DOM_NGL_RH_FLA -15;
BA_ "ISignalName" SG_ 149 BNDRY_DOM_NGL_RH_FLA "BNDRY_DOM_NGL_RH_FLA";
BA_ "LongName" SG_ 149 BNDRY_DOM_NGL_RH_FLA "Grenze_Bereich_Blendfrei_Rechts_FLA";
BA_ "SysSignalName" SG_ 149 BNDRY_DOM_NGL_RH_FLA "BNDRY_DOM_NGL_RH_FLA";
BA_ "CompuMethodName" SG_ 149 OBJ_DIST_FLA "OBJ_DIST_FLA";
BA_ "ISignalName" SG_ 149 OBJ_DIST_FLA "OBJ_DIST_FLA";
BA_ "LongName" SG_ 149 OBJ_DIST_FLA "Objekt_Distanz_FLA";
BA_ "SysSignalName" SG_ 149 OBJ_DIST_FLA "OBJ_DIST_FLA";
BA_ "CompuMethodName" SG_ 149 ST_BNDRY_DOM_BOT_NGL_FLA "ST_BNDRY_DOM_BOT_NGL_FLA";
BA_ "ISignalName" SG_ 149 ST_BNDRY_DOM_BOT_NGL_FLA "ST_BNDRY_DOM_BOT_NGL_FLA";
BA_ "LongName" SG_ 149 ST_BNDRY_DOM_BOT_NGL_FLA "Status_Grenze_Bereich_Unten_Blendfrei_FLA";
BA_ "SysSignalName" SG_ 149 ST_BNDRY_DOM_BOT_NGL_FLA "ST_BNDRY_DOM_BOT_NGL_FLA";
BA_ "CompuMethodName" SG_ 149 ST_BNDRY_DOM_NGL_LH_FLA "ST_BNDRY_DOM_NGL_LH_FLA";
BA_ "ISignalName" SG_ 149 ST_BNDRY_DOM_NGL_LH_FLA "ST_BNDRY_DOM_NGL_LH_FLA";
BA_ "LongName" SG_ 149 ST_BNDRY_DOM_NGL_LH_FLA "Status_Grenze_Bereich_Blendfrei_Links_FLA";
BA_ "SysSignalName" SG_ 149 ST_BNDRY_DOM_NGL_LH_FLA "ST_BNDRY_DOM_NGL_LH_FLA";
BA_ "CompuMethodName" SG_ 149 ST_BNDRY_DOM_NGL_RH_FLA "ST_BNDRY_DOM_NGL_RH_FLA";
BA_ "ISignalName" SG_ 149 ST_BNDRY_DOM_NGL_RH_FLA "ST_BNDRY_DOM_NGL_RH_FLA";
BA_ "LongName" SG_ 149 ST_BNDRY_DOM_NGL_RH_FLA "Status_Grenze_Bereich_Blendfrei_Rechts_FLA";
BA_ "SysSignalName" SG_ 149 ST_BNDRY_DOM_NGL_RH_FLA "ST_BNDRY_DOM_NGL_RH_FLA";
BA_ "CompuMethodName" SG_ 149 ST_OBJ_DIST_FLA "ST_OBJ_DIST_FLA";
BA_ "ISignalName" SG_ 149 ST_OBJ_DIST_FLA "ST_OBJ_DIST_FLA";
BA_ "LongName" SG_ 149 ST_OBJ_DIST_FLA "Status_Objekt_Distanz_FLA";
BA_ "SysSignalName" SG_ 149 ST_OBJ_DIST_FLA "ST_OBJ_DIST_FLA";
BA_ "CompuMethodName" SG_ 149 PRO_SBS_FLA "PRO_SBS_FLA";
BA_ "ISignalName" SG_ 149 PRO_SBS_FLA "PRO_SBS_FLA";
BA_ "LongName" SG_ 149 PRO_SBS_FLA "Wahrscheinlichkeit_Existenz_FLA";
BA_ "SysSignalName" SG_ 149 PRO_SBS_FLA "PRO_SBS_FLA";
BA_ "CompuMethodName" SG_ 149 DIST_BNDRY_DOM_NGL_LH_FLA "DIST_BNDRY_DOM_NGL_FLA";
BA_ "ISignalName" SG_ 149 DIST_BNDRY_DOM_NGL_LH_FLA "DIST_BNDRY_DOM_NGL_LH_FLA";
BA_ "LongName" SG_ 149 DIST_BNDRY_DOM_NGL_LH_FLA "Distanz_Grenze_Bereich_Blendfrei_Links_FLA";
BA_ "SysSignalName" SG_ 149 DIST_BNDRY_DOM_NGL_LH_FLA "DIST_BNDRY_DOM_NGL_LH_FLA";
BA_ "CompuMethodName" SG_ 149 DIST_BNDRY_DOM_NGL_RH_FLA "DIST_BNDRY_DOM_NGL_FLA";
BA_ "ISignalName" SG_ 149 DIST_BNDRY_DOM_NGL_RH_FLA "DIST_BNDRY_DOM_NGL_RH_FLA";
BA_ "LongName" SG_ 149 DIST_BNDRY_DOM_NGL_RH_FLA "distance_boundary_domain_non-glare_right-hand_FLA";
BA_ "SysSignalName" SG_ 149 DIST_BNDRY_DOM_NGL_RH_FLA "DIST_BNDRY_DOM_NGL_RH_FLA";
BA_ "CompuMethodName" SG_ 393 OP_CCTR_OPEL_3 "OP_CCTR_OPEL_3";
BA_ "ISignalName" SG_ 393 OP_CCTR_OPEL_3 "OP_CCTR_OPEL_3";
BA_ "LongName" SG_ 393 OP_CCTR_OPEL_3 "Bedienung_Tempomat_Bedienelement_3";
BA_ "SysSignalName" SG_ 393 OP_CCTR_OPEL_3 "OP_CCTR_OPEL_3";
BA_ "CompuMethodName" SG_ 393 QU_SER_OP_CCTR "QU_SER_OP_CCTR";
BA_ "ISignalName" SG_ 393 QU_SER_OP_CCTR "QU_SER_OP_CCTR";
BA_ "LongName" SG_ 393 QU_SER_OP_CCTR "Qualifier_Service_Bedienung_Tempomat";
BA_ "SysSignalName" SG_ 393 QU_SER_OP_CCTR "QU_SER_OP_CCTR";
BA_ "CompuMethodName" SG_ 938 OP_TZS_OFFS_MAN_UTC "OP_TZS_OFFS_UTC";
BA_ "GenSigStartValue" SG_ 938 OP_TZS_OFFS_MAN_UTC -20;
BA_ "ISignalName" SG_ 938 OP_TZS_OFFS_MAN_UTC "OP_TZS_OFFS_MAN_UTC";
BA_ "LongName" SG_ 938 OP_TZS_OFFS_MAN_UTC "Bedienung_Zeitzonen_Offset_Manuell_UTC";
BA_ "SysSignalName" SG_ 938 OP_TZS_OFFS_MAN_UTC "OP_TZS_OFFS_MAN_UTC";
BA_ "CompuMethodName" SG_ 938 OP_TZS_OFFS_AUTOMLY_UTC "OP_TZS_OFFS_UTC";
BA_ "GenSigStartValue" SG_ 938 OP_TZS_OFFS_AUTOMLY_UTC -20;
BA_ "ISignalName" SG_ 938 OP_TZS_OFFS_AUTOMLY_UTC "OP_TZS_OFFS_AUTOMLY_UTC";
BA_ "LongName" SG_ 938 OP_TZS_OFFS_AUTOMLY_UTC "Bedienung_Zeitzonen_Offset_Automatisch_UTC";
BA_ "SysSignalName" SG_ 938 OP_TZS_OFFS_AUTOMLY_UTC "OP_TZS_OFFS_AUTOMLY_UTC";
BA_ "CompuMethodName" SG_ 938 OP_OFFS_WIT_SUT_UTC "OP_OFFS_WIT_SUT_UTC";
BA_ "GenSigStartValue" SG_ 938 OP_OFFS_WIT_SUT_UTC -3;
BA_ "ISignalName" SG_ 938 OP_OFFS_WIT_SUT_UTC "OP_OFFS_WIT_SUT_UTC";
BA_ "LongName" SG_ 938 OP_OFFS_WIT_SUT_UTC "Bedienung_Offset_Winterzeit_Sommerzeit_UTC";
BA_ "SysSignalName" SG_ 938 OP_OFFS_WIT_SUT_UTC "OP_OFFS_WIT_SUT_UTC";
BA_ "CompuMethodName" SG_ 938 OP_CHB_T_ADJU_AUTOMLY_UTC "CHB_T_ADJU_AUTOMLY";
BA_ "ISignalName" SG_ 938 OP_CHB_T_ADJU_AUTOMLY_UTC "OP_CHB_T_ADJU_AUTOMLY_UTC";
BA_ "LongName" SG_ 938 OP_CHB_T_ADJU_AUTOMLY_UTC "Bedienung_Checkbox_Zeit_Einstellung_Automatisch_UTC";
BA_ "SysSignalName" SG_ 938 OP_CHB_T_ADJU_AUTOMLY_UTC "OP_CHB_T_ADJU_AUTOMLY_UTC";
BA_ "CompuMethodName" SG_ 938 OP_TZS_ID_UTC "CTI_TZS_ID";
BA_ "ISignalName" SG_ 938 OP_TZS_ID_UTC "OP_TZS_ID_UTC";
BA_ "LongName" SG_ 938 OP_TZS_ID_UTC "Bedienung_Zeitzonen_ID_UTC";
BA_ "SysSignalName" SG_ 938 OP_TZS_ID_UTC "OP_TZS_ID_UTC";
BA_ "CompuMethodName" SG_ 939 OP_HR_WIT_SUT_CGVR "OP_HR_WIT_SUT_CGVR";
BA_ "ISignalName" SG_ 939 OP_HR_WIT_SUT_CGVR "OP_HR_WIT_SUT_CGVR";
BA_ "LongName" SG_ 939 OP_HR_WIT_SUT_CGVR "Bedienung_Stunde_Winterzeit_Sommerzeit_Umstellung";
BA_ "SysSignalName" SG_ 939 OP_HR_WIT_SUT_CGVR "OP_HR_WIT_SUT_CGVR";
BA_ "CompuMethodName" SG_ 939 OP_MN_WIT_SUT_CGVR "OP_MN_WIT_SUT_CGVR";
BA_ "ISignalName" SG_ 939 OP_MN_WIT_SUT_CGVR "OP_MN_WIT_SUT_CGVR";
BA_ "LongName" SG_ 939 OP_MN_WIT_SUT_CGVR "Bedienung_Minute_Winterzeit_Sommerzeit_Umstellung";
BA_ "SysSignalName" SG_ 939 OP_MN_WIT_SUT_CGVR "OP_MN_WIT_SUT_CGVR";
BA_ "CompuMethodName" SG_ 939 OP_DATE_DAY_WIT_SUT_CGVR "OP_DATE_DAY_WIT_SUT_CGVR";
BA_ "ISignalName" SG_ 939 OP_DATE_DAY_WIT_SUT_CGVR "OP_DATE_DAY_WIT_SUT_CGVR";
BA_ "LongName" SG_ 939 OP_DATE_DAY_WIT_SUT_CGVR "Bedienung_Datum_Tag_Winterzeit_Sommerzeit_Umstellung";
BA_ "SysSignalName" SG_ 939 OP_DATE_DAY_WIT_SUT_CGVR "OP_DATE_DAY_WIT_SUT_CGVR";
BA_ "CompuMethodName" SG_ 939 OP_DATE_MON_WIT_SUT_CGVR "OP_DATE_MON_WIT_SUT_CGVR";
BA_ "GenSigStartValue" SG_ 939 OP_DATE_MON_WIT_SUT_CGVR 1;
BA_ "ISignalName" SG_ 939 OP_DATE_MON_WIT_SUT_CGVR "OP_DATE_MON_WIT_SUT_CGVR";
BA_ "LongName" SG_ 939 OP_DATE_MON_WIT_SUT_CGVR "Bedienung_Datum_Monat_Winterzeit_Sommerzeit_Umstellung";
BA_ "SysSignalName" SG_ 939 OP_DATE_MON_WIT_SUT_CGVR "OP_DATE_MON_WIT_SUT_CGVR";
BA_ "CompuMethodName" SG_ 939 OP_DATE_YR_WIT_SUT_CGVR "OP_DATE_YR_WIT_SUT_CGVR";
BA_ "ISignalName" SG_ 939 OP_DATE_YR_WIT_SUT_CGVR "OP_DATE_YR_WIT_SUT_CGVR";
BA_ "LongName" SG_ 939 OP_DATE_YR_WIT_SUT_CGVR "Bedienung_Datum_Jahr_Winterzeit_Sommerzeit_Umstellung";
BA_ "SysSignalName" SG_ 939 OP_DATE_YR_WIT_SUT_CGVR "OP_DATE_YR_WIT_SUT_CGVR";
BA_ "CompuMethodName" SG_ 939 OP_OFFS_NE_WIT_SUT "TZS_OFFS";
BA_ "GenSigStartValue" SG_ 939 OP_OFFS_NE_WIT_SUT -20;
BA_ "ISignalName" SG_ 939 OP_OFFS_NE_WIT_SUT "OP_OFFS_NE_WIT_SUT";
BA_ "LongName" SG_ 939 OP_OFFS_NE_WIT_SUT "Bedienung_Offset_Neu_Winterzeit_Sommerzeit";
BA_ "SysSignalName" SG_ 939 OP_OFFS_NE_WIT_SUT "OP_OFFS_NE_WIT_SUT";
BA_ "CompuMethodName" SG_ 657 OP_LANG "LANG";
BA_ "ISignalName" SG_ 657 OP_LANG "OP_LANG";
BA_ "LongName" SG_ 657 OP_LANG "Bedienung_Sprache";
BA_ "SysSignalName" SG_ 657 OP_LANG "OP_LANG";
BA_ "CompuMethodName" SG_ 657 OP_UN_DATE "UN_DATE";
BA_ "ISignalName" SG_ 657 OP_UN_DATE "OP_UN_DATE";
BA_ "LongName" SG_ 657 OP_UN_DATE "Bedienung_Einheit_Datum";
BA_ "SysSignalName" SG_ 657 OP_UN_DATE "OP_UN_DATE";
BA_ "CompuMethodName" SG_ 657 OP_UN_T "UN_T";
BA_ "ISignalName" SG_ 657 OP_UN_T "OP_UN_T";
BA_ "LongName" SG_ 657 OP_UN_T "Bedienung_Einheit_Zeit";
BA_ "SysSignalName" SG_ 657 OP_UN_T "OP_UN_T";
BA_ "CompuMethodName" SG_ 657 OP_UN_TEMP "UN_TEMP";
BA_ "ISignalName" SG_ 657 OP_UN_TEMP "OP_UN_TEMP";
BA_ "LongName" SG_ 657 OP_UN_TEMP "Bedienung_Einheit_Temperatur";
BA_ "SysSignalName" SG_ 657 OP_UN_TEMP "OP_UN_TEMP";
BA_ "CompuMethodName" SG_ 657 OP_UN_SPDM_DGTL "UN_SPDM_DGTL";
BA_ "ISignalName" SG_ 657 OP_UN_SPDM_DGTL "OP_UN_SPDM_DGTL";
BA_ "LongName" SG_ 657 OP_UN_SPDM_DGTL "Bedienung_Einheit_Tacho_Digital";
BA_ "SysSignalName" SG_ 657 OP_UN_SPDM_DGTL "OP_UN_SPDM_DGTL";
BA_ "CompuMethodName" SG_ 657 OP_UN_COSP "UN_COSP";
BA_ "ISignalName" SG_ 657 OP_UN_COSP "OP_UN_COSP";
BA_ "LongName" SG_ 657 OP_UN_COSP "Bedienung_Einheit_Verbrauch";
BA_ "SysSignalName" SG_ 657 OP_UN_COSP "OP_UN_COSP";
BA_ "CompuMethodName" SG_ 657 OP_UN_FU "UN_FU";
BA_ "ISignalName" SG_ 657 OP_UN_FU "OP_UN_FU";
BA_ "LongName" SG_ 657 OP_UN_FU "Bedienung_Einheit_Kraftstoff";
BA_ "SysSignalName" SG_ 657 OP_UN_FU "OP_UN_FU";
BA_ "CompuMethodName" SG_ 657 OP_UN_MILE "UN_MILE";
BA_ "ISignalName" SG_ 657 OP_UN_MILE "OP_UN_MILE";
BA_ "LongName" SG_ 657 OP_UN_MILE "Bedienung_Einheit_Wegstrecke";
BA_ "SysSignalName" SG_ 657 OP_UN_MILE "OP_UN_MILE";
BA_ "CompuMethodName" SG_ 657 OP_UN_AIP "UN_AIP";
BA_ "ISignalName" SG_ 657 OP_UN_AIP "OP_UN_AIP";
BA_ "LongName" SG_ 657 OP_UN_AIP "Bedienung_Einheit_Luftdruck";
BA_ "SysSignalName" SG_ 657 OP_UN_AIP "OP_UN_AIP";
BA_ "CompuMethodName" SG_ 657 OP_UN_DATE_EXT "OP_UN_DATE_EXT";
BA_ "ISignalName" SG_ 657 OP_UN_DATE_EXT "OP_UN_DATE_EXT";
BA_ "LongName" SG_ 657 OP_UN_DATE_EXT "Bedienung_Einheit_Datum_Erweitert";
BA_ "SysSignalName" SG_ 657 OP_UN_DATE_EXT "OP_UN_DATE_EXT";
BA_ "CompuMethodName" SG_ 657 OP_UN_PWR_S_MOD "OP_UN_PWR_S_MOD";
BA_ "ISignalName" SG_ 657 OP_UN_PWR_S_MOD "OP_UN_PWR_S_MOD";
BA_ "LongName" SG_ 657 OP_UN_PWR_S_MOD "Bedienung_Einheit_Leistung_Sport_Modus";
BA_ "SysSignalName" SG_ 657 OP_UN_PWR_S_MOD "OP_UN_PWR_S_MOD";
BA_ "CompuMethodName" SG_ 657 OP_UN_TORQ_S_MOD "OP_UN_TORQ_S_MOD";
BA_ "ISignalName" SG_ 657 OP_UN_TORQ_S_MOD "OP_UN_TORQ_S_MOD";
BA_ "LongName" SG_ 657 OP_UN_TORQ_S_MOD "Bedienung_Einheit_Drehmoment_Sport_Modus";
BA_ "SysSignalName" SG_ 657 OP_UN_TORQ_S_MOD "OP_UN_TORQ_S_MOD";
BA_ "CompuMethodName" SG_ 657 OP_UN_COSP_EL "OP_UN_COSP_EL";
BA_ "ISignalName" SG_ 657 OP_UN_COSP_EL "OP_UN_COSP_EL";
BA_ "LongName" SG_ 657 OP_UN_COSP_EL "Bedienung_Einheit_Verbrauch_Elektrisch";
BA_ "SysSignalName" SG_ 657 OP_UN_COSP_EL "OP_UN_COSP_EL";
BA_ "CompuMethodName" SG_ 801 BRIG_OFFS_HUD_3 "BRIG_OFFS_HUD_3";
BA_ "ISignalName" SG_ 801 BRIG_OFFS_HUD_3 "BRIG_OFFS_HUD_3";
BA_ "LongName" SG_ 801 BRIG_OFFS_HUD_3 "Helligkeit_Offset_HUD_3";
BA_ "SysSignalName" SG_ 801 BRIG_OFFS_HUD_3 "BRIG_OFFS_HUD_3";
BA_ "CompuMethodName" SG_ 801 STAN_HUD "STAN_HUD";
BA_ "ISignalName" SG_ 801 STAN_HUD "STAN_HUD";
BA_ "LongName" SG_ 801 STAN_HUD "Standanzeige_HUD";
BA_ "SysSignalName" SG_ 801 STAN_HUD "STAN_HUD";
BA_ "CompuMethodName" SG_ 801 HGAD_HUD_3 "HGAD_HUD_3";
BA_ "ISignalName" SG_ 801 HGAD_HUD_3 "HGAD_HUD_3";
BA_ "LongName" SG_ 801 HGAD_HUD_3 "Höhenverstellung_HUD_3";
BA_ "SysSignalName" SG_ 801 HGAD_HUD_3 "HGAD_HUD_3";
BA_ "CompuMethodName" SG_ 801 OP_SLCTN_RDOBUT_HUD "OP_SLCTN_RDOBUT_HUD";
BA_ "ISignalName" SG_ 801 OP_SLCTN_RDOBUT_HUD "OP_SLCTN_RDOBUT_HUD";
BA_ "LongName" SG_ 801 OP_SLCTN_RDOBUT_HUD "operation_selection_radiobutton_HUD";
BA_ "SysSignalName" SG_ 801 OP_SLCTN_RDOBUT_HUD "OP_SLCTN_RDOBUT_HUD";
BA_ "CompuMethodName" SG_ 801 ROTA_HUD "ROTA_HUD";
BA_ "ISignalName" SG_ 801 ROTA_HUD "ROTA_HUD";
BA_ "LongName" SG_ 801 ROTA_HUD "Rotationsverstellung_HUD";
BA_ "SysSignalName" SG_ 801 ROTA_HUD "ROTA_HUD";
BA_ "CompuMethodName" SG_ 801 OP_SLCTN_DISP_HUD_3 "OP_SLCTN_DISP_HUD_3";
BA_ "ISignalName" SG_ 801 OP_SLCTN_DISP_HUD_3 "OP_SLCTN_DISP_HUD_3";
BA_ "LongName" SG_ 801 OP_SLCTN_DISP_HUD_3 "Bedienung_Auswahl_Anzeige_HUD_3";
BA_ "SysSignalName" SG_ 801 OP_SLCTN_DISP_HUD_3 "OP_SLCTN_DISP_HUD_3";
BA_ "CompuMethodName" SG_ 801 OP_S_DISP_HUD "OP_S_DISP_HUD";
BA_ "ISignalName" SG_ 801 OP_S_DISP_HUD "OP_S_DISP_HUD";
BA_ "LongName" SG_ 801 OP_S_DISP_HUD "Bedienung_Sport_Anzeige_HUD";
BA_ "SysSignalName" SG_ 801 OP_S_DISP_HUD "OP_S_DISP_HUD";
BA_ "CompuMethodName" SG_ 801 OperationAdditionalDisplayHUD "AdditionalDisplayHUD";
BA_ "ISignalName" SG_ 801 OperationAdditionalDisplayHUD "OperationAdditionalDisplayHUD";
BA_ "LongName" SG_ 801 OperationAdditionalDisplayHUD "OperationAdditionalDisplayHUD";
BA_ "SysSignalName" SG_ 801 OperationAdditionalDisplayHUD "OperationAdditionalDisplayHUD";
BA_ "CompuMethodName" SG_ 880 OP_ECO_VL_THO_ECS_DXP "ECO_VL_THO_ECS_DXP";
BA_ "ISignalName" SG_ 880 OP_ECO_VL_THO_ECS_DXP "OP_ECO_VL_THO_ECS_DXP";
BA_ "LongName" SG_ 880 OP_ECO_VL_THO_ECS_DXP "Bedienung_ECO_Wert_Schwelle_ECOGeschwindigkeit_Fahrerlebnis";
BA_ "SysSignalName" SG_ 880 OP_ECO_VL_THO_ECS_DXP "OP_ECO_VL_THO_ECS_DXP";
BA_ "CompuMethodName" SG_ 880 OP_ECO_FN_ECS_DXP "ECO_FN_ECS_DXP";
BA_ "ISignalName" SG_ 880 OP_ECO_FN_ECS_DXP "OP_ECO_FN_ECS_DXP";
BA_ "LongName" SG_ 880 OP_ECO_FN_ECS_DXP "Bedienung_ECO_Funktion_ECOGeschwindigkeit_Fahrerlebnis";
BA_ "SysSignalName" SG_ 880 OP_ECO_FN_ECS_DXP "OP_ECO_FN_ECS_DXP";
BA_ "CompuMethodName" SG_ 880 OP_ECO_FN_FRSG_ASST_DXP "ECO_FN_FRSG_ASST_DXP";
BA_ "ISignalName" SG_ 880 OP_ECO_FN_FRSG_ASST_DXP "OP_ECO_FN_FRSG_ASST_DXP";
BA_ "LongName" SG_ 880 OP_ECO_FN_FRSG_ASST_DXP "Bedienung_ECO_Funktion_Vorausschau_Assistent_Fahrerlebnis";
BA_ "SysSignalName" SG_ 880 OP_ECO_FN_FRSG_ASST_DXP "OP_ECO_FN_FRSG_ASST_DXP";
BA_ "CompuMethodName" SG_ 880 OP_IDVL_RST_DISP_DXP "OP_IDVL_RST_DXP";
BA_ "ISignalName" SG_ 880 OP_IDVL_RST_DISP_DXP "OP_IDVL_RST_DISP_DXP";
BA_ "LongName" SG_ 880 OP_IDVL_RST_DISP_DXP "Bedienung_Individualisierung_Reset_Anzeige_Fahrerlebnis";
BA_ "SysSignalName" SG_ 880 OP_IDVL_RST_DISP_DXP "OP_IDVL_RST_DISP_DXP";
BA_ "CompuMethodName" SG_ 880 OP_ECO_FN_ECT_DXP "ECO_FN_ECT_DXP";
BA_ "ISignalName" SG_ 880 OP_ECO_FN_ECT_DXP "OP_ECO_FN_ECT_DXP";
BA_ "LongName" SG_ 880 OP_ECO_FN_ECT_DXP "Bedienung_ECO_Funktion_ECOTipps_Fahrerlebnis";
BA_ "SysSignalName" SG_ 880 OP_ECO_FN_ECT_DXP "OP_ECO_FN_ECT_DXP";
BA_ "CompuMethodName" SG_ 892 OP_ECO_FN_SAIL_DXP "ECO_FN_SAIL_DXP";
BA_ "ISignalName" SG_ 892 OP_ECO_FN_SAIL_DXP "OP_ECO_FN_SAIL_DXP";
BA_ "LongName" SG_ 892 OP_ECO_FN_SAIL_DXP "Bedienung_ECO_Funktion_Segeln_Fahrerlebnis";
BA_ "SysSignalName" SG_ 892 OP_ECO_FN_SAIL_DXP "OP_ECO_FN_SAIL_DXP";
BA_ "CompuMethodName" SG_ 892 OP_ECO_FN_MSA_DXP "ECO_FN_MSA_DXP";
BA_ "ISignalName" SG_ 892 OP_ECO_FN_MSA_DXP "OP_ECO_FN_MSA_DXP";
BA_ "LongName" SG_ 892 OP_ECO_FN_MSA_DXP "Bedienung_ECO_Funktion_MSA_Fahrerlebnis";
BA_ "SysSignalName" SG_ 892 OP_ECO_FN_MSA_DXP "OP_ECO_FN_MSA_DXP";
BA_ "CompuMethodName" SG_ 892 OP_S_FN_SHA_DXP "S_FN_SHA_DXP";
BA_ "ISignalName" SG_ 892 OP_S_FN_SHA_DXP "OP_S_FN_SHA_DXP";
BA_ "LongName" SG_ 892 OP_S_FN_SHA_DXP "Bedienung_Sport_Funktion_Schaltassistent_Fahrerlebnis";
BA_ "SysSignalName" SG_ 892 OP_S_FN_SHA_DXP "OP_S_FN_SHA_DXP";
BA_ "CompuMethodName" SG_ 892 OP_S_CLU_RPM_PA_DXP "S_CLU_DXP";
BA_ "ISignalName" SG_ 892 OP_S_CLU_RPM_PA_DXP "OP_S_CLU_RPM_PA_DXP";
BA_ "LongName" SG_ 892 OP_S_CLU_RPM_PA_DXP "Bedienung_Sport_Cluster_Drehzahl_Pfad_Fahrerlebnis";
BA_ "SysSignalName" SG_ 892 OP_S_CLU_RPM_PA_DXP "OP_S_CLU_RPM_PA_DXP";
BA_ "CompuMethodName" SG_ 892 OP_S_CLUG_ENG_DXP "S_CLU_DXP";
BA_ "ISignalName" SG_ 892 OP_S_CLUG_ENG_DXP "OP_S_CLUG_ENG_DXP";
BA_ "LongName" SG_ 892 OP_S_CLUG_ENG_DXP "Bedienung_Sport_Clustergruppe_Motor_Fahrerlebnis";
BA_ "SysSignalName" SG_ 892 OP_S_CLUG_ENG_DXP "OP_S_CLUG_ENG_DXP";
BA_ "CompuMethodName" SG_ 892 OP_IDVL_RST_DRV_DXP "OP_IDVL_RST_DXP";
BA_ "ISignalName" SG_ 892 OP_IDVL_RST_DRV_DXP "OP_IDVL_RST_DRV_DXP";
BA_ "LongName" SG_ 892 OP_IDVL_RST_DRV_DXP "Bedienung_Individualisierung_Reset_Antrieb_Fahrerlebnis";
BA_ "SysSignalName" SG_ 892 OP_IDVL_RST_DRV_DXP "OP_IDVL_RST_DRV_DXP";
BA_ "CompuMethodName" SG_ 892 OP_ADJU_SAIL_VEH "ADJU_SAIL_VEH";
BA_ "ISignalName" SG_ 892 OP_ADJU_SAIL_VEH "OP_ADJU_SAIL_VEH";
BA_ "LongName" SG_ 892 OP_ADJU_SAIL_VEH "Bedienung_Einstellung_Segeln_Fahrzeug";
BA_ "SysSignalName" SG_ 892 OP_ADJU_SAIL_VEH "OP_ADJU_SAIL_VEH";
BA_ "CompuMethodName" SG_ 892 OperationAdjustEngineSoundVehicl "AdjustEngineSoundVehicle";
BA_ "ISignalName" SG_ 892 OperationAdjustEngineSoundVehicl "OperationAdjustEngineSoundVehicle";
BA_ "LongName" SG_ 892 OperationAdjustEngineSoundVehicl "OperationAdjustEngineSoundVehicle";
BA_ "SysSignalName" SG_ 892 OperationAdjustEngineSoundVehicl "OperationAdjustEngineSoundVehicle";
BA_ "SystemSignalLongSymbol" SG_ 892 OperationAdjustEngineSoundVehicl "OperationAdjustEngineSoundVehicle";
BA_ "CompuMethodName" SG_ 745 OP_PUBU_EVEH "OP_PUBU_EVEH";
BA_ "ISignalName" SG_ 745 OP_PUBU_EVEH "OP_PUBU_EVEH";
BA_ "LongName" SG_ 745 OP_PUBU_EVEH "Bedienung_Taster_Elektrisches-Fahrzeug";
BA_ "SysSignalName" SG_ 745 OP_PUBU_EVEH "OP_PUBU_EVEH";
BA_ "CompuMethodName" SG_ 651 OP_PUBU_HUD "OP_PUBU";
BA_ "ISignalName" SG_ 651 OP_PUBU_HUD "OP_PUBU_HUD";
BA_ "LongName" SG_ 651 OP_PUBU_HUD "Bedienung_Taster_HUD";
BA_ "SysSignalName" SG_ 651 OP_PUBU_HUD "OP_PUBU_HUD";
BA_ "CompuMethodName" SG_ 604 OP_PUBU_LVCH "OP_PUBU_LVCH";
BA_ "ISignalName" SG_ 604 OP_PUBU_LVCH "OP_PUBU_LVCH";
BA_ "LongName" SG_ 604 OP_PUBU_LVCH "Bedienung_Taster_Niveauwechsel";
BA_ "SysSignalName" SG_ 604 OP_PUBU_LVCH "OP_PUBU_LVCH";
BA_ "CompuMethodName" SG_ 604 OP_PUBU_KEY "OP_PUBU_KEY";
BA_ "ISignalName" SG_ 604 OP_PUBU_KEY "OP_PUBU_KEY";
BA_ "LongName" SG_ 604 OP_PUBU_KEY "Bedienung_Taster_Schlüssel";
BA_ "SysSignalName" SG_ 604 OP_PUBU_KEY "OP_PUBU_KEY";
BA_ "CompuMethodName" SG_ 650 OP_PUBU_NIVI "OP_PUBU";
BA_ "ISignalName" SG_ 650 OP_PUBU_NIVI "OP_PUBU_NIVI";
BA_ "LongName" SG_ 650 OP_PUBU_NIVI "Bedienung_Taster_Night-Vision";
BA_ "SysSignalName" SG_ 650 OP_PUBU_NIVI "OP_PUBU_NIVI";
BA_ "CompuMethodName" SG_ 519 OP_SPD "OP_SPD";
BA_ "ISignalName" SG_ 519 OP_SPD "OP_SPD";
BA_ "LongName" SG_ 519 OP_SPD "Bedienung_Schaltpaddel";
BA_ "SysSignalName" SG_ 519 OP_SPD "OP_SPD";
BA_ "CompuMethodName" SG_ 609 CRC_OP_STW "CRC8";
BA_ "ISignalName" SG_ 609 CRC_OP_STW "CRC_OP_STW";
BA_ "LongName" SG_ 609 CRC_OP_STW "CRC_Bedienung_Lenkrad";
BA_ "SysSignalName" SG_ 609 CRC_OP_STW "CRC_OP_STW";
BA_ "CompuMethodName" SG_ 609 ALIV_OP_STW "ALIV_4_BIT_Unsigned_Integer";
BA_ "ISignalName" SG_ 609 ALIV_OP_STW "ALIV_OP_STW";
BA_ "LongName" SG_ 609 ALIV_OP_STW "Alive_Bedienung_Lenkrad";
BA_ "SysSignalName" SG_ 609 ALIV_OP_STW "ALIV_OP_STW";
BA_ "CompuMethodName" SG_ 609 CHL_OP_STW "CHL_4_UInt";
BA_ "ISignalName" SG_ 609 CHL_OP_STW "CHL_OP_STW";
BA_ "LongName" SG_ 609 CHL_OP_STW "CHL_Bedienung_Lenkrad";
BA_ "SysSignalName" SG_ 609 CHL_OP_STW "CHL_OP_STW";
BA_ "CompuMethodName" SG_ 609 OP_STW_OPEL_2 "OP_STW_OPEL";
BA_ "ISignalName" SG_ 609 OP_STW_OPEL_2 "OP_STW_OPEL_2";
BA_ "LongName" SG_ 609 OP_STW_OPEL_2 "Bedienung_Lenkrad_Bedienelement_2";
BA_ "SysSignalName" SG_ 609 OP_STW_OPEL_2 "OP_STW_OPEL_2";
BA_ "CompuMethodName" SG_ 609 OP_STW_OPEL_3 "OP_STW_OPEL";
BA_ "ISignalName" SG_ 609 OP_STW_OPEL_3 "OP_STW_OPEL_3";
BA_ "LongName" SG_ 609 OP_STW_OPEL_3 "Bedienung_Lenkrad_Bedienelement_3";
BA_ "SysSignalName" SG_ 609 OP_STW_OPEL_3 "OP_STW_OPEL_3";
BA_ "ISignalName" SG_ 609 OP_STW_dummy_24_31 "OP_STW_dummy_24_31";
BA_ "LongName" SG_ 609 OP_STW_dummy_24_31 "OP_STW_dummy_24_31";
BA_ "SysSignalName" SG_ 609 OP_STW_dummy_24_31 "OP_STW_dummy_24_31";
BA_ "ISignalName" SG_ 609 OP_STW_dummy_32_63 "OP_STW_dummy_32_63";
BA_ "LongName" SG_ 609 OP_STW_dummy_32_63 "OP_STW_dummy_32_63";
BA_ "SysSignalName" SG_ 609 OP_STW_dummy_32_63 "OP_STW_dummy_32_63";
BA_ "CompuMethodName" SG_ 727 OP_CHGNG_I_LIM_MOD_2 "OP_CHGNG_I_LIM_MOD_2";
BA_ "ISignalName" SG_ 727 OP_CHGNG_I_LIM_MOD_2 "OP_CHGNG_I_LIM_MOD_2";
BA_ "LongName" SG_ 727 OP_CHGNG_I_LIM_MOD_2 "Bedienung_Laden_Strom_Begrenzung_Modus_2";
BA_ "SysSignalName" SG_ 727 OP_CHGNG_I_LIM_MOD_2 "OP_CHGNG_I_LIM_MOD_2";
BA_ "CompuMethodName" SG_ 727 PopUpConfirmation "PopUpConfirmationCAN";
BA_ "ISignalName" SG_ 727 PopUpConfirmation "PopUpConfirmation";
BA_ "LongName" SG_ 727 PopUpConfirmation "PopUpConfirmation";
BA_ "SysSignalName" SG_ 727 PopUpConfirmation "PopUpConfirmation";
BA_ "CompuMethodName" SG_ 727 OperationChargingCurrentLimitMod "OperationChargingCurrentLimitMode2Status";
BA_ "ISignalName" SG_ 727 OperationChargingCurrentLimitMod "OperationChargingCurrentLimitMode2Status";
BA_ "LongName" SG_ 727 OperationChargingCurrentLimitMod "OperationChargingCurrentLimitMode2Status";
BA_ "SysSignalName" SG_ 727 OperationChargingCurrentLimitMod "OperationChargingCurrentLimitMode2Status";
BA_ "SystemSignalLongSymbol" SG_ 727 OperationChargingCurrentLimitMod "OperationChargingCurrentLimitMode2Status";
BA_ "CompuMethodName" SG_ 1051 OP_ACTVN_KI_BC "ACTVN_KI_BC";
BA_ "ISignalName" SG_ 1051 OP_ACTVN_KI_BC "OP_ACTVN_KI_BC";
BA_ "LongName" SG_ 1051 OP_ACTVN_KI_BC "Bedienung_Aktivierung_Kombi_BC";
BA_ "SysSignalName" SG_ 1051 OP_ACTVN_KI_BC "OP_ACTVN_KI_BC";
BA_ "CompuMethodName" SG_ 1051 OP_ACTVN_KI_CONT "ST_ACTVN_KI_CONT";
BA_ "ISignalName" SG_ 1051 OP_ACTVN_KI_CONT "OP_ACTVN_KI_CONT";
BA_ "LongName" SG_ 1051 OP_ACTVN_KI_CONT "Bedienung_Aktivierung_Kombi_Inhalt";
BA_ "SysSignalName" SG_ 1051 OP_ACTVN_KI_CONT "OP_ACTVN_KI_CONT";
BA_ "CompuMethodName" SG_ 1051 OP_ACTVN_PRESL_KI "ACTVN_PRESL_KI";
BA_ "ISignalName" SG_ 1051 OP_ACTVN_PRESL_KI "OP_ACTVN_PRESL_KI";
BA_ "LongName" SG_ 1051 OP_ACTVN_PRESL_KI "Bedienung_Aktivierung_Vorwahl_Kombi";
BA_ "SysSignalName" SG_ 1051 OP_ACTVN_PRESL_KI "OP_ACTVN_PRESL_KI";
BA_ "CompuMethodName" SG_ 1051 BRIG_OFFS_KI "BRIG_OFFS_KI";
BA_ "ISignalName" SG_ 1051 BRIG_OFFS_KI "BRIG_OFFS_KI";
BA_ "LongName" SG_ 1051 BRIG_OFFS_KI "brightness_offset_instrument-pack";
BA_ "SysSignalName" SG_ 1051 BRIG_OFFS_KI "BRIG_OFFS_KI";
BA_ "CompuMethodName" SG_ 974 OP_ACTVN_KI_CONT_2 "OP_ACTVN_KI_CONT_2";
BA_ "ISignalName" SG_ 974 OP_ACTVN_KI_CONT_2 "OP_ACTVN_KI_CONT_2";
BA_ "LongName" SG_ 974 OP_ACTVN_KI_CONT_2 "Bedienung_Aktivierung_Kombi_Inhalt_2";
BA_ "SysSignalName" SG_ 974 OP_ACTVN_KI_CONT_2 "OP_ACTVN_KI_CONT_2";
BA_ "CompuMethodName" SG_ 974 OP_ACTVN_PRESL_KI_2 "OP_ACTVN_PRESL_KI_2";
BA_ "ISignalName" SG_ 974 OP_ACTVN_PRESL_KI_2 "OP_ACTVN_PRESL_KI_2";
BA_ "LongName" SG_ 974 OP_ACTVN_PRESL_KI_2 "Bedienung_Aktivierung_Vorwahl_Kombi_2";
BA_ "SysSignalName" SG_ 974 OP_ACTVN_PRESL_KI_2 "OP_ACTVN_PRESL_KI_2";
BA_ "CompuMethodName" SG_ 974 OP_NAVI_DISP_TYP "OP_NAVI_DISP_TYP";
BA_ "ISignalName" SG_ 974 OP_NAVI_DISP_TYP "OP_NAVI_DISP_TYP";
BA_ "LongName" SG_ 974 OP_NAVI_DISP_TYP "Bedienung_Navigation_Anzeige_Typ";
BA_ "SysSignalName" SG_ 974 OP_NAVI_DISP_TYP "OP_NAVI_DISP_TYP";
BA_ "CompuMethodName" SG_ 974 BRIG_OFFS_KI_2 "BRIG_OFFS_KI_2";
BA_ "ISignalName" SG_ 974 BRIG_OFFS_KI_2 "BRIG_OFFS_KI_2";
BA_ "LongName" SG_ 974 BRIG_OFFS_KI_2 "Helligkeit_Offset_Kombi_2";
BA_ "SysSignalName" SG_ 974 BRIG_OFFS_KI_2 "BRIG_OFFS_KI_2";
BA_ "CompuMethodName" SG_ 974 OP_ENTAI_ECU_DISP "OP_ENTAI_ECU_DISP";
BA_ "ISignalName" SG_ 974 OP_ENTAI_ECU_DISP "OP_ENTAI_ECU_DISP";
BA_ "LongName" SG_ 974 OP_ENTAI_ECU_DISP "Bedienung_Entertainment_STG_Anzeige";
BA_ "SysSignalName" SG_ 974 OP_ENTAI_ECU_DISP "OP_ENTAI_ECU_DISP";
BA_ "CompuMethodName" SG_ 974 OperationDZMorPowermeterDisplay "DZMorPowermeterDisplay";
BA_ "ISignalName" SG_ 974 OperationDZMorPowermeterDisplay "OperationDZMorPowermeterDisplay";
BA_ "LongName" SG_ 974 OperationDZMorPowermeterDisplay "OperationDZMorPowermeterDisplay";
BA_ "SysSignalName" SG_ 974 OperationDZMorPowermeterDisplay "OperationDZMorPowermeterDisplay";
BA_ "CompuMethodName" SG_ 850 OP_SU_SAMD_EVEH "SU_SAMD_EVEH";
BA_ "ISignalName" SG_ 850 OP_SU_SAMD_EVEH "OP_SU_SAMD_EVEH";
BA_ "LongName" SG_ 850 OP_SU_SAMD_EVEH "Bedienung_Konfiguration_Aufstartmodus_Elektrisches-Fahrzeug";
BA_ "SysSignalName" SG_ 850 OP_SU_SAMD_EVEH "OP_SU_SAMD_EVEH";
BA_ "CompuMethodName" SG_ 850 OP_SU_RECUP_LEV "SU_RECUP_LEV";
BA_ "ISignalName" SG_ 850 OP_SU_RECUP_LEV "OP_SU_RECUP_LEV";
BA_ "LongName" SG_ 850 OP_SU_RECUP_LEV "Bedienung_Konfiguration_Rekuperation_Niveau";
BA_ "SysSignalName" SG_ 850 OP_SU_RECUP_LEV "OP_SU_RECUP_LEV";
BA_ "CompuMethodName" SG_ 850 OP_DSTN_SOC_BAS "DSTN_SOC_BAS";
BA_ "ISignalName" SG_ 850 OP_DSTN_SOC_BAS "OP_DSTN_SOC_BAS";
BA_ "LongName" SG_ 850 OP_DSTN_SOC_BAS "Bedienung_Ziel_SOC_Batterysave";
BA_ "SysSignalName" SG_ 850 OP_DSTN_SOC_BAS "OP_DSTN_SOC_BAS";
BA_ "CompuMethodName" SG_ 850 OP_ADJU_VEM_VEH "OP_ADJU_VEM_VEH";
BA_ "ISignalName" SG_ 850 OP_ADJU_VEM_VEH "OP_ADJU_VEM_VEH";
BA_ "LongName" SG_ 850 OP_ADJU_VEM_VEH "Bedienung_Einstellung_VEM_Fahrzeug";
BA_ "SysSignalName" SG_ 850 OP_ADJU_VEM_VEH "OP_ADJU_VEM_VEH";
BA_ "CompuMethodName" SG_ 850 OperationChargeControlPlug "OperationChargeControlPlug";
BA_ "ISignalName" SG_ 850 OperationChargeControlPlug "OperationChargeControlPlug";
BA_ "LongName" SG_ 850 OperationChargeControlPlug "OperationChargeControlPlug";
BA_ "SysSignalName" SG_ 850 OperationChargeControlPlug "OperationChargeControlPlug";
BA_ "CompuMethodName" SG_ 850 OperationAcCurrentLimit "OperationAcCurrentLimit";
BA_ "ISignalName" SG_ 850 OperationAcCurrentLimit "OperationAcCurrentLimit";
BA_ "LongName" SG_ 850 OperationAcCurrentLimit "OperationAcCurrentLimit";
BA_ "SysSignalName" SG_ 850 OperationAcCurrentLimit "OperationAcCurrentLimit";
BA_ "CompuMethodName" SG_ 611 OP_SMOR_ATZ "OP_SMOR_ATZ";
BA_ "ISignalName" SG_ 611 OP_SMOR_ATZ "OP_SMOR_ATZ";
BA_ "LongName" SG_ 611 OP_SMOR_ATZ "Bedienung_Smart-Opener-Heck_Autorisiert";
BA_ "SysSignalName" SG_ 611 OP_SMOR_ATZ "OP_SMOR_ATZ";
BA_ "CompuMethodName" SG_ 1026 PIA_FN_ID_DT_INQY "PIA_FN_ID";
BA_ "ISignalName" SG_ 1026 PIA_FN_ID_DT_INQY "PIA_FN_ID_DT_INQY";
BA_ "LongName" SG_ 1026 PIA_FN_ID_DT_INQY "PIA_Funktion_ID_Daten_Anfrage";
BA_ "SysSignalName" SG_ 1026 PIA_FN_ID_DT_INQY "PIA_FN_ID_DT_INQY";
BA_ "CompuMethodName" SG_ 1026 PIA_PROFIL_NO_DT_INQY "PIA_PROFIL_NO";
BA_ "ISignalName" SG_ 1026 PIA_PROFIL_NO_DT_INQY "PIA_PROFIL_NO_DT_INQY";
BA_ "LongName" SG_ 1026 PIA_PROFIL_NO_DT_INQY "PIA_Profil_Nummer_Daten_Anfrage";
BA_ "SysSignalName" SG_ 1026 PIA_PROFIL_NO_DT_INQY "PIA_PROFIL_NO_DT_INQY";
BA_ "CompuMethodName" SG_ 1027 PIA_FN_ID_DT_SET "PIA_FN_ID";
BA_ "ISignalName" SG_ 1027 PIA_FN_ID_DT_SET "PIA_FN_ID_DT_SET";
BA_ "LongName" SG_ 1027 PIA_FN_ID_DT_SET "PIA_Funktion_ID_Daten_Setzen";
BA_ "SysSignalName" SG_ 1027 PIA_FN_ID_DT_SET "PIA_FN_ID_DT_SET";
BA_ "CompuMethodName" SG_ 1027 PIA_PROFIL_NO_DT_SET "PIA_PROFIL_NO";
BA_ "ISignalName" SG_ 1027 PIA_PROFIL_NO_DT_SET "PIA_PROFIL_NO_DT_SET";
BA_ "LongName" SG_ 1027 PIA_PROFIL_NO_DT_SET "PIA_Profil_Nummer_Daten_Setzen";
BA_ "SysSignalName" SG_ 1027 PIA_PROFIL_NO_DT_SET "PIA_PROFIL_NO_DT_SET";
BA_ "CompuMethodName" SG_ 1027 PIA_VL_DT_SET "PIA_VL";
BA_ "ISignalName" SG_ 1027 PIA_VL_DT_SET "PIA_VL_DT_SET";
BA_ "LongName" SG_ 1027 PIA_VL_DT_SET "PIA_Wert_Daten_Setzen";
BA_ "SysSignalName" SG_ 1027 PIA_VL_DT_SET "PIA_VL_DT_SET";
BA_ "CompuMethodName" SG_ 1030 PIA_FN_ID_SU "PIA_FN_ID";
BA_ "ISignalName" SG_ 1030 PIA_FN_ID_SU "PIA_FN_ID_SU";
BA_ "LongName" SG_ 1030 PIA_FN_ID_SU "PIA_Funktion_ID_Konfiguration";
BA_ "SysSignalName" SG_ 1030 PIA_FN_ID_SU "PIA_FN_ID_SU";
BA_ "CompuMethodName" SG_ 1030 PIA_ST_INQY "PIA_ST_INQY";
BA_ "ISignalName" SG_ 1030 PIA_ST_INQY "PIA_ST_INQY";
BA_ "LongName" SG_ 1030 PIA_ST_INQY "PIA_Status_Anfrage";
BA_ "SysSignalName" SG_ 1030 PIA_ST_INQY "PIA_ST_INQY";
BA_ "CompuMethodName" SG_ 1032 PIA_ST_TRANA "PIA_ST_TRANA";
BA_ "ISignalName" SG_ 1032 PIA_ST_TRANA "PIA_ST_TRANA";
BA_ "LongName" SG_ 1032 PIA_ST_TRANA "PIA_Status_Transaktion";
BA_ "SysSignalName" SG_ 1032 PIA_ST_TRANA "PIA_ST_TRANA";
BA_ "CompuMethodName" SG_ 950 PO_WRG_DRD "PO_WRG_FS";
BA_ "ISignalName" SG_ 950 PO_WRG_DRD "PO_WRG_DRD";
BA_ "LongName" SG_ 950 PO_WRG_DRD "Position_Fensterheber_FAT";
BA_ "SysSignalName" SG_ 950 PO_WRG_DRD "PO_WRG_DRD";
BA_ "CompuMethodName" SG_ 950 ST_PO_WRG_DRD "ENUM_2_noIniVal_noDflVal_3_noQuant_noOffs_typeBitField_noRng_111";
BA_ "ISignalName" SG_ 950 ST_PO_WRG_DRD "ST_PO_WRG_DRD";
BA_ "LongName" SG_ 950 ST_PO_WRG_DRD "Status_Position_Fensterheber_FAT";
BA_ "SysSignalName" SG_ 950 ST_PO_WRG_DRD "ST_PO_WRG_DRD";
BA_ "CompuMethodName" SG_ 950 ST_DRV_WRG_DRD "ST_DRV_WRG";
BA_ "ISignalName" SG_ 950 ST_DRV_WRG_DRD "ST_DRV_WRG_DRD";
BA_ "LongName" SG_ 950 ST_DRV_WRG_DRD "Status_Antrieb_Fensterheber_FAT";
BA_ "SysSignalName" SG_ 950 ST_DRV_WRG_DRD "ST_DRV_WRG_DRD";
BA_ "CompuMethodName" SG_ 713 PRES_PO_X_IDT_CHGNG "PRES_PO_IDT_CHGNG";
BA_ "GenSigStartValue" SG_ 713 PRES_PO_X_IDT_CHGNG 2047;
BA_ "ISignalName" SG_ 713 PRES_PO_X_IDT_CHGNG "PRES_PO_X_IDT_CHGNG";
BA_ "LongName" SG_ 713 PRES_PO_X_IDT_CHGNG "Aktuelle_Position_X_Induktiv_Laden";
BA_ "SysSignalName" SG_ 713 PRES_PO_X_IDT_CHGNG "PRES_PO_X_IDT_CHGNG";
BA_ "CompuMethodName" SG_ 713 PRES_PO_Y_IDT_CHGNG "PRES_PO_IDT_CHGNG";
BA_ "GenSigStartValue" SG_ 713 PRES_PO_Y_IDT_CHGNG 2047;
BA_ "ISignalName" SG_ 713 PRES_PO_Y_IDT_CHGNG "PRES_PO_Y_IDT_CHGNG";
BA_ "LongName" SG_ 713 PRES_PO_Y_IDT_CHGNG "Aktuelle_Position_Y_Induktiv_Laden";
BA_ "SysSignalName" SG_ 713 PRES_PO_Y_IDT_CHGNG "PRES_PO_Y_IDT_CHGNG";
BA_ "CompuMethodName" SG_ 713 DIST_POSI_IDT_CHGNG "DIST_POSI_IDT_CHGNG";
BA_ "ISignalName" SG_ 713 DIST_POSI_IDT_CHGNG "DIST_POSI_IDT_CHGNG";
BA_ "LongName" SG_ 713 DIST_POSI_IDT_CHGNG "Distanz_Positionierung_Induktiv_Laden";
BA_ "SysSignalName" SG_ 713 DIST_POSI_IDT_CHGNG "DIST_POSI_IDT_CHGNG";
BA_ "CompuMethodName" SG_ 713 DCTR_IDT_CHGNG "DCTR_IDT_CHGNG";
BA_ "ISignalName" SG_ 713 DCTR_IDT_CHGNG "DCTR_IDT_CHGNG";
BA_ "LongName" SG_ 713 DCTR_IDT_CHGNG "Anzeigesteuerung_Induktiv_Laden";
BA_ "SysSignalName" SG_ 713 DCTR_IDT_CHGNG "DCTR_IDT_CHGNG";
BA_ "CompuMethodName" SG_ 713 DISP_POSI_IDT_CHGNG "DISP_POSI_IDT_CHGNG";
BA_ "ISignalName" SG_ 713 DISP_POSI_IDT_CHGNG "DISP_POSI_IDT_CHGNG";
BA_ "LongName" SG_ 713 DISP_POSI_IDT_CHGNG "Anzeige_Positionierung_Induktiv_Laden";
BA_ "SysSignalName" SG_ 713 DISP_POSI_IDT_CHGNG "DISP_POSI_IDT_CHGNG";
BA_ "CompuMethodName" SG_ 947 SLCTN_SPCOS "SLCTN_SPCOS";
BA_ "ISignalName" SG_ 947 SLCTN_SPCOS "SLCTN_SPCOS";
BA_ "LongName" SG_ 947 SLCTN_SPCOS "Auswahl_Sonderverbraucher";
BA_ "SysSignalName" SG_ 947 SLCTN_SPCOS "SLCTN_SPCOS";
BA_ "CompuMethodName" SG_ 947 CTR_CBR "CTR_CBR";
BA_ "ISignalName" SG_ 947 CTR_CBR "CTR_CBR";
BA_ "LongName" SG_ 947 CTR_CBR "Steuerung_Stromzweige";
BA_ "SysSignalName" SG_ 947 CTR_CBR "CTR_CBR";
BA_ "CompuMethodName" SG_ 947 CTR_PCOS "CTR_PCOS";
BA_ "ISignalName" SG_ 947 CTR_PCOS "CTR_PCOS";
BA_ "LongName" SG_ 947 CTR_PCOS "Steuerung_Standverbraucher";
BA_ "SysSignalName" SG_ 947 CTR_PCOS "CTR_PCOS";
BA_ "CompuMethodName" SG_ 947 CTR_PWRU_COS "PWRU_COS";
BA_ "ISignalName" SG_ 947 CTR_PWRU_COS "CTR_PWRU_COS";
BA_ "LongName" SG_ 947 CTR_PWRU_COS "Steuerung_Einschalten_Verbraucher";
BA_ "SysSignalName" SG_ 947 CTR_PWRU_COS "CTR_PWRU_COS";
BA_ "CompuMethodName" SG_ 947 ST_ENERG_PWMG "Energiezustand";
BA_ "ISignalName" SG_ 947 ST_ENERG_PWMG "ST_ENERG_PWMG";
BA_ "LongName" SG_ 947 ST_ENERG_PWMG "Status_Energie_Powermanagement";
BA_ "SysSignalName" SG_ 947 ST_ENERG_PWMG "ST_ENERG_PWMG";
BA_ "CompuMethodName" SG_ 947 CTR_AUXC "CTR_AUXC";
BA_ "ISignalName" SG_ 947 CTR_AUXC "CTR_AUXC";
BA_ "LongName" SG_ 947 CTR_AUXC "Steuerung_Nebenverbraucher";
BA_ "SysSignalName" SG_ 947 CTR_AUXC "CTR_AUXC";
BA_ "CompuMethodName" SG_ 511 ACLN_PVE "ACLN_Potentialvektor";
BA_ "ISignalName" SG_ 511 ACLN_PVE "ACLN_PVE";
BA_ "LongName" SG_ 511 ACLN_PVE "Beschleunigung_Potentialvektor";
BA_ "SysSignalName" SG_ 511 ACLN_PVE "ACLN_PVE";
BA_ "CompuMethodName" SG_ 511 ACLN_PVE_ERR_AMP "ACLN_Potentialvektor";
BA_ "ISignalName" SG_ 511 ACLN_PVE_ERR_AMP "ACLN_PVE_ERR_AMP";
BA_ "LongName" SG_ 511 ACLN_PVE_ERR_AMP "Beschleunigung_Potentialvektor_Fehler_Amplitude";
BA_ "SysSignalName" SG_ 511 ACLN_PVE_ERR_AMP "ACLN_PVE_ERR_AMP";
BA_ "CompuMethodName" SG_ 511 ACLNX_MAX_PVE "ACLNX_MAX_PVE";
BA_ "ISignalName" SG_ 511 ACLNX_MAX_PVE "ACLNX_MAX_PVE";
BA_ "LongName" SG_ 511 ACLNX_MAX_PVE "Längsbeschleunigung_Maximal_Potentialvektor";
BA_ "SysSignalName" SG_ 511 ACLNX_MAX_PVE "ACLNX_MAX_PVE";
BA_ "CompuMethodName" SG_ 511 MILE_LRN_ACLN_PVE "MILE_LRN_ACLN_PVE";
BA_ "ISignalName" SG_ 511 MILE_LRN_ACLN_PVE "MILE_LRN_ACLN_PVE";
BA_ "LongName" SG_ 511 MILE_LRN_ACLN_PVE "Wegstrecke_Lernen_Beschleunigung_Potentialvektor";
BA_ "SysSignalName" SG_ 511 MILE_LRN_ACLN_PVE "MILE_LRN_ACLN_PVE";
BA_ "CompuMethodName" SG_ 385 ShortTermStandStillProbability "ShortTermStandStillProbability";
BA_ "ISignalName" SG_ 385 ShortTermStandStillProbability "ShortTermStandStillProbability";
BA_ "LongName" SG_ 385 ShortTermStandStillProbability "ShortTermStandStillProbability";
BA_ "SysSignalName" SG_ 385 ShortTermStandStillProbability "ShortTermStandStillProbability";
BA_ "CompuMethodName" SG_ 385 PredictedLocation "PredictedLocation";
BA_ "ISignalName" SG_ 385 PredictedLocation "PredictedLocation";
BA_ "LongName" SG_ 385 PredictedLocation "PredictedLocation";
BA_ "SysSignalName" SG_ 385 PredictedLocation "PredictedLocation";
VAL_ 312 TAR_RPM_MAX_ENG 253 "Hinweis: Reserviert für funktionale Kennung Signal-Tag." 254 "Hinweis: Reserviert für funktionale Kennung Signal-Tag." 255 "Sendefunktion nicht in Betrieb.";
VAL_ 312 ST_CON_MSA_EXT 0 "Initialisierung" 1 "MSA Passiv. Unspezifischer Motorzustand" 2 "Kein MSA-Motorstopp angekündigt" 3 "MSA-Motorstopp angekündigt / Kommandierung MSA2.2 Stopp mit StatusDriveTargetSP2018 (maximaler Kraftschluss) => Kein KS Lösen" 4 "Darf nur gesetzt werden, wenn Getriebe Freigabe Motorstopp mit Teilentkopplung gesetzt wurde (ST_RLS_MSA_EXT)  / Kommandierung MSA2.1 Stopp mit StatusDriveTargetSP2018 (maximaler Kraftschluss) => Kein KS Lösen (ausgenommen gGA)" 5 "Darf nur gesetzt werden, wenn Getriebe Freigabe Motorstopp - Kraftschlussfreiheit gesetzt wurde (ST_RLS_MSA_EXT)" 6 "SST-Motorstopp angekündigt" 7 "MSA-Motorstopp aktiv" 8 "Motor_aus" 9 "(auch Retry)" 10 "Motorstart_durch_Verbrennungsenergie" 12 "Funktion_passiv_durch_Bedienelement" 13 "Ablegeverhinderung_von_FAS_Aktiv" 14 "MSA-Funktion aktiv. Motor dreht elektrisch angetrieben" 15 "MSA-Funktion passiv. Motor dreht elektrisch angetrieben." 16 "MSA-Funktion aktiv. Übergang in oder von Motor dreht elektrisch angetrieben." 253 "SIGNALTAG_FCTIF_NOT_AVAILABLE" 254 "SIGNALTAG_FCT_ERROR" 255 "Sendefunktion nicht in Betrieb";
VAL_ 312 ST_STA_VARI_MSA 1 "kein MSA-Motorstart" 2 "Schlüssel / Sicherstart auch nach Retry" 3 "MSA Start durch Bremse Lösen" 4 "MSA Start mit Fahrpedalbetätigung" 5 "MSA Start durch Systemanforderung" 6 "MSA Start durch Systemanforderung ohne Kraftschluss" 7 "Schleppstart über Antriebs-EM" 13 "Hinweis: Reserviert für funktionale Kennung Signal-Tag" 14 "Hinweis: Reserviert für funktionale Kennung Signal-Tag" 15 "Sendefunktion nicht in Betrieb";
VAL_ 312 ST_RPM_LIM_CENG 0 "Motor_nicht_im_Drehzahlbegrenzer" 1 "Motor_im_Drehzahlbegrenzer" 3 "Sendefunktion nicht in Betrieb.";
VAL_ 312 INHB_RQ_EZA 0 "Kein_EZA_Verbot_bei_Schaltung" 1 "EZA_Verbot_bei_Schaltung" 3 "Sendefunktion nicht in Betrieb";
VAL_ 312 RQ_EMMOD_VEH 0 "Keine_Anforderung" 1 "Motor_verzoegert_abwerfen" 3 "Sendefunktion nicht in Betrieb";
VAL_ 312 RQ_SUBST_REAC_GRB 0 "Keine_Anforderung" 1 "Anforderung Stillstands Sicherung bei FB aus" 3 "Sendefunktion nicht in Betrieb";
VAL_ 312 StatShutoffValveCCGearboxSP2018 0 "Abgesichert: AbsperrVentil angesteuert" 1 "Abgesichert: Absperrventil nicht angesteuert" 2 "Abgesichert: Absperrventil defekt" 3 "Sendefunktion nicht in Betrieb";
VAL_ 101 ST_BL_SW 0 "Keine Betätigung Bremslichtschalter erkannt: \"SIG_AN_INACTIVE\"" 3 "Betätigung Bremslichtschalter erkannt: \"SIG_AN_ACTIVE\"" 4 "Stromwert Bremslichtschalter im ungültigen Bereich: \"SIG_AN_INVALID\"." 5 "Stromwert Bremslichtschalter zeigt Kurzschluss: \"SIG_AN_SHORT_GND\"; \"SIG_AN_SHORT_VBAT\"." 6 "Stromwert Bremslichtschalter zeigt Open-Load: \"SIG_AN_OPEN\"" 7 "Stromwert Bremslichtschalter zeigt nicht verbaut: \"SIG_AN_NOTINSTALLED\"" 8 "Stromwert Bremslichtschalter zeigt nicht initialisiert: \"SIG_AN_INIT\", dieser Wert wird mit HW KL30B-aus gesendet" 15 "Wird funktional nicht bedient. \"SIG_AN_FAILURE\".";
VAL_ 101 ST_CLT_SW 0 "Keine Betätigung 90%-Kupplungsschalter erkannt" 1 "Betätigung 90%-Kupplungsschalter erkannt" 2 "Fehler 90%-Kupplungsauswertung erkannt" 3 "Signal ungültig oder kein Kupplungsschalter (z. B. AT-Getriebe)";
VAL_ 101 ST_MSA_PUBU 0 "MSA Taster nicht gedrückt" 1 "MSA Taster gedrückt" 3 "Signal ungültig";
VAL_ 101 ST_OP_SSP 0 "kein SST-Sensor erkannt" 1 "ein SST-Sensor erkannt" 2 "zwei SST-Sensoren erkannt" 3 "Signal ungültig";
VAL_ 101 ST_GPWSUP_STRT 0 "Starter_nicht_bestromt" 1 "Starter_wird_bestromt" 3 "Sendefunktion nicht in Betrieb";
VAL_ 642 INQY_PWR_COOL_BT_AIC 253 "Hinweis: Reserviert für funktionale Kennung Signal-Tag." 254 "Hinweis: Reserviert für funktionale Kennung Signal-Tag." 255 "Sendefunktion nicht in Betrieb.";
VAL_ 642 INQY_PWR_COOL_BT_FAST_AIC 253 "Hinweis: Reserviert für funktionale Kennung Signal-Tag." 254 "Hinweis: Reserviert für funktionale Kennung Signal-Tag." 255 "Sendefunktion nicht in Betrieb.";
VAL_ 642 INQY_PWR_DFR_AIC 4093 "Hinweis: Reserviert für funktionale Kennung Signal-Tag." 4094 "Hinweis: Reserviert für funktionale Kennung Signal-Tag." 4095 "Sendefunktion nicht in Betrieb.";
VAL_ 642 INQY_PWR_FOG_AIC 4093 "Hinweis: Reserviert für funktionale Kennung Signal-Tag." 4094 "Hinweis: Reserviert für funktionale Kennung Signal-Tag." 4095 "Sendefunktion nicht in Betrieb.";
VAL_ 645 INQY_PWR_CLDWN_AIC 253 "Hinweis: Reserviert für funktionale Kennung Signal-Tag." 254 "Hinweis: Reserviert für funktionale Kennung Signal-Tag." 255 "Sendefunktion nicht in Betrieb.";
VAL_ 645 INQY_PWR_HTUP_AIC 253 "Hinweis: Reserviert für funktionale Kennung Signal-Tag." 254 "Hinweis: Reserviert für funktionale Kennung Signal-Tag." 255 "Sendefunktion nicht in Betrieb.";
VAL_ 645 INQY_PWR_CNSR_COOL_AIC 253 "Hinweis: Reserviert für funktionale Kennung Signal-Tag." 254 "Hinweis: Reserviert für funktionale Kennung Signal-Tag." 255 "Sendefunktion nicht in Betrieb.";
VAL_ 645 INQY_PWR_CNSR_HT_AIC 253 "Hinweis: Reserviert für funktionale Kennung Signal-Tag." 254 "Hinweis: Reserviert für funktionale Kennung Signal-Tag." 255 "Sendefunktion nicht in Betrieb.";
VAL_ 645 INQY_PWR_PRECOND_INO_AIC 253 "Hinweis: Reserviert für funktionale Kennung Signal-Tag." 254 "Hinweis: Reserviert für funktionale Kennung Signal-Tag." 255 "Sendefunktion nicht in Betrieb.";
VAL_ 1189 TheoreticalMaxChargingPowerVehAC 509 "SIGNALTAG_FCTIF_NOT_AVAILABLE" 510 "SIGNALTAG_FCT_ERROR" 511 "Sendefunktion nicht in Betrieb";
VAL_ 1189 TheoreticalMaxChargingPowerVehDC 8189 "SIGNALTAG_FCTIF_NOT_AVAILABLE" 8190 "SIGNALTAG_FCT_ERROR" 8191 "Sendefunktion nicht in Betrieb";
VAL_ 1189 ActAvailMaxChargingPowerVehAC 509 "SIGNALTAG_FCTIF_NOT_AVAILABLE" 510 "SIGNALTAG_FCT_ERROR" 511 "Sendefunktion nicht in Betrieb";
VAL_ 1189 ActAvailMaxChargingPowerVehDC 8189 "SIGNALTAG_FCTIF_NOT_AVAILABLE" 8190 "SIGNALTAG_FCT_ERROR" 8191 "Sendefunktion nicht in Betrieb";
VAL_ 816 ST_FLLV_FUTA_SPAR 0 "Nicht Aktiv" 1 "Aktiv" 3 "Signal ungültig";
VAL_ 2675539972 KI_DBG_Dummy_11 253 "SIGNALTAG_FCTIF_NOT_AVAILABLE" 254 "SIGNALTAG_FCT_ERROR" 255 "Sendefunktion nicht in Betrieb";
VAL_ 2675539972 KI_DBG_Dummy_12 253 "SIGNALTAG_FCTIF_NOT_AVAILABLE" 254 "SIGNALTAG_FCT_ERROR" 255 "Sendefunktion nicht in Betrieb";
VAL_ 2675539972 KI_DBG_Dummy_13 253 "SIGNALTAG_FCTIF_NOT_AVAILABLE" 254 "SIGNALTAG_FCT_ERROR" 255 "Sendefunktion nicht in Betrieb";
VAL_ 2675539972 KI_DBG_Dummy_14 253 "SIGNALTAG_FCTIF_NOT_AVAILABLE" 254 "SIGNALTAG_FCT_ERROR" 255 "Sendefunktion nicht in Betrieb";
VAL_ 2675539972 KI_DBG_WD_Dummy_11 65533 "SIGNALTAG_FCTIF_NOT_AVAILABLE" 65534 "SIGNALTAG_FCT_ERROR" 65535 "Sendefunktion nicht in Betrieb";
VAL_ 2675539972 KI_DBG_WD_Dummy_12 65533 "SIGNALTAG_FCTIF_NOT_AVAILABLE" 65534 "SIGNALTAG_FCT_ERROR" 65535 "Sendefunktion nicht in Betrieb";
VAL_ 2675539973 KI_DBG_Dummy_21 253 "SIGNALTAG_FCTIF_NOT_AVAILABLE" 254 "SIGNALTAG_FCT_ERROR" 255 "Sendefunktion nicht in Betrieb";
VAL_ 2675539973 KI_DBG_Dummy_22 253 "SIGNALTAG_FCTIF_NOT_AVAILABLE" 254 "SIGNALTAG_FCT_ERROR" 255 "Sendefunktion nicht in Betrieb";
VAL_ 2675539973 KI_DBG_Dummy_23 253 "SIGNALTAG_FCTIF_NOT_AVAILABLE" 254 "SIGNALTAG_FCT_ERROR" 255 "Sendefunktion nicht in Betrieb";
VAL_ 2675539973 KI_DBG_Dummy_24 253 "SIGNALTAG_FCTIF_NOT_AVAILABLE" 254 "SIGNALTAG_FCT_ERROR" 255 "Sendefunktion nicht in Betrieb";
VAL_ 2675539973 KI_DBG_WD_Dummy_21 65533 "SIGNALTAG_FCTIF_NOT_AVAILABLE" 65534 "SIGNALTAG_FCT_ERROR" 65535 "Sendefunktion nicht in Betrieb";
VAL_ 2675539973 KI_DBG_WD_Dummy_22 65533 "SIGNALTAG_FCTIF_NOT_AVAILABLE" 65534 "SIGNALTAG_FCT_ERROR" 65535 "Sendefunktion nicht in Betrieb";
VAL_ 2675539969 DBG_FUTA_DISP 65533 "SIGNALTAG_FCTIF_NOT_AVAILABLE" 65534 "SIGNALTAG_FCT_ERROR" 65535 "Sendefunktion nicht in Betrieb";
VAL_ 2675539969 DBG_FUTA_DISP_RAW 65533 "SIGNALTAG_FCTIF_NOT_AVAILABLE" 65534 "SIGNALTAG_FCT_ERROR" 65535 "Sendefunktion nicht in Betrieb";
VAL_ 2675539969 DBG_FUTA_SPT 65533 "SIGNALTAG_FCTIF_NOT_AVAILABLE" 65534 "SIGNALTAG_FCT_ERROR" 65535 "Sendefunktion nicht in Betrieb";
VAL_ 2675539969 DBG_FUTA_ST 1 "Auftankerkennung_aktiv" 2 "Auftanken_erkannt" 4 "Auftanken_erkannt_und_durch_Neubewertung_getriggert" 8 "Tank voll erkannt" 16 "Beruhigungsphase_abgeschlossen" 32 "Referenzbildung_abgeschlossen" 64 "wird als Trigger für \"Kraftstoffreserve\" verwendet" 255 "Signal_unbefuellt";
VAL_ 2675539969 DBG_FUTA_PHA 1 "Keine_Geberfehler_aktiv" 2 "Ein_Geber_oder_beide_Geber_fehlerhaft_und_Verbrauchssignal_in_Ordnung" 3 "Ein_Geber_oder_beide_Geber_und_Verbrauchssignal_fehlerhaft" 255 "Signal_unbefuellt";
VAL_ 2675539971 DBG_RNG_BUR_RAW 65533 "SIGNALTAG_FCTIF_NOT_AVAILABLE" 65534 "SIGNALTAG_FCT_ERROR" 65535 "Sendefunktion nicht in Betrieb";
VAL_ 2675539971 DBG_RNG_BUR_DISP 65533 "SIGNALTAG_FCTIF_NOT_AVAILABLE" 65534 "SIGNALTAG_FCT_ERROR" 65535 "Sendefunktion nicht in Betrieb";
VAL_ 2675539971 DBG_RNG_BUR_COSP 65533 "SIGNALTAG_FCTIF_NOT_AVAILABLE" 65534 "SIGNALTAG_FCT_ERROR" 65535 "Sendefunktion nicht in Betrieb";
VAL_ 2675539971 DBG_RNG_DMPNG_RATE 65533 "SIGNALTAG_FCTIF_NOT_AVAILABLE" 65534 "SIGNALTAG_FCT_ERROR" 65535 "Sendefunktion nicht in Betrieb";
VAL_ 2675539970 DBG_RNG_EL_RAW 253 "SIGNALTAG_FCTIF_NOT_AVAILABLE" 254 "SIGNALTAG_FCT_ERROR" 255 "Sendefunktion nicht in Betrieb";
VAL_ 2675539970 DBG_RNG_EL_DISP 253 "SIGNALTAG_FCTIF_NOT_AVAILABLE" 254 "SIGNALTAG_FCT_ERROR" 255 "Sendefunktion nicht in Betrieb";
VAL_ 2675539970 DBG_RNG_EL_V 253 "SIGNALTAG_FCTIF_NOT_AVAILABLE" 254 "SIGNALTAG_FCT_ERROR" 255 "Sendefunktion nicht in Betrieb";
VAL_ 2675539970 DBG_RNG_EL_MV_REF 65533 "SIGNALTAG_FCTIF_NOT_AVAILABLE" 65534 "SIGNALTAG_FCT_ERROR" 65535 "Sendefunktion nicht in Betrieb";
VAL_ 2675539970 DBG_RNG_EL_COSP_DRV 65533 "SIGNALTAG_FCTIF_NOT_AVAILABLE" 65534 "SIGNALTAG_FCT_ERROR" 65535 "Sendefunktion nicht in Betrieb";
VAL_ 2675539968 DBG_FUTA_RESI_LH 65533 "SIGNALTAG_FCTIF_NOT_AVAILABLE" 65534 "SIGNALTAG_FCT_ERROR" 65535 "Sendefunktion nicht in Betrieb";
VAL_ 2675539968 DBG_FUTA_RESI_RH 65533 "SIGNALTAG_FCTIF_NOT_AVAILABLE" 65534 "SIGNALTAG_FCT_ERROR" 65535 "Sendefunktion nicht in Betrieb";
VAL_ 2675539968 DBG_FUTA_LH 65533 "SIGNALTAG_FCTIF_NOT_AVAILABLE" 65534 "SIGNALTAG_FCT_ERROR" 65535 "Sendefunktion nicht in Betrieb";
VAL_ 2675539968 DBG_FUTA_RH 65533 "SIGNALTAG_FCTIF_NOT_AVAILABLE" 65534 "SIGNALTAG_FCT_ERROR" 65535 "Sendefunktion nicht in Betrieb";
VAL_ 303 ALIV_COU_KL 15 "Signal ungültig";
VAL_ 303 ST_KL 0 "Init" 1 "Reserve" 2 "Alle Klemmen aus. Kodierung wird im Regelfall nicht versendet, da in diesem Zustand im Regelfall Busruhe herrscht. Hinweis: Für Information über den Status von Klemme30F (z.B. Steuerung des Einschlafvorgangs im Fehlerfall) ist das Signal Nachlaufzeit_Klemme_30_fehlergesteuert zu verwenden, da dieses Signal zusätzlich den Abschaltvorgang der KL30F über die verbleibende Dauer der Nachlaufzeit anzeigt." 3 "Kodierung wird im Regelfall nicht versendet (siehe Beschreibung KL30)." 4 "Wird nicht in allen Fällen versendet (wg. Busruhe)." 5 "Wird nicht in allen Fällen versendet, da zum Zeitpunkt der KL30B-Abschaltung bereits Busruhe herrschen kann. Der Abschaltvorgang KL30B wird über das Signal Nachlaufzeit_Stromversorgung angekündigt." 6 "KL30B-Ein" 7 "Diese Signalcodierung wird ab 35up nicht mehr verschickt. Entfall wegen Einführung von PWF." 8 "Diese Signalcodierung wird ab 35up nicht mehr verschickt. Entfall wegen Einführung von PWF." 9 "KL15-Änderung" 10 "KL15-Ein" 11 "Komfortstart aktiv, Diesel vorglühen, Motor-Relais anziehen" 12 "KL50-Änderung" 13 "KL50-Ein" 14 "Fehler" 15 "Signal ungültig";
VAL_ 303 ST_KL_30B 0 "Init-Wert" 1 "KL30BAus" 2 "Nachlauf größer 0s und kleinergleich 1 s" 3 "Nachlauf größer 1s und kleinergleich 5 s" 4 "Nachlauf größer 5s und kleinergleich 10 s" 5 "Nachlauf größer 10s und kleinergleich 20 s" 6 "Nachlauf größer 20s und kleinergleich 30 s" 7 "Nachlauf größer 30s und kleinergleich 40 s" 8 "Nachlauf größer 40s und kleinergleich 50 s" 9 "Nachlauf größer 50s und kleinergleich 1 min" 10 "Nachlauf größer 1min und kleinergleich 5 min" 11 "Nachlauf größer 5min und kleinergleich 10 min" 12 "Nachlauf größer 10min" 13 "KL30B-Dauer-Ein" 14 "Fehler" 15 "Signal ungültig";
VAL_ 303 ST_KL_15N 0 "Init-Wert" 1 "KL15N-Aus" 2 "Nachlauf größer 0s und  kleinergleich 1000ms" 3 "Nachlauf größer 1000ms und kleinergleich 2000ms" 4 "Nachlauf größer 2000ms und kleinergleich 3000ms" 5 "Nachlauf größer 3000ms und kleinergleich 4000ms" 6 "Nachlauf größer 4000ms undkleinergleich 5000ms" 7 "Reserviert" 8 "Reserviert" 9 "Reserviert" 10 "Reserviert" 11 "Nachlauf kleiner 1 min" 12 "Nachlauf Fahrt/Motorlauf" 13 "KL15N-Dauer-Ein" 14 "Fehler" 15 "Signal ungültig";
VAL_ 303 ST_KL_DBG 255 "Signal ungültig";
VAL_ 538 ST_DIPB 0 "Abblendlicht aus/ein" 1 "EIN";
VAL_ 538 ST_MBHF 0 "AUS" 1 "EIN";
VAL_ 538 ST_POLI 0 "Standlicht aus/ein" 1 "EIN";
VAL_ 538 ST_PLI_LH 0 "Parklicht links aus/ein" 1 "EIN";
VAL_ 538 ST_PLI_RH 0 "Parklicht rechts aus/ein" 1 "EIN";
VAL_ 538 ST_FFLI 0 "AUS" 1 "EIN";
VAL_ 538 ST_RFLI 0 "Nebelschlußleuchten aus/ein" 1 "EIN";
VAL_ 538 ST_STLI 0 "Bremsleuchten aus/ein" 1 "EIN";
VAL_ 538 ST_RVLI 0 "Rückfahrscheinwerfer aus/ein" 1 "EIN";
VAL_ 538 ST_RPLIS 0 "Kennzeichenbeleuchtung aus/ein" 1 "EIN";
VAL_ 538 ST_LOWB_DAY 0 "Fahrlicht aus" 1 "Fahrlicht ein";
VAL_ 538 ST_LIST_ERR 0 "Lampenzustands-Signale sind in Ordnung" 1 "Initialwert wird übertragen" 3 "Signalwerte sind ungültig";
VAL_ 538 ST_MAB_ASST 1 "Fernlichtassistent nicht aktiviert" 2 "Fernlichtassistent aktiviert" 3 "Signal ungültig";
VAL_ 915 DMPNG_LCD_LUM 255 "Signal ungültig";
VAL_ 915 DAY_NI_CHOV 0 "keine Änderung" 1 "Tag" 2 "Nacht" 3 "Signal ungültig";
VAL_ 1077 ST_OILV_MEASMT_1 0 "Es sind alle Randbedingungen erfüllt" 1 "Gang eingelegt oder Kupplung getreten" 2 "Fahrpedal getreten" 4 "Geschwindigkeit größer Schwelle (i.d.R 3 h/km)" 8 "keine Reaktion auf Anforderung" 15 "Öllevel außerhalb der Toleranz" 16 "Öldruck außerhalb Toleranz" 32 "Neigung außerhalb Toleranz" 64 "Motordrehzahl außerhalb Tolerenz" 128 "Motoröltemperatur außerhalb Toleranz" 255 "DME im Wakeup oder Nachlauf" 4093 "Hinweis: Reserviert für funktionale Kennung Signal-Tag." 4094 "Hinweis: Reserviert für funktionale Kennung Signal-Tag." 4095 "Zustand kein Ergebnis";
VAL_ 1077 FLLV_EOI_REL 0 "Ausgabe Motorölstand unter Minimum" 1 "Ausgabe Motorölstand am Minimum" 2 "Ausgabe Motorölstand auf 1/4" 3 "Ausgabe Motorölstand auf 2/4" 4 "Ausgabe Motorölstand auf 3/4" 5 "Ausgabe Motorölstand auf 4/4" 6 "Ausgabe Motorölstand auf 4/4" 7 "Ausgabe Motorölstand überfüllt" 13 "Ausgabe Motorölstand in Ordnung" 14 "Servicefunktion wird ausgeführt" 15 "Liegt auch an bei Detailmessung läuft, Abbruch, Wakeup, Nachlauf, Sensorfehler, keine Applikationsdaten";
VAL_ 1077 ST_OILV_MEASMT_2 0 "Es wurde noch kein Wert oder Ersatzwert berechnet" 1 "Abstellzeit nicht ausreichend" 2 "Es wurde noch kein Messwert in der Minimumerkennung berechnet" 4 "Detailmessung wird durchgeführt" 8 "OLC-Messung wird durchgeführt" 16 "Es liegt ein Wert zum Füllstand vor" 18 "Es liegt noch kein Wert zum Füllstand vor" 32 "Es liegt keine gültige Rückmeldung auf die Steuerungsanforderung vor" 64 "Es liegt ein Sensorfehler vor" 128 "Es sind keine gültigen Applikationsdaten vorhanden" 255 "DME im Wakeup oder Nachlauf" 4093 "Hinweis: Reserviert für funktionale Kennung Signal-Tag." 4094 "Hinweis: Reserviert für funktionale Kennung Signal-Tag." 4095 "Signal_unbefuellt";
VAL_ 1077 ST_OILV_MEASMT_POSS 0 "Detailmessung nicht erlaubt, nicht alle Randbedinungen erfüllt" 1 "Detailmessung erlaubt, alle Randbedingungen erfüllt" 3 "Signal_unbefuellt";
VAL_ 523 ST_MEMO_FN 0 "Keine Aktion" 1 "Abrufen" 2 "Speichern" 3 "Signal ungültig";
VAL_ 523 PO_MEMO 0 "Ungueltige_Speicherplatznummer" 1 "(im E63/64 nicht genutzt) Keine PIA ID, nur Memory" 2 "(im E63/64 nicht genutzt) Keine PIA ID, nur Memory" 3 "Letzte_Position" 253 "SIGNALTAG_FCTIF_NOT_AVAILABLE" 254 "SIGNALTAG_FCT_ERROR" 255 "Signal ungültig";
VAL_ 699 QU_MILE_VEH 1 "Wird funktional nicht befüllt" 2 "Nutzsignal verfügbar" 3 "Wird funktional nicht befüllt" 4 "Wird funktional nicht befüllt" 6 "Wird funktional nicht befüllt. Das zugehörige Nutzsignal wird permanent mit der Ungültigkeitskennung befüllt." 7 "Wird funktional nicht befüllt. Das zugehörige Nutzsignal wird permanent mit der Ungültigkeitskennung befüllt." 8 "Tritt während  der Initialisierungsphase auf bis Ist-Wert verfügbar (Vorbefüllung). Nutzsignal wird permanent mit Nutzwert 0 befüllt." 9 "Wird funktional nicht befüllt" 10 "Wird funktional nicht befüllt" 11 "Wird funktional nicht befüllt" 12 "Wird funktional nicht befüllt" 14 "Das zugehörige Nutzsignal wird permanent mit der Ungültigkeitskennung befüllt." 15 "Kann nur vom Gateway gesetzt werden";
VAL_ 1074 ActualValueThermicCoolingUrgency 61 "SIGNALTAG_FCTIF_NOT_AVAILABLE" 62 "SIGNALTAG_FCT_ERROR" 63 "Send function not in operation";
VAL_ 1074 AVL_COOL_HVSTO_1 61 "Übertragung der Zustände über Statussignal" 62 "Übertragung der Zustände über Statussignal" 63 "Sendefunktion nicht in Betrieb";
VAL_ 1074 ST_AVL_COOL_HVSTO_1 0 "Speicherkuehlung nicht ausreichend" 1 "Speicherkühlung ausreichend" 2 "Kühler nicht verbaut" 3 "Sendefunktion nicht in Betrieb";
VAL_ 1074 ST_STOR_AIC_COOL_RQMT 253 "SIGNALTAG_FCTIF_NOT_AVAILABLE" 254 "SIGNALTAG_FCT_ERROR" 255 "Signal Tag - Signal ist unbefüllt";
VAL_ 1074 AVL_COOL_HVSTO_2 61 "Übertragung der Zustände über Statussignal" 62 "Übertragung der Zustände über Statussignal" 63 "Sendefunktion nicht in Betrieb";
VAL_ 1074 ST_AVL_COOL_HVSTO_2 0 "Speicherkuehlung nicht ausreichend" 1 "Speicherkühlung ausreichend" 2 "Kühler nicht verbaut" 3 "Sendefunktion nicht in Betrieb";
VAL_ 1085 IDX_PRES_SEG_NAVGRPH_2 255 "Signal ungültig";
VAL_ 1085 DIR_CHNG_ANG_SEG_NAVGRPH_2 4095 "Signal ungültig";
VAL_ 1085 RAD_PRES_SEG_NAVGRPH_2 4095 "Signal ungültig";
VAL_ 1085 QUAN_LNS_NAVGRPH_2 0 "6 und mehr Spuren" 1 "1 Spur" 2 "2 Spuren" 3 "3 Spuren" 4 "4 Spuren" 5 "5 und mehr Spuren" 6 "Wert nicht verfügbar" 7 "Signal ungültig";
VAL_ 1085 TYP_STREET_NAVGRPH_2 0 "Gleis" 1 "Verkehrsberuhigte Zone (hin und zurück)" 2 "Verkehrsberuhigte Zone (Einbahnstraße)" 3 "Wohngebiet (hin und zurück)" 4 "Wohngebiet (Einbahnstraße)" 5 "städtisch (hin und zurück)" 6 "städtisch (Einbahnstraße)" 7 "städtisch mit Teilung" 8 "Stadt-Autobahn" 9 "Stadt-Autobahn mit Teilung" 10 "Landstraße" 11 "Landstraße mit Teilung" 12 "Bundesstraße" 13 "Bundesstraße mit Teilung" 14 "Bundesstraßen-Auffahrt" 15 "Bundesstraßen-Ausfahrt" 16 "Bundesstraßen-Auf- und -Ausfahrt" 17 "Autobahn" 18 "Autobahn-Auffahrt" 19 "Autobahn-Ausfahrt" 20 "Autobahn-Auf- und Ausfahrt" 21 "Fähre" 22 "Rennstrecke" 30 "Straßentyp nicht verfügbar" 31 "Signal ungültig";
VAL_ 1085 L_SEG_NAVGRPH_2 255 "Signal ungültig";
VAL_ 1085 PROP_MAP_NAVGRPH_2 0 "Es liegt keine allgemeine Geschwindigkeitsbegrenzung vor / nicht verfügbar" 1 "Kartensegment befindet sich innerhalb eines  bebauten Gebiets" 2 "Kreuzungsfrei ausgebautes Kartesegment" 4 "Kartensegment ist ein Kreisverkehr" 8 "Parkfläche am Kartensegment" 16 "Kartensegment ist eine Rampe" 32 "Ampel am Ende des Kartensegments" 64 "(Daten nicht vor 2012 verfügbar)" 128 "(Daten nicht vor 2012 verfügbar)" 256 "Segment hat Linksverkehr" 512 "(Daten nicht vor 2012 verfügbar)" 2046 "nicht verfügbar" 2047 "Signal ungültig";
VAL_ 1085 LIM_V_NAVGRPH_2 0 "keine Geschwindigkeitsbegrenzung" 1 "5 (in Deutschland: 6)" 2 "10" 3 "15" 4 "20" 5 "25" 6 "30" 7 "35" 8 "40" 9 "45" 10 "50" 11 "55" 12 "60" 13 "65" 14 "70" 15 "75" 16 "80" 17 "85" 18 "90" 19 "95" 20 "100" 21 "105" 22 "110" 23 "115" 24 "120" 25 "125" 26 "130" 27 "135" 28 "140" 29 "145" 30 "Daten nicht verfügbar" 31 "Signal ungültig";
VAL_ 844 ST_HG_NAVI 32767 "Wert nicht verfügbar";
VAL_ 844 ST_V_HRZTL 32767 "Wert nicht verfügbar";
VAL_ 844 ST_HDG_HRZTL_ABSL 254 "Wert nicht verfügbar" 255 "Signal ungültig";
VAL_ 844 ST_QUAL_PO 0 "Quality 0..7 (Sigma tbd)" 1 "Dead Reckoning kalibriert" 2 "GPS 2D Fix" 4 "GPS 3D Fix" 8 "Differential GPS" 16 "Onroad/Offroad" 4094 "Signal nicht verfügbar" 4095 "Signal ungültig";
VAL_ 632 IDX_SEG_NAVGRPH 255 "Signal ungültig";
VAL_ 632 IDX_FSEG_NAVGRPH 255 "Signal ungültig";
VAL_ 632 GRAD_NAVGRPH 127 "Signal ungültig";
VAL_ 632 L_SEG_NAVGRPH 255 "Signal ungültig";
VAL_ 632 TYP_STREET_NAVGRPH 0 "Gleis" 1 "Verkehrsberuhigte Zone (hin und zurück)" 2 "Verkehrsberuhigte Zone (Einbahnstraße)" 3 "Wohngebiet (hin und zurück)" 4 "Wohngebiet (Einbahnstraße)" 5 "städtisch (hin und zurück)" 6 "städtisch (Einbahnstraße)" 7 "städtisch mit Teilung" 8 "Stadt-Autobahn" 9 "Stadt-Autobahn mit Teilung" 10 "Landstraße" 11 "Landstraße mit Teilung" 12 "Bundesstraße" 13 "Bundesstraße mit Teilung" 14 "Bundesstraßen-Auffahrt" 15 "Bundesstraßen-Ausfahrt" 16 "Bundesstraßen-Auf- und -Ausfahrt" 17 "Autobahn" 18 "Autobahn-Auffahrt" 19 "Autobahn-Ausfahrt" 20 "Autobahn-Auf- und Ausfahrt" 21 "Fähre" 22 "Rennstrecke" 30 "Straßentyp nicht verfügbar" 31 "Signal ungültig";
VAL_ 840 ST_MTCH_PO_REL 255 "Sendefunktion nicht in Betrieb";
VAL_ 840 ST_MTCH_IDX_SEG 255 "Signal ungültig";
VAL_ 840 ST_MTCH_UNIQ_PO 255 "Sendefunktion nicht in Betrieb";
VAL_ 840 PRES_LNE 0 "Konfidenz_Spurposition_0_bis_9_Prozent" 1 "Erste Fahrspur" 2 "Zweite Fahrspur" 3 "Dritte Fahrspur" 4 "Vierte Fahrspur" 5 "Fünfte Fahrspur" 6 "Sechste Fahrspur" 7 "Siebente Fahrspur" 8 "Achte Fahrspur" 9 "Neunte Fahrspur" 10 "Zehnte Fahrspur" 11 "Elfte Fahrspur" 12 "Zwölfte Fahrspur" 14 "Fahrspurposition nicht verfügbar" 16 "Konfidenz_Spurposition_10_bis_19_Prozent" 32 "Konfidenz_Spurposition_20_bis_29_Prozent" 48 "Konfidenz_Spurposition_30_bis_39_Prozent" 64 "Konfidenz_Spurposition_40_bis_49_Prozent" 80 "Konfidenz_Spurposition_50_bis_59_Prozent" 96 "Konfidenz_Spurposition_60_bis_69_Prozent" 112 "Konfidenz_Spurposition_70_bis_79_Prozent" 128 "Konfidenz_Spurposition_80_bis_89_Prozent" 144 "Konfidenz_Spurposition_90_bis_94_Prozent" 160 "Konfidenz_Spurposition_95_bis_100_Prozent" 176 "Konfidenz_Spurposition_nicht_verfuegbar" 254 "Signal nicht verfügbar" 255 "Signal ungültig";
VAL_ 840 ST_MTCH_TSTMP 65535 "Sendefunktion nicht in Betrieb";
VAL_ 840 ST_MTCH_QUAL 255 "Sendefunktion nicht in Betrieb";
VAL_ 634 ST_QUAN_PCKGS 255 "Signal ungültig";
VAL_ 634 COU_NAVGRPH_SYNC 255 "Signal ungültig";
VAL_ 634 CRC16_NAVGRPH_SYNC 65535 "Sendefunktion nicht in Betrieb";
VAL_ 634 MOD_TRNSM_NAVGRPH_SYNC 255 "Signal ungültig";
VAL_ 634 IDX_SEG_DEL_NAVGRPH 255 "Signal ungültig";
VAL_ 634 CTR_DEL_NAVGRPH 0 "Kein Kill-Mechanismus" 1 "Kill one" 2 "Kill up" 3 "Kill down" 4 "Kill all" 6 "Signal nicht verfügbar" 7 "Signal ungültig";
VAL_ 634 AUINF_NAVGRPH_SYNC 0 "Geschwindigkeitsbegrenzung in km/h" 1 "Tunnel" 2 "Tunnelinformation nicht verfügbar" 4 "Brücke" 8 "Brückeninformation nicht verfügbar" 16 "Wald" 32 "Waldinformation nicht verfügbar" 42 "Signal nicht verfügbar" 64 "Linksverkehr" 128 "Geschwindigkeitsbegrenzung in mph" 255 "Signal ungültig";
VAL_ 846 ST_OPET_NAVI 16777215 "Signal ungültig";
VAL_ 846 ST_VRS_PRTL_NAVI 0 "Protokollversion 1.1.10" 1 "Protokollversion 1.2" 2 "NavGraphV 0x3F7 and NavGraphLne 0x3CC Extension" 3 "NavGraphMapData 0x42C Extension" 4 "1D Horizon Extension" 5 "Erweiterte Spurinformation" 6 "Protokollversion 2.2" 7 "Protokollversion 2.3" 8 "Protokollversion 2.4" 254 "Signal nicht verfügbar" 255 "Signal ungültig";
VAL_ 846 ST_VRS_HW_NAVI 0 "CCC" 1 "CIC" 2 "Champ2" 3 "NBT_oder_NBTevo" 4 "EntryNav_oder_EntryNavEvo" 5 "Vorhalt_fuer_Nachfolge_Headunit_1" 6 "Vorhalt_fuer_Nachfolge_Headunit_2" 7 "Vorhalt_fuer_Nachfolge_Headunit_3" 8 "Vorhalt_fuer_Nachfolge_Headunit_4" 30 "Signal nicht verfügbar" 31 "Signal ungültig";
VAL_ 846 ST_VRS_HW_NAVI_MANU 0 "Siemens VDO" 1 "Alpine" 2 "Blaupunkt" 3 "Becker" 4 "N.N." 5 "N.N." 6 "Signal nicht verfügbar" 7 "Signal ungültig";
VAL_ 846 ST_VRS_MAP_NAVI 0 "Map database from current year" 1 "Map database 1 year old" 2 "Map-Version 3" 3 "Map-Version 4" 4 "Map-Version 5" 5 "Map-Version 6" 6 "Map-Version 7" 7 "Map-Version 8" 8 "Map-Version 9" 9 "Map-Version 10" 10 "Map-Version 11" 11 "Map-Version 12" 12 "Map-Version 13" 13 "Map-Version 14" 14 "Map-Version 15" 15 "Map-Version 16" 16 "Map-Version 17" 17 "Map-Version 18" 18 "Map-Version 19" 19 "Map-Version 20" 20 "Map-Version 21" 21 "Map-Version 22" 22 "Map-Version 23" 23 "Map-Version 24" 24 "Map-Version 25" 25 "Map-Version 26" 26 "Map-Version 27" 27 "Map-Version 28" 28 "Map-Version 29" 29 "Map database older than 29 years" 30 "Not_Available" 31 "Signal ungültig";
VAL_ 846 ST_VRS_MAP_NAVI_MANU 0 "NavTech" 1 "TeleAtlas" 2 "Zenrin" 3 "ADF" 4 "NavInfo" 5 "Reserviert" 6 "Signal nicht verfügbar" 7 "Signal ungültig";
VAL_ 846 ST_CNCD_NAVI 65535 "Signal ungültig";
VAL_ 555 PRMSN_DBC_TR_NIVI_THRV 0 "Defaultparametersatz DBC" 1 "leicht erhöhte Empfindlichkeit" 2 "erhöhte Empfindlichkeit" 3 "höchste Empfindlichkeit" 4 "Reserve" 13 "SIGNALTAG_FCTIF_NOT_AVAILABLE" 14 "SIGNALTAG_FCT_ERROR" 15 "Sendefunktion nicht in Betrieb";
VAL_ 555 PRF_NIVI_BRK 0 "Keine Prefill-Anforderung" 1 "Prefill-Anforderung" 5 "SIGNALTAG_FCTIF_NOT_AVAILABLE" 6 "SIGNALTAG_FCT_ERROR" 7 "Sendefunktion nicht in Betrieb";
VAL_ 555 ST_OBJ_SMPL_TYP_NIVI_2 0 "kein Objekt erkannt" 1 "Person erkannt" 2 "Tier erkannt" 3 "Signal ungültig";
VAL_ 555 ST_OBJ_SMPL_PROP_NIVI_2 0 "kein Gefährdungsgrad" 1 "Gefährdungsgrad niedrig" 2 "Gefährdungsgrad hoch" 3 "Signal ungültig";
VAL_ 555 ST_OBJ_FAR_MID_TYP_NIVI_2 0 "kein Objekt erkannt" 1 "Person erkannt" 2 "Tier erkannt" 3 "Signal ungültig";
VAL_ 555 ST_OBJ_FAR_MID_PROP_NIVI_2 0 "kein Gefährdungsgrad" 1 "Gefährdungsgrad niedrig" 2 "Gefährdungsgrad hoch" 3 "Signal ungültig";
VAL_ 555 ST_OBJ_NR_MID_TYP_NIVI_2 0 "kein Objekt erkannt" 1 "Person erkannt" 2 "Tier erkannt" 3 "Signal ungültig";
VAL_ 555 ST_OBJ_NR_MID_PROP_NIVI_2 0 "kein Gefährdungsgrad" 1 "Gefährdungsgrad niedrig" 2 "Gefährdungsgrad hoch" 3 "Signal ungültig";
VAL_ 555 ST_OBJ_ACRO_LH_TYP_NIVI_2 0 "kein Objekt erkannt" 1 "Person erkannt" 2 "Tier erkannt" 3 "Signal ungültig";
VAL_ 555 ST_OBJ_ACRO_LH_PROP_NIVI_2 0 "kein Gefährdungsgrad" 1 "Gefährdungsgrad niedrig" 2 "Gefährdungsgrad hoch" 3 "Signal ungültig";
VAL_ 555 ST_OBJ_ACRO_RH_TYP_NIVI_2 0 "kein Objekt erkannt" 1 "Person erkannt" 2 "Tier erkannt" 3 "Signal ungültig";
VAL_ 555 ST_OBJ_ACRO_RH_PROP_NIVI_2 0 "kein Gefährdungsgrad" 1 "Gefährdungsgrad niedrig" 2 "Gefährdungsgrad hoch" 3 "Signal ungültig";
VAL_ 555 ST_AWARN_NIVI 0 "Akutwarnung nicht aktiv" 2 "Akutwarnung aktiv" 3 "Ungültig";
VAL_ 555 ST_FLS_SYM_NIVI 0 "kein Blinken" 2 "Blinken des Symbols" 3 "Signal ungültig";
VAL_ 462 BNDRY_2_DOM_BOT_NGL_FLA 253 "SIGNALTAG_FCTIF_NOT_AVAILABLE" 254 "SIGNALTAG_FCT_ERROR" 255 "Sendefunktion nicht in Betrieb";
VAL_ 462 OBJ_2_DIST_FLA 253 "SIGNALTAG_FCTIF_NOT_AVAILABLE" 254 "SIGNALTAG_FCT_ERROR" 255 "Sendefunktion nicht in Betrieb";
VAL_ 462 ST_BNDRY_2_DOM_BOT_NGL_FLA 0 "No object detected (lower boundary not defined)" 1 "Lower boundary defined by preceding vehicle" 2 "Lower boundary defined by oncoming vehicle" 3 "Lower boundary signal invalid";
VAL_ 462 ST_BNDRY_2_DOM_NGL_LH_FLA 0 "No object detected (left boundary not defined)" 1 "Lower boundary defined by preceding vehicle" 2 "Lower boundary defined by oncoming vehicle" 3 "Lower boundary signal invalid";
VAL_ 462 ST_BNDRY_2_DOM_NGL_RH_FLA 0 "No object detected (right boundary not defined)" 1 "Lower boundary defined by preceding vehicle" 2 "Lower boundary defined by oncoming vehicle" 3 "Lower boundary signal invalid";
VAL_ 462 ST_OBJ_2_DIST_FLA 0 "No object detected (object range not defined)" 1 "Preceding vehicle detected" 2 "Oncoming vehicle detected" 3 "Object range signal invalid";
VAL_ 462 PRO_SBS_2_FLA 13 "SIGNALTAG_FCTIF_NOT_AVAILABLE" 14 "SIGNALTAG_FCT_ERROR" 15 "Sendefunktion nicht in Betrieb";
VAL_ 462 DIST_BNDRY_2_DOM_NGL_LH_FLA 253 "Hinweis: Reserviert für funktionale Kennung Signal-Tag." 254 "Hinweis: Reserviert für funktionale Kennung Signal-Tag." 255 "Sendefunktion nicht in Betrieb";
VAL_ 462 DIST_BNDRY_2_DOM_NGL_RH_FLA 253 "Hinweis: Reserviert für funktionale Kennung Signal-Tag." 254 "Hinweis: Reserviert für funktionale Kennung Signal-Tag." 255 "Sendefunktion nicht in Betrieb";
VAL_ 463 BNDRY_3_DOM_BOT_NGL_FLA 253 "SIGNALTAG_FCTIF_NOT_AVAILABLE" 254 "SIGNALTAG_FCT_ERROR" 255 "Sendefunktion nicht in Betrieb";
VAL_ 463 OBJ_3_DIST_FLA 253 "SIGNALTAG_FCTIF_NOT_AVAILABLE" 254 "SIGNALTAG_FCT_ERROR" 255 "Sendefunktion nicht in Betrieb";
VAL_ 463 ST_BNDRY_3_DOM_BOT_NGL_FLA 0 "No object detected (lower boundary not defined)" 1 "Lower boundary defined by preceding vehicle" 2 "Lower boundary defined by oncoming vehicle" 3 "Lower boundary signal invalid";
VAL_ 463 ST_BNDRY_3_DOM_NGL_LH_FLA 0 "No object detected (left boundary not defined)" 1 "Lower boundary defined by preceding vehicle" 2 "Lower boundary defined by oncoming vehicle" 3 "Lower boundary signal invalid";
VAL_ 463 ST_BNDRY_3_DOM_NGL_RH_FLA 0 "No object detected (right boundary not defined)" 1 "Lower boundary defined by preceding vehicle" 2 "Lower boundary defined by oncoming vehicle" 3 "Lower boundary signal invalid";
VAL_ 463 ST_OBJ_3_DIST_FLA 0 "No object detected (object range not defined)" 1 "Preceding vehicle detected" 2 "Oncoming vehicle detected" 3 "Object range signal invalid";
VAL_ 463 PRO_SBS_3_FLA 13 "SIGNALTAG_FCTIF_NOT_AVAILABLE" 14 "SIGNALTAG_FCT_ERROR" 15 "Sendefunktion nicht in Betrieb";
VAL_ 463 DIST_BNDRY_3_DOM_NGL_LH_FLA 253 "Hinweis: Reserviert für funktionale Kennung Signal-Tag." 254 "Hinweis: Reserviert für funktionale Kennung Signal-Tag." 255 "Sendefunktion nicht in Betrieb";
VAL_ 463 DIST_BNDRY_3_DOM_NGL_RH_FLA 253 "Hinweis: Reserviert für funktionale Kennung Signal-Tag." 254 "Hinweis: Reserviert für funktionale Kennung Signal-Tag." 255 "Sendefunktion nicht in Betrieb";
VAL_ 149 ST_BNDRY_DOM_BOT_NGL_FLA 0 "No object detected (lower boundary not defined)" 1 "Lower boundary defined by preceding vehicle" 2 "Lower boundary defined by oncoming vehicle" 3 "Lower boundary signal invalid";
VAL_ 149 ST_BNDRY_DOM_NGL_LH_FLA 0 "No object detected (left boundary not defined)" 1 "Lower boundary defined by preceding vehicle" 2 "Lower boundary defined by oncoming vehicle" 3 "Lower boundary signal invalid";
VAL_ 149 ST_BNDRY_DOM_NGL_RH_FLA 0 "No object detected (right boundary not defined)" 1 "Lower boundary defined by preceding vehicle" 2 "Lower boundary defined by oncoming vehicle" 3 "Lower boundary signal invalid";
VAL_ 149 ST_OBJ_DIST_FLA 0 "No object detected (object range not defined)" 1 "Preceding vehicle detected" 2 "Oncoming vehicle detected" 3 "Object range signal invalid";
VAL_ 149 PRO_SBS_FLA 13 "SIGNALTAG_FCTIF_NOT_AVAILABLE" 14 "SIGNALTAG_FCT_ERROR" 15 "Sendefunktion nicht in Betrieb";
VAL_ 149 DIST_BNDRY_DOM_NGL_LH_FLA 253 "Hinweis: Reserviert für funktionale Kennung Signal-Tag." 254 "Hinweis: Reserviert für funktionale Kennung Signal-Tag." 255 "Sendefunktion nicht in Betrieb";
VAL_ 149 DIST_BNDRY_DOM_NGL_RH_FLA 253 "Hinweis: Reserviert für funktionale Kennung Signal-Tag." 254 "Hinweis: Reserviert für funktionale Kennung Signal-Tag." 255 "Sendefunktion nicht in Betrieb";
VAL_ 393 QU_SER_OP_CCTR 33 "Service verfügbar: SZL aktiv" 34 "Service verfügbar: MFL aktiv" 48 "Reserved" 96 "Keine Kommunikation zu Line Slave durch Unter- Überspannung bzw. Kurzschluß der LIN Versorgungsspannung." 112 "Reserved" 128 "Tritt während der Initialisierungsphase auf bis Ist Wert verfügbar (Vorbefüllung)" 176 "Reserved" 224 "Reserved" 255 "Wird funktional nicht versendet";
VAL_ 938 OP_TZS_OFFS_MAN_UTC 252 "wird benutzt, falls sich ein oder mehrere andere Signale in dieser Botschaft ändern" 253 "SIGNALTAG_FCTIF_NOT_AVAILABLE" 254 "Hinweis: Reserviert für funktionale Kennung Signal-Tag." 255 "Sendefunktion nicht in Betrieb";
VAL_ 938 OP_TZS_OFFS_AUTOMLY_UTC 252 "wird benutzt, falls sich ein oder mehrere andere Signale in dieser Botschaft ändern" 253 "SIGNALTAG_FCTIF_NOT_AVAILABLE" 254 "Hinweis: Reserviert für funktionale Kennung Signal-Tag." 255 "Sendefunktion nicht in Betrieb";
VAL_ 938 OP_OFFS_WIT_SUT_UTC 12 "wird benutzt, falls sich ein oder mehrere andere Signale in dieser Botschaft ändern" 13 "SIGNALTAG_FCTIF_NOT_AVAILABLE" 14 "Hinweis: Reserviert für funktionale Kennung Signal-Tag." 15 "Sendefunktion nicht in Betrieb";
VAL_ 938 OP_CHB_T_ADJU_AUTOMLY_UTC 0 "Checkbox_Zeiteinstellung_automatisch_nicht_aktiv" 1 "Checkbox_Zeiteinstellung_automatisch_aktiv" 2 "wird benutzt, falls sich ein oder mehrere andere Signale in dieser Botschaft ändern" 3 "Sendefunktion nicht in Betrieb";
VAL_ 938 OP_TZS_ID_UTC 252 "Der Wert in diesem Signal hat sich nicht geändert." 253 "SIGNALTAG_FCTIF_NOT_AVAILABLE" 254 "SIGNALTAG_FCT_ERROR" 255 "Sendefunktion nicht in Betrieb";
VAL_ 939 OP_HR_WIT_SUT_CGVR 252 "Keine_Aenderung" 253 "SIGNALTAG_FCTIF_NOT_AVAILABLE" 254 "Hinweis: Reserviert für funktionale Kennung Signal-Tag." 255 "Sendefunktion nicht in Betrieb";
VAL_ 939 OP_MN_WIT_SUT_CGVR 252 "Keine_Aenderung" 253 "SIGNALTAG_FCTIF_NOT_AVAILABLE" 254 "Hinweis: Reserviert für funktionale Kennung Signal-Tag." 255 "Sendefunktion nicht in Betrieb";
VAL_ 939 OP_DATE_DAY_WIT_SUT_CGVR 252 "Keine_Aenderung" 253 "SIGNALTAG_FCTIF_NOT_AVAILABLE" 254 "Hinweis: Reserviert für funktionale Kennung Signal-Tag." 255 "Sendefunktion nicht in Betrieb";
VAL_ 939 OP_DATE_MON_WIT_SUT_CGVR 0 "Keine_Aenderung" 13 "SIGNALTAG_FCTIF_NOT_AVAILABLE" 14 "Hinweis: Reserviert für funktionale Kennung Signal-Tag." 15 "Sendefunktion nicht in Betrieb";
VAL_ 939 OP_DATE_YR_WIT_SUT_CGVR 65532 "Keine_Aenderung" 65533 "SIGNALTAG_FCTIF_NOT_AVAILABLE" 65534 "Hinweis: Reserviert für funktionale Kennung Signal-Tag." 65535 "Sendefunktion nicht in Betrieb";
VAL_ 939 OP_OFFS_NE_WIT_SUT 253 "SIGNALTAG_FCTIF_NOT_AVAILABLE" 254 "Hinweis: Reserviert für funktionale Kennung Signal-Tag." 255 "Sendefunktion nicht in Betrieb";
VAL_ 657 OP_LANG 0 "Keine Sprache" 1 "Deutsch" 2 "Englisch (UK)" 3 "Englisch (US)" 4 "Spanisch" 5 "Italienisch" 6 "Französisch" 7 "Flämisch" 8 "Niederländisch" 9 "Arabisch" 10 "Chinesisch Traditionell" 11 "Chinesisch Simple" 12 "Koreanisch" 13 "Japanisch" 14 "Russisch" 15 "Französisch (CA)" 16 "Spanisch (US)" 17 "Portugiesisch" 18 "Polnisch" 19 "Griechisch" 20 "Türkisch" 21 "Ungarisch" 22 "Rumänisch" 23 "Schwedisch" 24 "Portugiesisch (BR)" 25 "Es handelt sich bei dieser Codierung um einen Vorhalt für die Sprachverarbeitung. Die Sprache ist nicht für die Anzeige vorgesehen." 26 "Es handelt sich bei dieser Codierung um einen Vorhalt für die Sprachverarbeitung. Die Sprache ist nicht für die Anzeige vorgesehen." 27 "Ab BN2020 gültig" 28 "Ab BN2020 gültig" 29 "Ab BN2020 gültig" 30 "Ab BN2020 gültig" 31 "Ab BN2020 gültig" 32 "Ab BN2020 gültig" 33 "Indonesisch" 34 "Thai" 35 "Hebraeisch_Ivrit" 36 "Vietnamesisch" 37 "Ukrainisch" 255 "Signal ungültig";
VAL_ 657 OP_UN_DATE 0 "Default = Keine Angabe" 1 "Reihenfolge: Tag.Monat.Jahr" 2 "Reihenfolge: Monat/Tag/Jahr" 3 "Signal ungültig";
VAL_ 657 OP_UN_SPDM_DGTL 0 "Default = Keine Angabe" 1 "Kilometer" 2 "Meilen" 3 "Signal ungültig";
VAL_ 657 OP_UN_COSP 0 "Default = Keine Angabe" 1 "l/100km" 2 "mpg (UK)" 3 "mpg (US)" 4 "km/l" 7 "Signal ungültig";
VAL_ 657 OP_UN_FU 0 "Default = Keine Angabe" 1 "Liter" 2 "Galonen (UK)" 3 "Galonen (US)" 7 "Signal ungültig";
VAL_ 657 OP_UN_DATE_EXT 0 "Default = Keine Änderung" 1 "ECE" 2 "US" 3 "Reihenfolge: Tag/Monat/Jahr" 4 "Reihenfolge: Tag-Monat-Jahr" 5 "Arabien" 6 "Asien" 7 "Reihenfolge: Jahr-Monat-Tag" 31 "Signal ungültig";
VAL_ 657 OP_UN_PWR_S_MOD 0 "Default = Keine Angabe" 1 "Kilowatt" 2 "Pferdestärken" 15 "Signal ungültig";
VAL_ 657 OP_UN_TORQ_S_MOD 0 "Default = Keine Angabe" 1 "Nm" 2 "lb-ft" 3 "kgm" 15 "Signal ungültig";
VAL_ 657 OP_UN_COSP_EL 0 "Default = Keine Angabe" 1 "kWh / 100km" 2 "mi / kWh" 3 "Km / kWh" 4 "wird nur in SP2013 (ohne 444, F15-F16, UKL) verwendet" 5 "wird nur in SP2013 (ohne 444, F15-F16, UKL) verwendet" 6 "Gilt ab SP2015" 15 "Signal ungültig";
VAL_ 801 BRIG_OFFS_HUD_3 0 "Nur in Bedienrichtung verwenden" 1 "minimaler Helligkeitsoffset" 2 "Helligkeitsoffset Zwischenstufe" 3 "Helligkeitsoffset Zwischenstufe" 4 "Helligkeitsoffset Zwischenstufe" 5 "Helligkeitsoffset Zwischenstufe" 6 "Helligkeitsoffset Zwischenstufe" 7 "Helligkeitsoffset Zwischenstufe" 8 "Helligkeitsoffset Zwischenstufe" 9 "Helligkeitsoffset Zwischenstufe" 10 "Helligkeitsoffset Zwischenstufe" 11 "kein Helligkeitsoffset" 12 "Helligkeitsoffset Zwischenstufe" 13 "Helligkeitsoffset Zwischenstufe" 14 "Helligkeitsoffset Zwischenstufe" 15 "Helligkeitsoffset Zwischenstufe" 16 "Helligkeitsoffset Zwischenstufe" 17 "Helligkeitsoffset Zwischenstufe" 18 "Helligkeitsoffset Zwischenstufe" 19 "Helligkeitsoffset Zwischenstufe" 20 "Helligkeitsoffset Zwischenstufe" 21 "maximaler Helligkeitsoffset" 31 "Sendefunktion nicht in Betrieb";
VAL_ 801 STAN_HUD 0 "Keine Darstellung im HUD" 1 "Darstellung im HUD" 2 "Darstellung im HUD" 3 "Darstellung im HUD" 6 "Nur in Bedienrichtung verwenden" 7 "Signal ungültig";
VAL_ 801 HGAD_HUD_3 0 "Nur in Bedienrichtung verwenden" 1 "Bildlage Anschlag Unten" 2 "Bildlage Zwischenstufe" 3 "Bildlage Zwischenstufe" 4 "Bildlage Zwischenstufe" 5 "Bildlage Zwischenstufe" 6 "Bildlage Zwischenstufe" 7 "Bildlage Zwischenstufe" 8 "Bildlage Zwischenstufe" 9 "Bildlage Zwischenstufe" 10 "Bildlage Zwischenstufe" 11 "Bildlage Mitte" 12 "Bildlage Zwischenstufe" 13 "Bildlage Zwischenstufe" 14 "Bildlage Zwischenstufe" 15 "Bildlage Zwischenstufe" 16 "Bildlage Zwischenstufe" 17 "Bildlage Zwischenstufe" 18 "Bildlage Zwischenstufe" 19 "Bildlage Zwischenstufe" 20 "Bildlage Zwischenstufe" 21 "Bildlage Anschlag Oben" 31 "Sendefunktion nicht in Betrieb";
VAL_ 801 OP_SLCTN_RDOBUT_HUD 0 "Wird in M Fahrzeugen nicht verwendet." 1 "Wird in M Fahrzeugen nicht verwendet." 2 "In M Fahrzeugen Comfort" 3 "In M Fahrzeugen M Ansicht" 6 "Nur in Bedienrichtung verwenden" 7 "Sendefunktion nicht in Betrieb";
VAL_ 801 ROTA_HUD 0 "Nur in Bedienrichtung verwenden" 1 "maximale Drehung gegen Uhrzeigersinn" 2 "Drehung Zwischenstufe" 3 "Drehung Zwischenstufe" 4 "Drehung Zwischenstufe" 5 "Drehung Zwischenstufe" 6 "Drehung Zwischenstufe" 7 "Drehung Zwischenstufe" 8 "Drehung Zwischenstufe" 9 "Drehung Zwischenstufe" 10 "Drehung Zwischenstufe" 11 "Keine Drehung" 12 "Drehung Zwischenstufe" 13 "Drehung Zwischenstufe" 14 "Drehung Zwischenstufe" 15 "Drehung Zwischenstufe" 16 "Drehung Zwischenstufe" 17 "Drehung Zwischenstufe" 18 "Drehung Zwischenstufe" 19 "Drehung Zwischenstufe" 20 "Drehung Zwischenstufe" 21 "maximale Drehung im Uhrzeigersinn" 31 "Signal ungültig";
VAL_ 801 OP_S_DISP_HUD 0 "Nur in Bedienrichtung verwenden" 1 "Listeneintrag \"aus\"" 2 "Listeneintrag \"im SPORT-Modus\"" 3 "Listeneintrag \"in der S-Gasse\"" 4 "Listeneintrag \"in SPORT-Modus & S-Gasse\"" 5 "Listeneintrag \"permanent\"" 15 "Sendefunktion nicht in Betrieb";
VAL_ 801 OperationAdditionalDisplayHUD 0 "Keine_Aenderung" 1 "Listeneintrag \"aus\"" 2 "Listeneintrag \"Automatisch\"" 3 "Listeneintrag \"FAS Anzeige permanent\"" 4 "Listeneintrag \"Sport Anzeige permanent\"" 5 "Listeneintrag \"Xoffroad Anzeige permanent\"" 6 "Hinweis: Reserviert für funktionale Kennung Signal-Tag" 7 "Sendefunktion nicht in Betrieb";
VAL_ 880 OP_ECO_FN_ECS_DXP 0 "ECO-Geschwindigkeitshinweis nicht aktiv" 1 "ECO-Geschwindigkeitshinweis aktiv" 3 "Signal ungültig";
VAL_ 880 OP_ECO_FN_FRSG_ASST_DXP 0 "Verzögerungshinweise nicht anzeigen" 1 "Verzögerungshinweise anzeigen" 3 "Signal ungültig";
VAL_ 880 OP_IDVL_RST_DISP_DXP 0 "kein Reset" 1 "Wiederherstellung der Werkseinstellungen für \"Sport Individual\"" 2 "Wiederherstellung der Werkseinstellungen für \"ECO Pro Individual\"" 15 "Sendefunktion nicht in Betrieb";
VAL_ 880 OP_ECO_FN_ECT_DXP 0 "ECO Tipps nicht anzeigen" 1 "ECO Tipps anzeigen" 3 "Signal ungültig";
VAL_ 892 OP_ECO_FN_SAIL_DXP 0 "Segeln Aus" 1 "Segeln An" 3 "Signal ungültig";
VAL_ 892 OP_ECO_FN_MSA_DXP 0 "MSA wird bei Wechsel in ECO PRO INDIVUDIUAL nicht zwangsaktiviert." 1 "MSA wird bei Wechsel in ECO PRO INDIVUDIUAL zwangsaktiviert." 3 "Signal ungültig";
VAL_ 892 OP_S_FN_SHA_DXP 0 "Schaltassistent nicht aktiv" 1 "Schaltassistent aktiv" 15 "Signal ungültig";
VAL_ 892 OP_S_CLU_RPM_PA_DXP 1 "Normal (B)" 2 "Sport (S)" 3 "Race (SE)" 15 "Signal ungültig";
VAL_ 892 OP_S_CLUG_ENG_DXP 1 "Normal (B)" 2 "Sport (S)" 3 "Race (SE)" 15 "Signal ungültig";
VAL_ 892 OP_IDVL_RST_DRV_DXP 0 "kein Reset" 1 "Wiederherstellung der Werkseinstellungen für \"Sport Individual\"" 2 "Wiederherstellung der Werkseinstellungen für \"ECO Pro Individual\"" 15 "Sendefunktion nicht in Betrieb";
VAL_ 892 OP_ADJU_SAIL_VEH 0 "Segeln_nicht_erlaubt" 1 "Segeln_erlaubt" 3 "Sendefunktion nicht in Betrieb";
VAL_ 892 OperationAdjustEngineSoundVehicl 0 "Initiale Einstellung" 1 "Motorsound_sportlich" 2 "Motorsound_komfortabel" 3 "Motorsound_zurueckhaltend" 4 "Nur in Bedienrichtung zu verwenden" 5 "Neu: Funktionswerte ID8" 6 "Neu: Funktionswerte ID8" 7 "Neu: Funktionswerte ID8" 8 "Neu: Funktionswerte ID8" 9 "Neu: Funktionswerte ID8 (z.B. Thrill)" 10 "Neu: Funktionswerte ID8" 13 "Reserviert für funktionale Kennung Signal-Tag" 14 "Reserviert für funktionale Kennung Signal-Tag" 15 "Sendefunktion nicht in Betrieb";
VAL_ 745 OP_PUBU_EVEH 0 "keine Betätigung" 1 "Tastendruck EV Taster oder erste Bedienrichtung bei PHEV Fahrzeugen mit Ausführung des EV Taster als Wippe." 2 "Zweite Bedienrichtung bei PHEV Fahrzeugen mit Ausführung des EV Taster als Wippe." 3 "Signal ungültig";
VAL_ 651 OP_PUBU_HUD 0 "Keine Betätigung" 1 "Taster gedrückt" 3 "Signal ungültig";
VAL_ 604 OP_PUBU_LVCH 0 "Keine Betätigung" 1 "DOWN  CHANGE" 2 "UP" 13 "Hinweis: Reserviert für funktionale Kennung Signal-Tag." 14 "SIGNALTAG_FCT_ERROR" 15 "Sendefunktion nicht in Betrieb";
VAL_ 604 OP_PUBU_KEY 0 "Tastenbetätigung zur Auslösung Niveauabsenkung nicht ausgelöst" 1 "Tastenbetätigung zur Auslösung Niveauabsenkung ausgelöst" 3 "Sendefunktion nicht in Betrieb";
VAL_ 650 OP_PUBU_NIVI 0 "Keine Betätigung" 1 "Taster gedrückt" 3 "Signal ungültig";
VAL_ 609 OP_STW_OPEL_2 0 "Keine_Betaetigung" 1 "Taster_gedrueckt" 13 "Hinweis: Reserviert für funktionale Kennung Signal-Tag." 14 "SIGNALTAG_FCT_ERROR" 15 "Sendefunktion nicht in Betrieb";
VAL_ 609 OP_STW_OPEL_3 0 "Keine_Betaetigung" 1 "Taster_gedrueckt" 13 "Hinweis: Reserviert für funktionale Kennung Signal-Tag." 14 "SIGNALTAG_FCT_ERROR" 15 "Sendefunktion nicht in Betrieb";
VAL_ 727 OP_CHGNG_I_LIM_MOD_2 253 "Hinweis: Reserviert für funktionale Kennung Signal-Tag" 254 "Hinweis: Reserviert für funktionale Kennung Signal-Tag" 255 "Sendefunktion nicht in Betrieb";
VAL_ 727 PopUpConfirmation 0 "Keine_Aktion" 1 "Bestaetigt_durch_Kunde" 2 "Abgebrochen_durch_Kunde" 3 "Kunde_springt_in_Einstellungen" 4 "Abgebrochen_durch_HMI_oder_keine_Kundenaktion" 5 "Anzeige_verweigert" 13 "SIGNALTAG_FCTIF_NOT_AVAILABLE" 14 "SIGNALTAG_FCT_ERROR" 15 "Sendefunktion nicht in Betrieb";
VAL_ 727 OperationChargingCurrentLimitMod 0 "Keine_Aktion" 1 "Aktion" 3 "Sendefunktion nicht in Betrieb";
VAL_ 1051 OP_ACTVN_KI_BC 0 "Keine Anzeige" 1 "Anzeige Haken Navigation Ankunftszeit und Entfernung zum Ziel" 2 "Anzeige Haken Reichweite Verbrenner" 4 "Anzeige Haken Gesamt-Reichweite" 8 "Anzeige Haken Reichweite elektrisch (Vorhalt BEV)" 16 "Anzeige Haken Reichweite elektrisch und Reichweite Verbrenner" 32 "Anzeige Haken Reichweitenpotential" 64 "Anzeige Haken Momentanverbrauch Verbrenner und Durchschnittsverbrauch Verbrenner" 128 "Anzeige Haken KVA/EVA eDrive abhaengig" 256 "Anzeige Haken Durchschnittsgeschwindigkeit und Durchschnittsverbrauch" 512 "Anzeige Haken Motortemperatur" 1024 "Anzeige Haken Efficient Dynamics Anzeige" 2048 "Anzeige M-GmbH M-Panel" 131072 "Anzeige Haken State of Charge, SOC" 1048576 "Anzeige Haken Kompass" 2097152 "Anzeige Haken eCounter und Durchschnittsverbrauch Verbrenner" 4194304 "Lifetime_Durchschnitts_und_Momentan_Verbrauch" 1073741824 "Nur in Bedienrichtung verwenden" 4294967295 "Signal ungültig";
VAL_ 1051 OP_ACTVN_KI_CONT 0 "Keine Anzeige" 1 "Anzeige Haken Fahrmodusansicht" 2 "Anzeige Haken Navigation Streckenübersicht" 4 "Anzeige Haken Zusatzschild Verkehrszeichenerkennung" 8 "Anzeige Haken Tachozeigerband für Tempolimit" 16 "Anzeige Haken Lupen Effekt Tacho" 32 "Anzeige Haken SPA" 64 "Popup" 128 "Anzeige Haken Digital-Geschwindigkeit" 256 "Anzeige Haken Analoge Uhr" 512 "Anzeige_Haken_Shiftlights" 1024 "Anzeige_Haken_Navigation" 2048 "Anzeige_Haken_Verkehrszeichenerkennung" 4096 "Anzeige_Haken_M_Drive_Inszenierung" 16384 "Nur in Bedienrichtung verwenden" 65535 "Signal ungültig";
VAL_ 1051 OP_ACTVN_PRESL_KI 0 "Diesen Radiobutton als ausgewählt darstellen" 1 "Diesen Radiobutton als ausgewählt darstellen" 2 "Diesen Radiobutton als ausgewählt darstellen" 14 "Nur in Bedienrichtung verwenden" 15 "Signal ungültig";
VAL_ 1051 BRIG_OFFS_KI 0 "Nur in Bedienrichtung verwenden" 1 "minimaler Helligkeitsoffset" 2 "Helligkeitsstufe -9" 3 "Helligkeitsstufe -8" 4 "Helligkeitsstufe -7" 5 "Helligkeitsstufe -6" 6 "Helligkeitsstufe -5" 7 "Helligkeitsstufe -4" 8 "Helligkeitsstufe -3" 9 "Helligkeitsstufe -2" 10 "Helligkeitsstufe -1" 11 "kein Helligkeitsoffset" 12 "Helligkeitsstufe 1" 13 "Helligkeitsstufe 2" 14 "Helligkeitsstufe 3" 15 "Helligkeitsstufe 4" 16 "Helligkeitsstufe 5" 17 "Helligkeitsstufe 6" 18 "Helligkeitsstufe 7" 19 "Helligkeitsstufe 8" 20 "Helligkeitsstufe 9" 21 "maximaler Helligkeitsoffset" 31 "Signal ungültig";
VAL_ 974 OP_NAVI_DISP_TYP 0 "Diesen Radiobutton als ausgewählt darstellen" 1 "Diesen Radiobutton als ausgewählt darstellen" 2 "Diesen Radiobutton als ausgewählt darstellen" 3 "Diesen Radiobutton als ausgewählt darstellen" 14 "Nur in Bedienrichtung verwenden" 15 "Sendefunktion nicht in Betrieb";
VAL_ 974 BRIG_OFFS_KI_2 0 "Nur in Bedienrichtung verwenden" 1 "minimaler Helligkeitsoffset" 2 "Helligkeitsstufe_Minus_9" 3 "Helligkeitsstufe_Minus_8" 4 "Helligkeitsstufe_Minus_7" 5 "Helligkeitsstufe_Minus_6" 6 "Helligkeitsstufe_Minus_5" 7 "Helligkeitsstufe_Minus_4" 8 "Helligkeitsstufe_Minus_3" 9 "Helligkeitsstufe_Minus_2" 10 "Helligkeitsstufe_Minus_1" 11 "kein Helligkeitsoffset" 12 "Helligkeitsstufe_Plus_1" 13 "Helligkeitsstufe_Plus_2" 14 "Helligkeitsstufe_Plus_3" 15 "Helligkeitsstufe_Plus_4" 16 "Helligkeitsstufe_Plus_5" 17 "Helligkeitsstufe_Plus_6" 18 "Helligkeitsstufe_Plus_7" 19 "Helligkeitsstufe_Plus_8" 20 "Helligkeitsstufe_Plus_9" 21 "maximaler Helligkeitsoffset" 31 "Sendefunktion nicht in Betrieb";
VAL_ 974 OP_ENTAI_ECU_DISP 0 "Diesen Radiobutton als ausgewählt darstellen" 1 "Diesen Radiobutton als ausgewählt darstellen" 6 "Nur in Bedienrichtung verwenden" 7 "Sendefunktion nicht in Betrieb";
VAL_ 974 OperationDZMorPowermeterDisplay 0 "Nur in Bedienrichtung verwenden" 1 "Diesen Radiobutton als ausgewählt darstellen Drehzahlmesser" 2 "Diesen Radiobutton als ausgewählt darstellen Powermeter" 15 "Signal_unbefuellt";
VAL_ 850 OP_SU_SAMD_EVEH 0 "MaxEDrive_nicht_als_Aufstartmodus_gewaehlt" 1 "MaxEDrive_als_Aufstartmodus_gewaehlt" 3 "Sendefunktion nicht in Betrieb";
VAL_ 850 OP_SU_RECUP_LEV 0 "Keine_Option_ausgewaehlt" 1 "Automatische_Einstellung" 2 "Darf nur in Bedienrichtung verwendet werden." 3 "Beschreibung G08BEV und F56BEV: Rekuperationsniveau 1 mit betraglich geringste Verzögerung" 4 "Beschreibung G08BEV und F56BEV: Rekuperationsniveau 2 mit betraglich höherer Verzögerung als Rekuniveau 1, Jedes weitere Rekuniveau bedeutet betragliche Erhöhrung der Verzögerung" 5 "Rekuniveau_3" 13 "SIGNALTAG_FCTIF_NOT_AVAILABLE" 14 "SIGNALTAG_FCT_ERROR" 15 "Sendefunktion nicht in Betrieb";
VAL_ 850 OP_ADJU_VEM_VEH 0 "VEM_nicht_aktiv_gewaehlt" 1 "VEM_aktiv_gewaehlt" 3 "Sendefunktion nicht in Betrieb";
VAL_ 850 OperationChargeControlPlug 0 "Darf nur in Bedienrichtung verwendet werden" 1 "Ladestecker_entriegeln_1" 2 "Ladestecker_entriegeln_2" 3 "Sendefunktion nicht in Betrieb";
VAL_ 850 OperationAcCurrentLimit 0 "Ladebegrenzung_nicht_ausgewaehlt" 1 "Ladebegrenzung_ausgewaehlt" 2 "Keine_Aktion" 13 "SIGNALTAG_FCTIF_NOT_AVAILABLE" 14 "SIGNALTAG_FCT_ERROR" 15 "Sendefunktion nicht in Betrieb";
VAL_ 611 OP_SMOR_ATZ 0 "Nicht betätigt" 1 "ID-Geber im Heckbereich vorhanden" 3 "Signal ungültig";
VAL_ 1026 PIA_FN_ID_DT_INQY 4095 "Signal ungültig";
VAL_ 1026 PIA_PROFIL_NO_DT_INQY 0 "Benutzerprofil 0" 1 "Benutzerprofil 1" 2 "Benutzerprofil 2" 3 "Gilt ab SP2021 (exklusive SP2021R)" 4 "Gilt ab SP2021 (exklusive SP2021R)" 5 "Gilt ab SP2021 (exklusive SP2021R)" 6 "Gilt ab SP2021 (exklusive SP2021R)" 10 "Gastprofil" 14 "Defaultprofil" 15 "Werkstattprofil bzw. ungültiges Profil";
VAL_ 1027 PIA_FN_ID_DT_SET 4095 "Signal ungültig";
VAL_ 1027 PIA_PROFIL_NO_DT_SET 0 "Benutzerprofil 0" 1 "Benutzerprofil 1" 2 "Benutzerprofil 2" 3 "Gilt ab SP2021 (exklusive SP2021R)" 4 "Gilt ab SP2021 (exklusive SP2021R)" 5 "Gilt ab SP2021 (exklusive SP2021R)" 6 "Gilt ab SP2021 (exklusive SP2021R)" 10 "Gastprofil" 14 "Defaultprofil" 15 "Werkstattprofil bzw. ungültiges Profil";
VAL_ 1030 PIA_FN_ID_SU 4095 "Signal ungültig";
VAL_ 1030 PIA_ST_INQY 1 "KonfigurationAnfrage" 2 "KonfigurationAntwortAcknowledge" 3 "ungültig";
VAL_ 1032 PIA_ST_TRANA 1 "BeginTransaction" 2 "EndTransaction";
VAL_ 950 ST_PO_WRG_DRD 0 "Fenster geschlossen" 1 "Zwischenstellung" 2 "Fenster offen" 3 "Signal ungültig";
VAL_ 950 ST_DRV_WRG_DRD 0 "FH-Antrieb steht" 1 "FH-Antrieb fährt in Richtung Öffnen" 2 "FH-Antrieb fährt in Richtung Schließen" 3 "Signal ungültig";
VAL_ 713 DISP_POSI_IDT_CHGNG 0 "Anzeige_nicht_aktiv" 1 "Anzeige_aktiv" 3 "Sendefunktion nicht in Betrieb";
VAL_ 947 SLCTN_SPCOS 0 "Kein Sonderverbraucher ausgewählt" 1 "PTC-Zuheizer" 15 "Signal ungültig";
VAL_ 947 CTR_PWRU_COS 0 "Keine_Aktion" 1 "Verbrauchergruppe_1_ein" 2 "Verbrauchergruppe_2_ein" 4 "Verbrauchergruppe_3_ein" 13 "SIGNALTAG_FCTIF_NOT_AVAILABLE" 14 "SIGNALTAG_FCT_ERROR" 15 "Sendefunktion nicht in Betrieb";
VAL_ 947 ST_ENERG_PWMG 1 "Abschalten der  Kl 30 F" 2 "Keine Standverbraucher  zulässig" 4 "Bordnetzzustand gut" 8 "Batterieladezustand 100 %" 15 "Signal ungültig";
VAL_ 947 CTR_AUXC 0 "Kein zusätzlicher Verbraucher angefordert" 1 "Mindestens 2kW elektrische Verbraucherleistung angefordert" 2 "zusätzliche mechanische Verbraucherleistung angefordert" 3 "Signal ungültig";
VAL_ 511 ACLN_PVE 253 "SIGNALTAG_FCTIF_NOT_AVAILABLE" 254 "SIGNALTAG_FCT_ERROR" 255 "Sendefunktion nicht in Betrieb";
VAL_ 511 ACLN_PVE_ERR_AMP 253 "SIGNALTAG_FCTIF_NOT_AVAILABLE" 254 "SIGNALTAG_FCT_ERROR" 255 "Sendefunktion nicht in Betrieb";
VAL_ 511 ACLNX_MAX_PVE 253 "SIGNALTAG_FCTIF_NOT_AVAILABLE" 254 "SIGNALTAG_FCT_ERROR" 255 "Sendefunktion nicht in Betrieb";
VAL_ 511 MILE_LRN_ACLN_PVE 253 "SIGNALTAG_FCTIF_NOT_AVAILABLE" 254 "SIGNALTAG_FCT_ERROR" 255 "Sendefunktion nicht in Betrieb";
VAL_ 385 ShortTermStandStillProbability 253 "SIGNALTAG_FCTIF_NOT_AVAILABLE" 254 "SIGNALTAG_FCT_ERROR" 255 "Sendefunktion nicht in Betrieb";
VAL_ 385 PredictedLocation 0 "OTHER" 1 "PARKING_DECK" 2 "PARKING_GROUND" 3 "CLOSED_BUILDING" 4 "TOLL_STATION" 5 "DRIVE_IN" 6 "CARWASH_TUNNEL" 7 "CARWASH_BOX" 8 "CARWASH_HANDJOB" 9 "FUEL_SERVICE" 10 "RESERVED1" 11 "RESERVED2" 63 "Sendefunktion nicht in Betrieb";
SIG_GROUP_ 101 e2eGrp_INFO_VEH_DRV 1 : CRC_INFO_VEH_DRV ALIV_INFO_VEH_DRV CHL_INFO_VEH_DRV RQ_FN_DRV ST_BL_SW ST_CLT_SW ST_MSA_PUBU ST_OP_SSP ST_GPWSUP_STRT INFO_VEH_DRV_dummy_32_63;
SIG_GROUP_ 303 e2eGrp_KLEMMEN 1 : CRC_KL ALIV_COU_KL ST_VEH_CON ST_KL KLEMMEN_dummy_20_23 ST_KL_30B ST_KL_15N KLEMMEN_dummy_32_55 ST_KL_DBG;
SIG_GROUP_ 699 e2eGrp_MILE_VEH 1 : CRC_MILE_VEH ALIV_MILE_VEH MILE_VEH_dummy_12_15 MILE_VEH QU_MILE_VEH MILE_VEH_dummy_36_39;
SIG_GROUP_ 609 e2eGrp_OP_STW 1 : CRC_OP_STW ALIV_OP_STW CHL_OP_STW OP_STW_OPEL_2 OP_STW_OPEL_3 OP_STW_dummy_24_31 OP_STW_dummy_32_63;
SIG_GROUP_ 1026 signalGrp_PIA_DT_INQY 1 : PIA_FN_ID_DT_INQY PIA_PROFIL_NO_DT_INQY;
SIG_GROUP_ 1027 signalGrp_PIA_DT_SET 1 : PIA_FN_ID_DT_SET PIA_PROFIL_NO_DT_SET PIA_VL_DT_SET;
SIG_GROUP_ 1030 signalGrp_PIA_SU 1 : PIA_FN_ID_SU PIA_ST_INQY;
